VERSION ""

NS_ :

BS_:

BU_: Vector__XXX

BO_ 640 AFE_CellTemperatures: 8 Vector__XXX
SG_ AFE_CellTemperatures_Mux M : 7|8@0+ (1,0) [0|0] "" Vector__XXX
SG_ CellTemperature_000_invalidFlag m0 : 8|1@0+ (1,0) [0|1] "" Vector__XXX
SG_ CellTemperature_001_invalidFlag m0 : 9|1@0+ (1,0) [0|1] "" Vector__XXX
SG_ CellTemperature_002_invalidFlag m0 : 10|1@0+ (1,0) [0|1] "" Vector__XXX
SG_ CellTemperature_003_invalidFlag m0 : 11|1@0+ (1,0) [0|1] "" Vector__XXX
SG_ CellTemperature_004_invalidFlag m0 : 12|1@0+ (1,0) [0|1] "" Vector__XXX
SG_ CellTemperature_005_invalidFlag m0 : 13|1@0+ (1,0) [0|1] "" Vector__XXX
SG_ CellTemperature_000 m0 : 23|8@0- (1,0) [-128|127] "degC" Vector__XXX
SG_ CellTemperature_001 m0 : 31|8@0- (1,0) [-128|127] "degC" Vector__XXX
SG_ CellTemperature_002 m0 : 39|8@0- (1,0) [-128|127] "degC" Vector__XXX
SG_ CellTemperature_003 m0 : 47|8@0- (1,0) [-128|127] "degC" Vector__XXX
SG_ CellTemperature_004 m0 : 55|8@0- (1,0) [-128|127] "degC" Vector__XXX
SG_ CellTemperature_005 m0 : 63|8@0- (1,0) [-128|127] "degC" Vector__XXX
SG_ CellTemperature_006_invalidFlag m1 : 8|1@0+ (1,0) [0|1] "" Vector__XXX
SG_ CellTemperature_007_invalidFlag m1 : 9|1@0+ (1,0) [0|1] "" Vector__XXX
SG_ CellTemperature_008_invalidFlag m1 : 10|1@0+ (1,0) [0|1] "" Vector__XXX
SG_ CellTemperature_009_invalidFlag m1 : 11|1@0+ (1,0) [0|1] "" Vector__XXX
SG_ CellTemperature_010_invalidFlag m1 : 12|1@0+ (1,0) [0|1] "" Vector__XXX
SG_ CellTemperature_011_invalidFlag m1 : 13|1@0+ (1,0) [0|1] "" Vector__XXX
SG_ CellTemperature_006 m1 : 23|8@0- (1,0) [-128|127] "degC" Vector__XXX
SG_ CellTemperature_007 m1 : 31|8@0- (1,0) [-128|127] "degC" Vector__XXX
SG_ CellTemperature_008 m1 : 39|8@0- (1,0) [-128|127] "degC" Vector__XXX
SG_ CellTemperature_009 m1 : 47|8@0- (1,0) [-128|127] "degC" Vector__XXX
SG_ CellTemperature_010 m1 : 55|8@0- (1,0) [-128|127] "degC" Vector__XXX
SG_ CellTemperature_011 m1 : 63|8@0- (1,0) [-128|127] "degC" Vector__XXX
SG_ CellTemperature_012_invalidFlag m2 : 8|1@0+ (1,0) [0|1] "" Vector__XXX
SG_ CellTemperature_013_invalidFlag m2 : 9|1@0+ (1,0) [0|1] "" Vector__XXX
SG_ CellTemperature_014_invalidFlag m2 : 10|1@0+ (1,0) [0|1] "" Vector__XXX
SG_ CellTemperature_015_invalidFlag m2 : 11|1@0+ (1,0) [0|1] "" Vector__XXX
SG_ CellTemperature_016_invalidFlag m2 : 12|1@0+ (1,0) [0|1] "" Vector__XXX
SG_ CellTemperature_017_invalidFlag m2 : 13|1@0+ (1,0) [0|1] "" Vector__XXX
SG_ CellTemperature_012 m2 : 23|8@0- (1,0) [-128|127] "degC" Vector__XXX
SG_ CellTemperature_013 m2 : 31|8@0- (1,0) [-128|127] "degC" Vector__XXX
SG_ CellTemperature_014 m2 : 39|8@0- (1,0) [-128|127] "degC" Vector__XXX
SG_ CellTemperature_015 m2 : 47|8@0- (1,0) [-128|127] "degC" Vector__XXX
SG_ CellTemperature_016 m2 : 55|8@0- (1,0) [-128|127] "degC" Vector__XXX
SG_ CellTemperature_017 m2 : 63|8@0- (1,0) [-128|127] "degC" Vector__XXX
SG_ CellTemperature_018_invalidFlag m3 : 8|1@0+ (1,0) [0|1] "" Vector__XXX
SG_ CellTemperature_019_invalidFlag m3 : 9|1@0+ (1,0) [0|1] "" Vector__XXX
SG_ CellTemperature_020_invalidFlag m3 : 10|1@0+ (1,0) [0|1] "" Vector__XXX
SG_ CellTemperature_021_invalidFlag m3 : 11|1@0+ (1,0) [0|1] "" Vector__XXX
SG_ CellTemperature_022_invalidFlag m3 : 12|1@0+ (1,0) [0|1] "" Vector__XXX
SG_ CellTemperature_023_invalidFlag m3 : 13|1@0+ (1,0) [0|1] "" Vector__XXX
SG_ CellTemperature_018 m3 : 23|8@0- (1,0) [-128|127] "degC" Vector__XXX
SG_ CellTemperature_019 m3 : 31|8@0- (1,0) [-128|127] "degC" Vector__XXX
SG_ CellTemperature_020 m3 : 39|8@0- (1,0) [-128|127] "degC" Vector__XXX
SG_ CellTemperature_021 m3 : 47|8@0- (1,0) [-128|127] "degC" Vector__XXX
SG_ CellTemperature_022 m3 : 55|8@0- (1,0) [-128|127] "degC" Vector__XXX
SG_ CellTemperature_023 m3 : 63|8@0- (1,0) [-128|127] "degC" Vector__XXX
SG_ CellTemperature_024_invalidFlag m4 : 8|1@0+ (1,0) [0|1] "" Vector__XXX
SG_ CellTemperature_025_invalidFlag m4 : 9|1@0+ (1,0) [0|1] "" Vector__XXX
SG_ CellTemperature_026_invalidFlag m4 : 10|1@0+ (1,0) [0|1] "" Vector__XXX
SG_ CellTemperature_027_invalidFlag m4 : 11|1@0+ (1,0) [0|1] "" Vector__XXX
SG_ CellTemperature_028_invalidFlag m4 : 12|1@0+ (1,0) [0|1] "" Vector__XXX
SG_ CellTemperature_029_invalidFlag m4 : 13|1@0+ (1,0) [0|1] "" Vector__XXX
SG_ CellTemperature_024 m4 : 23|8@0- (1,0) [-128|127] "degC" Vector__XXX
SG_ CellTemperature_025 m4 : 31|8@0- (1,0) [-128|127] "degC" Vector__XXX
SG_ CellTemperature_026 m4 : 39|8@0- (1,0) [-128|127] "degC" Vector__XXX
SG_ CellTemperature_027 m4 : 47|8@0- (1,0) [-128|127] "degC" Vector__XXX
SG_ CellTemperature_028 m4 : 55|8@0- (1,0) [-128|127] "degC" Vector__XXX
SG_ CellTemperature_029 m4 : 63|8@0- (1,0) [-128|127] "degC" Vector__XXX
SG_ CellTemperature_030_invalidFlag m5 : 8|1@0+ (1,0) [0|1] "" Vector__XXX
SG_ CellTemperature_031_invalidFlag m5 : 9|1@0+ (1,0) [0|1] "" Vector__XXX
SG_ CellTemperature_032_invalidFlag m5 : 10|1@0+ (1,0) [0|1] "" Vector__XXX
SG_ CellTemperature_033_invalidFlag m5 : 11|1@0+ (1,0) [0|1] "" Vector__XXX
SG_ CellTemperature_034_invalidFlag m5 : 12|1@0+ (1,0) [0|1] "" Vector__XXX
SG_ CellTemperature_035_invalidFlag m5 : 13|1@0+ (1,0) [0|1] "" Vector__XXX
SG_ CellTemperature_030 m5 : 23|8@0- (1,0) [-128|127] "degC" Vector__XXX
SG_ CellTemperature_031 m5 : 31|8@0- (1,0) [-128|127] "degC" Vector__XXX
SG_ CellTemperature_032 m5 : 39|8@0- (1,0) [-128|127] "degC" Vector__XXX
SG_ CellTemperature_033 m5 : 47|8@0- (1,0) [-128|127] "degC" Vector__XXX
SG_ CellTemperature_034 m5 : 55|8@0- (1,0) [-128|127] "degC" Vector__XXX
SG_ CellTemperature_035 m5 : 63|8@0- (1,0) [-128|127] "degC" Vector__XXX
SG_ CellTemperature_036_invalidFlag m6 : 8|1@0+ (1,0) [0|1] "" Vector__XXX
SG_ CellTemperature_037_invalidFlag m6 : 9|1@0+ (1,0) [0|1] "" Vector__XXX
SG_ CellTemperature_038_invalidFlag m6 : 10|1@0+ (1,0) [0|1] "" Vector__XXX
SG_ CellTemperature_039_invalidFlag m6 : 11|1@0+ (1,0) [0|1] "" Vector__XXX
SG_ CellTemperature_040_invalidFlag m6 : 12|1@0+ (1,0) [0|1] "" Vector__XXX
SG_ CellTemperature_041_invalidFlag m6 : 13|1@0+ (1,0) [0|1] "" Vector__XXX
SG_ CellTemperature_036 m6 : 23|8@0- (1,0) [-128|127] "degC" Vector__XXX
SG_ CellTemperature_037 m6 : 31|8@0- (1,0) [-128|127] "degC" Vector__XXX
SG_ CellTemperature_038 m6 : 39|8@0- (1,0) [-128|127] "degC" Vector__XXX
SG_ CellTemperature_039 m6 : 47|8@0- (1,0) [-128|127] "degC" Vector__XXX
SG_ CellTemperature_040 m6 : 55|8@0- (1,0) [-128|127] "degC" Vector__XXX
SG_ CellTemperature_041 m6 : 63|8@0- (1,0) [-128|127] "degC" Vector__XXX
SG_ CellTemperature_042_invalidFlag m7 : 8|1@0+ (1,0) [0|1] "" Vector__XXX
SG_ CellTemperature_043_invalidFlag m7 : 9|1@0+ (1,0) [0|1] "" Vector__XXX
SG_ CellTemperature_044_invalidFlag m7 : 10|1@0+ (1,0) [0|1] "" Vector__XXX
SG_ CellTemperature_045_invalidFlag m7 : 11|1@0+ (1,0) [0|1] "" Vector__XXX
SG_ CellTemperature_046_invalidFlag m7 : 12|1@0+ (1,0) [0|1] "" Vector__XXX
SG_ CellTemperature_047_invalidFlag m7 : 13|1@0+ (1,0) [0|1] "" Vector__XXX
SG_ CellTemperature_042 m7 : 23|8@0- (1,0) [-128|127] "degC" Vector__XXX
SG_ CellTemperature_043 m7 : 31|8@0- (1,0) [-128|127] "degC" Vector__XXX
SG_ CellTemperature_044 m7 : 39|8@0- (1,0) [-128|127] "degC" Vector__XXX
SG_ CellTemperature_045 m7 : 47|8@0- (1,0) [-128|127] "degC" Vector__XXX
SG_ CellTemperature_046 m7 : 55|8@0- (1,0) [-128|127] "degC" Vector__XXX
SG_ CellTemperature_047 m7 : 63|8@0- (1,0) [-128|127] "degC" Vector__XXX
SG_ CellTemperature_048_invalidFlag m8 : 8|1@0+ (1,0) [0|1] "" Vector__XXX
SG_ CellTemperature_049_invalidFlag m8 : 9|1@0+ (1,0) [0|1] "" Vector__XXX
SG_ CellTemperature_050_invalidFlag m8 : 10|1@0+ (1,0) [0|1] "" Vector__XXX
SG_ CellTemperature_051_invalidFlag m8 : 11|1@0+ (1,0) [0|1] "" Vector__XXX
SG_ CellTemperature_052_invalidFlag m8 : 12|1@0+ (1,0) [0|1] "" Vector__XXX
SG_ CellTemperature_053_invalidFlag m8 : 13|1@0+ (1,0) [0|1] "" Vector__XXX
SG_ CellTemperature_048 m8 : 23|8@0- (1,0) [-128|127] "degC" Vector__XXX
SG_ CellTemperature_049 m8 : 31|8@0- (1,0) [-128|127] "degC" Vector__XXX
SG_ CellTemperature_050 m8 : 39|8@0- (1,0) [-128|127] "degC" Vector__XXX
SG_ CellTemperature_051 m8 : 47|8@0- (1,0) [-128|127] "degC" Vector__XXX
SG_ CellTemperature_052 m8 : 55|8@0- (1,0) [-128|127] "degC" Vector__XXX
SG_ CellTemperature_053 m8 : 63|8@0- (1,0) [-128|127] "degC" Vector__XXX
SG_ CellTemperature_054_invalidFlag m9 : 8|1@0+ (1,0) [0|1] "" Vector__XXX
SG_ CellTemperature_055_invalidFlag m9 : 9|1@0+ (1,0) [0|1] "" Vector__XXX
SG_ CellTemperature_056_invalidFlag m9 : 10|1@0+ (1,0) [0|1] "" Vector__XXX
SG_ CellTemperature_057_invalidFlag m9 : 11|1@0+ (1,0) [0|1] "" Vector__XXX
SG_ CellTemperature_058_invalidFlag m9 : 12|1@0+ (1,0) [0|1] "" Vector__XXX
SG_ CellTemperature_059_invalidFlag m9 : 13|1@0+ (1,0) [0|1] "" Vector__XXX
SG_ CellTemperature_054 m9 : 23|8@0- (1,0) [-128|127] "degC" Vector__XXX
SG_ CellTemperature_055 m9 : 31|8@0- (1,0) [-128|127] "degC" Vector__XXX
SG_ CellTemperature_056 m9 : 39|8@0- (1,0) [-128|127] "degC" Vector__XXX
SG_ CellTemperature_057 m9 : 47|8@0- (1,0) [-128|127] "degC" Vector__XXX
SG_ CellTemperature_058 m9 : 55|8@0- (1,0) [-128|127] "degC" Vector__XXX
SG_ CellTemperature_059 m9 : 63|8@0- (1,0) [-128|127] "degC" Vector__XXX
SG_ CellTemperature_060_invalidFlag m10 : 8|1@0+ (1,0) [0|1] "" Vector__XXX
SG_ CellTemperature_061_invalidFlag m10 : 9|1@0+ (1,0) [0|1] "" Vector__XXX
SG_ CellTemperature_062_invalidFlag m10 : 10|1@0+ (1,0) [0|1] "" Vector__XXX
SG_ CellTemperature_063_invalidFlag m10 : 11|1@0+ (1,0) [0|1] "" Vector__XXX
SG_ CellTemperature_064_invalidFlag m10 : 12|1@0+ (1,0) [0|1] "" Vector__XXX
SG_ CellTemperature_065_invalidFlag m10 : 13|1@0+ (1,0) [0|1] "" Vector__XXX
SG_ CellTemperature_060 m10 : 23|8@0- (1,0) [-128|127] "degC" Vector__XXX
SG_ CellTemperature_061 m10 : 31|8@0- (1,0) [-128|127] "degC" Vector__XXX
SG_ CellTemperature_062 m10 : 39|8@0- (1,0) [-128|127] "degC" Vector__XXX
SG_ CellTemperature_063 m10 : 47|8@0- (1,0) [-128|127] "degC" Vector__XXX
SG_ CellTemperature_064 m10 : 55|8@0- (1,0) [-128|127] "degC" Vector__XXX
SG_ CellTemperature_065 m10 : 63|8@0- (1,0) [-128|127] "degC" Vector__XXX
SG_ CellTemperature_066_invalidFlag m11 : 8|1@0+ (1,0) [0|1] "" Vector__XXX
SG_ CellTemperature_067_invalidFlag m11 : 9|1@0+ (1,0) [0|1] "" Vector__XXX
SG_ CellTemperature_068_invalidFlag m11 : 10|1@0+ (1,0) [0|1] "" Vector__XXX
SG_ CellTemperature_069_invalidFlag m11 : 11|1@0+ (1,0) [0|1] "" Vector__XXX
SG_ CellTemperature_070_invalidFlag m11 : 12|1@0+ (1,0) [0|1] "" Vector__XXX
SG_ CellTemperature_071_invalidFlag m11 : 13|1@0+ (1,0) [0|1] "" Vector__XXX
SG_ CellTemperature_066 m11 : 23|8@0- (1,0) [-128|127] "degC" Vector__XXX
SG_ CellTemperature_067 m11 : 31|8@0- (1,0) [-128|127] "degC" Vector__XXX
SG_ CellTemperature_068 m11 : 39|8@0- (1,0) [-128|127] "degC" Vector__XXX
SG_ CellTemperature_069 m11 : 47|8@0- (1,0) [-128|127] "degC" Vector__XXX
SG_ CellTemperature_070 m11 : 55|8@0- (1,0) [-128|127] "degC" Vector__XXX
SG_ CellTemperature_071 m11 : 63|8@0- (1,0) [-128|127] "degC" Vector__XXX
SG_ CellTemperature_072_invalidFlag m12 : 8|1@0+ (1,0) [0|1] "" Vector__XXX
SG_ CellTemperature_073_invalidFlag m12 : 9|1@0+ (1,0) [0|1] "" Vector__XXX
SG_ CellTemperature_074_invalidFlag m12 : 10|1@0+ (1,0) [0|1] "" Vector__XXX
SG_ CellTemperature_075_invalidFlag m12 : 11|1@0+ (1,0) [0|1] "" Vector__XXX
SG_ CellTemperature_076_invalidFlag m12 : 12|1@0+ (1,0) [0|1] "" Vector__XXX
SG_ CellTemperature_077_invalidFlag m12 : 13|1@0+ (1,0) [0|1] "" Vector__XXX
SG_ CellTemperature_072 m12 : 23|8@0- (1,0) [-128|127] "degC" Vector__XXX
SG_ CellTemperature_073 m12 : 31|8@0- (1,0) [-128|127] "degC" Vector__XXX
SG_ CellTemperature_074 m12 : 39|8@0- (1,0) [-128|127] "degC" Vector__XXX
SG_ CellTemperature_075 m12 : 47|8@0- (1,0) [-128|127] "degC" Vector__XXX
SG_ CellTemperature_076 m12 : 55|8@0- (1,0) [-128|127] "degC" Vector__XXX
SG_ CellTemperature_077 m12 : 63|8@0- (1,0) [-128|127] "degC" Vector__XXX
SG_ CellTemperature_078_invalidFlag m13 : 8|1@0+ (1,0) [0|1] "" Vector__XXX
SG_ CellTemperature_079_invalidFlag m13 : 9|1@0+ (1,0) [0|1] "" Vector__XXX
SG_ CellTemperature_080_invalidFlag m13 : 10|1@0+ (1,0) [0|1] "" Vector__XXX
SG_ CellTemperature_081_invalidFlag m13 : 11|1@0+ (1,0) [0|1] "" Vector__XXX
SG_ CellTemperature_082_invalidFlag m13 : 12|1@0+ (1,0) [0|1] "" Vector__XXX
SG_ CellTemperature_083_invalidFlag m13 : 13|1@0+ (1,0) [0|1] "" Vector__XXX
SG_ CellTemperature_078 m13 : 23|8@0- (1,0) [-128|127] "degC" Vector__XXX
SG_ CellTemperature_079 m13 : 31|8@0- (1,0) [-128|127] "degC" Vector__XXX
SG_ CellTemperature_080 m13 : 39|8@0- (1,0) [-128|127] "degC" Vector__XXX
SG_ CellTemperature_081 m13 : 47|8@0- (1,0) [-128|127] "degC" Vector__XXX
SG_ CellTemperature_082 m13 : 55|8@0- (1,0) [-128|127] "degC" Vector__XXX
SG_ CellTemperature_083 m13 : 63|8@0- (1,0) [-128|127] "degC" Vector__XXX
SG_ CellTemperature_084_invalidFlag m14 : 8|1@0+ (1,0) [0|1] "" Vector__XXX
SG_ CellTemperature_085_invalidFlag m14 : 9|1@0+ (1,0) [0|1] "" Vector__XXX
SG_ CellTemperature_086_invalidFlag m14 : 10|1@0+ (1,0) [0|1] "" Vector__XXX
SG_ CellTemperature_087_invalidFlag m14 : 11|1@0+ (1,0) [0|1] "" Vector__XXX
SG_ CellTemperature_088_invalidFlag m14 : 12|1@0+ (1,0) [0|1] "" Vector__XXX
SG_ CellTemperature_089_invalidFlag m14 : 13|1@0+ (1,0) [0|1] "" Vector__XXX
SG_ CellTemperature_084 m14 : 23|8@0- (1,0) [-128|127] "degC" Vector__XXX
SG_ CellTemperature_085 m14 : 31|8@0- (1,0) [-128|127] "degC" Vector__XXX
SG_ CellTemperature_086 m14 : 39|8@0- (1,0) [-128|127] "degC" Vector__XXX
SG_ CellTemperature_087 m14 : 47|8@0- (1,0) [-128|127] "degC" Vector__XXX
SG_ CellTemperature_088 m14 : 55|8@0- (1,0) [-128|127] "degC" Vector__XXX
SG_ CellTemperature_089 m14 : 63|8@0- (1,0) [-128|127] "degC" Vector__XXX
SG_ CellTemperature_090_invalidFlag m15 : 8|1@0+ (1,0) [0|1] "" Vector__XXX
SG_ CellTemperature_091_invalidFlag m15 : 9|1@0+ (1,0) [0|1] "" Vector__XXX
SG_ CellTemperature_092_invalidFlag m15 : 10|1@0+ (1,0) [0|1] "" Vector__XXX
SG_ CellTemperature_093_invalidFlag m15 : 11|1@0+ (1,0) [0|1] "" Vector__XXX
SG_ CellTemperature_094_invalidFlag m15 : 12|1@0+ (1,0) [0|1] "" Vector__XXX
SG_ CellTemperature_095_invalidFlag m15 : 13|1@0+ (1,0) [0|1] "" Vector__XXX
SG_ CellTemperature_090 m15 : 23|8@0- (1,0) [-128|127] "degC" Vector__XXX
SG_ CellTemperature_091 m15 : 31|8@0- (1,0) [-128|127] "degC" Vector__XXX
SG_ CellTemperature_092 m15 : 39|8@0- (1,0) [-128|127] "degC" Vector__XXX
SG_ CellTemperature_093 m15 : 47|8@0- (1,0) [-128|127] "degC" Vector__XXX
SG_ CellTemperature_094 m15 : 55|8@0- (1,0) [-128|127] "degC" Vector__XXX
SG_ CellTemperature_095 m15 : 63|8@0- (1,0) [-128|127] "degC" Vector__XXX
SG_ CellTemperature_096_invalidFlag m16 : 8|1@0+ (1,0) [0|1] "" Vector__XXX
SG_ CellTemperature_097_invalidFlag m16 : 9|1@0+ (1,0) [0|1] "" Vector__XXX
SG_ CellTemperature_098_invalidFlag m16 : 10|1@0+ (1,0) [0|1] "" Vector__XXX
SG_ CellTemperature_099_invalidFlag m16 : 11|1@0+ (1,0) [0|1] "" Vector__XXX
SG_ CellTemperature_100_invalidFlag m16 : 12|1@0+ (1,0) [0|1] "" Vector__XXX
SG_ CellTemperature_101_invalidFlag m16 : 13|1@0+ (1,0) [0|1] "" Vector__XXX
SG_ CellTemperature_096 m16 : 23|8@0- (1,0) [-128|127] "degC" Vector__XXX
SG_ CellTemperature_097 m16 : 31|8@0- (1,0) [-128|127] "degC" Vector__XXX
SG_ CellTemperature_098 m16 : 39|8@0- (1,0) [-128|127] "degC" Vector__XXX
SG_ CellTemperature_099 m16 : 47|8@0- (1,0) [-128|127] "degC" Vector__XXX
SG_ CellTemperature_100 m16 : 55|8@0- (1,0) [-128|127] "degC" Vector__XXX
SG_ CellTemperature_101 m16 : 63|8@0- (1,0) [-128|127] "degC" Vector__XXX
SG_ CellTemperature_102_invalidFlag m17 : 8|1@0+ (1,0) [0|1] "" Vector__XXX
SG_ CellTemperature_103_invalidFlag m17 : 9|1@0+ (1,0) [0|1] "" Vector__XXX
SG_ CellTemperature_104_invalidFlag m17 : 10|1@0+ (1,0) [0|1] "" Vector__XXX
SG_ CellTemperature_105_invalidFlag m17 : 11|1@0+ (1,0) [0|1] "" Vector__XXX
SG_ CellTemperature_106_invalidFlag m17 : 12|1@0+ (1,0) [0|1] "" Vector__XXX
SG_ CellTemperature_107_invalidFlag m17 : 13|1@0+ (1,0) [0|1] "" Vector__XXX
SG_ CellTemperature_102 m17 : 23|8@0- (1,0) [-128|127] "degC" Vector__XXX
SG_ CellTemperature_103 m17 : 31|8@0- (1,0) [-128|127] "degC" Vector__XXX
SG_ CellTemperature_104 m17 : 39|8@0- (1,0) [-128|127] "degC" Vector__XXX
SG_ CellTemperature_105 m17 : 47|8@0- (1,0) [-128|127] "degC" Vector__XXX
SG_ CellTemperature_106 m17 : 55|8@0- (1,0) [-128|127] "degC" Vector__XXX
SG_ CellTemperature_107 m17 : 63|8@0- (1,0) [-128|127] "degC" Vector__XXX
SG_ CellTemperature_108_invalidFlag m18 : 8|1@0+ (1,0) [0|1] "" Vector__XXX
SG_ CellTemperature_109_invalidFlag m18 : 9|1@0+ (1,0) [0|1] "" Vector__XXX
SG_ CellTemperature_110_invalidFlag m18 : 10|1@0+ (1,0) [0|1] "" Vector__XXX
SG_ CellTemperature_111_invalidFlag m18 : 11|1@0+ (1,0) [0|1] "" Vector__XXX
SG_ CellTemperature_112_invalidFlag m18 : 12|1@0+ (1,0) [0|1] "" Vector__XXX
SG_ CellTemperature_113_invalidFlag m18 : 13|1@0+ (1,0) [0|1] "" Vector__XXX
SG_ CellTemperature_108 m18 : 23|8@0- (1,0) [-128|127] "degC" Vector__XXX
SG_ CellTemperature_109 m18 : 31|8@0- (1,0) [-128|127] "degC" Vector__XXX
SG_ CellTemperature_110 m18 : 39|8@0- (1,0) [-128|127] "degC" Vector__XXX
SG_ CellTemperature_111 m18 : 47|8@0- (1,0) [-128|127] "degC" Vector__XXX
SG_ CellTemperature_112 m18 : 55|8@0- (1,0) [-128|127] "degC" Vector__XXX
SG_ CellTemperature_113 m18 : 63|8@0- (1,0) [-128|127] "degC" Vector__XXX
SG_ CellTemperature_114_invalidFlag m19 : 8|1@0+ (1,0) [0|1] "" Vector__XXX
SG_ CellTemperature_115_invalidFlag m19 : 9|1@0+ (1,0) [0|1] "" Vector__XXX
SG_ CellTemperature_116_invalidFlag m19 : 10|1@0+ (1,0) [0|1] "" Vector__XXX
SG_ CellTemperature_117_invalidFlag m19 : 11|1@0+ (1,0) [0|1] "" Vector__XXX
SG_ CellTemperature_118_invalidFlag m19 : 12|1@0+ (1,0) [0|1] "" Vector__XXX
SG_ CellTemperature_119_invalidFlag m19 : 13|1@0+ (1,0) [0|1] "" Vector__XXX
SG_ CellTemperature_114 m19 : 23|8@0- (1,0) [-128|127] "degC" Vector__XXX
SG_ CellTemperature_115 m19 : 31|8@0- (1,0) [-128|127] "degC" Vector__XXX
SG_ CellTemperature_116 m19 : 39|8@0- (1,0) [-128|127] "degC" Vector__XXX
SG_ CellTemperature_117 m19 : 47|8@0- (1,0) [-128|127] "degC" Vector__XXX
SG_ CellTemperature_118 m19 : 55|8@0- (1,0) [-128|127] "degC" Vector__XXX
SG_ CellTemperature_119 m19 : 63|8@0- (1,0) [-128|127] "degC" Vector__XXX
SG_ CellTemperature_120_invalidFlag m20 : 8|1@0+ (1,0) [0|1] "" Vector__XXX
SG_ CellTemperature_121_invalidFlag m20 : 9|1@0+ (1,0) [0|1] "" Vector__XXX
SG_ CellTemperature_122_invalidFlag m20 : 10|1@0+ (1,0) [0|1] "" Vector__XXX
SG_ CellTemperature_123_invalidFlag m20 : 11|1@0+ (1,0) [0|1] "" Vector__XXX
SG_ CellTemperature_124_invalidFlag m20 : 12|1@0+ (1,0) [0|1] "" Vector__XXX
SG_ CellTemperature_125_invalidFlag m20 : 13|1@0+ (1,0) [0|1] "" Vector__XXX
SG_ CellTemperature_120 m20 : 23|8@0- (1,0) [-128|127] "degC" Vector__XXX
SG_ CellTemperature_121 m20 : 31|8@0- (1,0) [-128|127] "degC" Vector__XXX
SG_ CellTemperature_122 m20 : 39|8@0- (1,0) [-128|127] "degC" Vector__XXX
SG_ CellTemperature_123 m20 : 47|8@0- (1,0) [-128|127] "degC" Vector__XXX
SG_ CellTemperature_124 m20 : 55|8@0- (1,0) [-128|127] "degC" Vector__XXX
SG_ CellTemperature_125 m20 : 63|8@0- (1,0) [-128|127] "degC" Vector__XXX
SG_ CellTemperature_126_invalidFlag m21 : 8|1@0+ (1,0) [0|1] "" Vector__XXX
SG_ CellTemperature_127_invalidFlag m21 : 9|1@0+ (1,0) [0|1] "" Vector__XXX
SG_ CellTemperature_128_invalidFlag m21 : 10|1@0+ (1,0) [0|1] "" Vector__XXX
SG_ CellTemperature_129_invalidFlag m21 : 11|1@0+ (1,0) [0|1] "" Vector__XXX
SG_ CellTemperature_130_invalidFlag m21 : 12|1@0+ (1,0) [0|1] "" Vector__XXX
SG_ CellTemperature_131_invalidFlag m21 : 13|1@0+ (1,0) [0|1] "" Vector__XXX
SG_ CellTemperature_126 m21 : 23|8@0- (1,0) [-128|127] "degC" Vector__XXX
SG_ CellTemperature_127 m21 : 31|8@0- (1,0) [-128|127] "degC" Vector__XXX
SG_ CellTemperature_128 m21 : 39|8@0- (1,0) [-128|127] "degC" Vector__XXX
SG_ CellTemperature_129 m21 : 47|8@0- (1,0) [-128|127] "degC" Vector__XXX
SG_ CellTemperature_130 m21 : 55|8@0- (1,0) [-128|127] "degC" Vector__XXX
SG_ CellTemperature_131 m21 : 63|8@0- (1,0) [-128|127] "degC" Vector__XXX
SG_ CellTemperature_132_invalidFlag m22 : 8|1@0+ (1,0) [0|1] "" Vector__XXX
SG_ CellTemperature_133_invalidFlag m22 : 9|1@0+ (1,0) [0|1] "" Vector__XXX
SG_ CellTemperature_134_invalidFlag m22 : 10|1@0+ (1,0) [0|1] "" Vector__XXX
SG_ CellTemperature_135_invalidFlag m22 : 11|1@0+ (1,0) [0|1] "" Vector__XXX
SG_ CellTemperature_136_invalidFlag m22 : 12|1@0+ (1,0) [0|1] "" Vector__XXX
SG_ CellTemperature_137_invalidFlag m22 : 13|1@0+ (1,0) [0|1] "" Vector__XXX
SG_ CellTemperature_132 m22 : 23|8@0- (1,0) [-128|127] "degC" Vector__XXX
SG_ CellTemperature_133 m22 : 31|8@0- (1,0) [-128|127] "degC" Vector__XXX
SG_ CellTemperature_134 m22 : 39|8@0- (1,0) [-128|127] "degC" Vector__XXX
SG_ CellTemperature_135 m22 : 47|8@0- (1,0) [-128|127] "degC" Vector__XXX
SG_ CellTemperature_136 m22 : 55|8@0- (1,0) [-128|127] "degC" Vector__XXX
SG_ CellTemperature_137 m22 : 63|8@0- (1,0) [-128|127] "degC" Vector__XXX
SG_ CellTemperature_138_invalidFlag m23 : 8|1@0+ (1,0) [0|1] "" Vector__XXX
SG_ CellTemperature_139_invalidFlag m23 : 9|1@0+ (1,0) [0|1] "" Vector__XXX
SG_ CellTemperature_140_invalidFlag m23 : 10|1@0+ (1,0) [0|1] "" Vector__XXX
SG_ CellTemperature_141_invalidFlag m23 : 11|1@0+ (1,0) [0|1] "" Vector__XXX
SG_ CellTemperature_142_invalidFlag m23 : 12|1@0+ (1,0) [0|1] "" Vector__XXX
SG_ CellTemperature_143_invalidFlag m23 : 13|1@0+ (1,0) [0|1] "" Vector__XXX
SG_ CellTemperature_138 m23 : 23|8@0- (1,0) [-128|127] "degC" Vector__XXX
SG_ CellTemperature_139 m23 : 31|8@0- (1,0) [-128|127] "degC" Vector__XXX
SG_ CellTemperature_140 m23 : 39|8@0- (1,0) [-128|127] "degC" Vector__XXX
SG_ CellTemperature_141 m23 : 47|8@0- (1,0) [-128|127] "degC" Vector__XXX
SG_ CellTemperature_142 m23 : 55|8@0- (1,0) [-128|127] "degC" Vector__XXX
SG_ CellTemperature_143 m23 : 63|8@0- (1,0) [-128|127] "degC" Vector__XXX
SG_ CellTemperature_144_invalidFlag m24 : 8|1@0+ (1,0) [0|1] "" Vector__XXX
SG_ CellTemperature_145_invalidFlag m24 : 9|1@0+ (1,0) [0|1] "" Vector__XXX
SG_ CellTemperature_146_invalidFlag m24 : 10|1@0+ (1,0) [0|1] "" Vector__XXX
SG_ CellTemperature_147_invalidFlag m24 : 11|1@0+ (1,0) [0|1] "" Vector__XXX
SG_ CellTemperature_148_invalidFlag m24 : 12|1@0+ (1,0) [0|1] "" Vector__XXX
SG_ CellTemperature_149_invalidFlag m24 : 13|1@0+ (1,0) [0|1] "" Vector__XXX
SG_ CellTemperature_144 m24 : 23|8@0- (1,0) [-128|127] "degC" Vector__XXX
SG_ CellTemperature_145 m24 : 31|8@0- (1,0) [-128|127] "degC" Vector__XXX
SG_ CellTemperature_146 m24 : 39|8@0- (1,0) [-128|127] "degC" Vector__XXX
SG_ CellTemperature_147 m24 : 47|8@0- (1,0) [-128|127] "degC" Vector__XXX
SG_ CellTemperature_148 m24 : 55|8@0- (1,0) [-128|127] "degC" Vector__XXX
SG_ CellTemperature_149 m24 : 63|8@0- (1,0) [-128|127] "degC" Vector__XXX
SG_ CellTemperature_150_invalidFlag m25 : 8|1@0+ (1,0) [0|1] "" Vector__XXX
SG_ CellTemperature_151_invalidFlag m25 : 9|1@0+ (1,0) [0|1] "" Vector__XXX
SG_ CellTemperature_152_invalidFlag m25 : 10|1@0+ (1,0) [0|1] "" Vector__XXX
SG_ CellTemperature_153_invalidFlag m25 : 11|1@0+ (1,0) [0|1] "" Vector__XXX
SG_ CellTemperature_154_invalidFlag m25 : 12|1@0+ (1,0) [0|1] "" Vector__XXX
SG_ CellTemperature_155_invalidFlag m25 : 13|1@0+ (1,0) [0|1] "" Vector__XXX
SG_ CellTemperature_150 m25 : 23|8@0- (1,0) [-128|127] "degC" Vector__XXX
SG_ CellTemperature_151 m25 : 31|8@0- (1,0) [-128|127] "degC" Vector__XXX
SG_ CellTemperature_152 m25 : 39|8@0- (1,0) [-128|127] "degC" Vector__XXX
SG_ CellTemperature_153 m25 : 47|8@0- (1,0) [-128|127] "degC" Vector__XXX
SG_ CellTemperature_154 m25 : 55|8@0- (1,0) [-128|127] "degC" Vector__XXX
SG_ CellTemperature_155 m25 : 63|8@0- (1,0) [-128|127] "degC" Vector__XXX
SG_ CellTemperature_156_invalidFlag m26 : 8|1@0+ (1,0) [0|1] "" Vector__XXX
SG_ CellTemperature_157_invalidFlag m26 : 9|1@0+ (1,0) [0|1] "" Vector__XXX
SG_ CellTemperature_158_invalidFlag m26 : 10|1@0+ (1,0) [0|1] "" Vector__XXX
SG_ CellTemperature_159_invalidFlag m26 : 11|1@0+ (1,0) [0|1] "" Vector__XXX
SG_ CellTemperature_160_invalidFlag m26 : 12|1@0+ (1,0) [0|1] "" Vector__XXX
SG_ CellTemperature_161_invalidFlag m26 : 13|1@0+ (1,0) [0|1] "" Vector__XXX
SG_ CellTemperature_156 m26 : 23|8@0- (1,0) [-128|127] "degC" Vector__XXX
SG_ CellTemperature_157 m26 : 31|8@0- (1,0) [-128|127] "degC" Vector__XXX
SG_ CellTemperature_158 m26 : 39|8@0- (1,0) [-128|127] "degC" Vector__XXX
SG_ CellTemperature_159 m26 : 47|8@0- (1,0) [-128|127] "degC" Vector__XXX
SG_ CellTemperature_160 m26 : 55|8@0- (1,0) [-128|127] "degC" Vector__XXX
SG_ CellTemperature_161 m26 : 63|8@0- (1,0) [-128|127] "degC" Vector__XXX
SG_ CellTemperature_162_invalidFlag m27 : 8|1@0+ (1,0) [0|1] "" Vector__XXX
SG_ CellTemperature_163_invalidFlag m27 : 9|1@0+ (1,0) [0|1] "" Vector__XXX
SG_ CellTemperature_164_invalidFlag m27 : 10|1@0+ (1,0) [0|1] "" Vector__XXX
SG_ CellTemperature_165_invalidFlag m27 : 11|1@0+ (1,0) [0|1] "" Vector__XXX
SG_ CellTemperature_166_invalidFlag m27 : 12|1@0+ (1,0) [0|1] "" Vector__XXX
SG_ CellTemperature_167_invalidFlag m27 : 13|1@0+ (1,0) [0|1] "" Vector__XXX
SG_ CellTemperature_162 m27 : 23|8@0- (1,0) [-128|127] "degC" Vector__XXX
SG_ CellTemperature_163 m27 : 31|8@0- (1,0) [-128|127] "degC" Vector__XXX
SG_ CellTemperature_164 m27 : 39|8@0- (1,0) [-128|127] "degC" Vector__XXX
SG_ CellTemperature_165 m27 : 47|8@0- (1,0) [-128|127] "degC" Vector__XXX
SG_ CellTemperature_166 m27 : 55|8@0- (1,0) [-128|127] "degC" Vector__XXX
SG_ CellTemperature_167 m27 : 63|8@0- (1,0) [-128|127] "degC" Vector__XXX
SG_ CellTemperature_168_invalidFlag m28 : 8|1@0+ (1,0) [0|1] "" Vector__XXX
SG_ CellTemperature_169_invalidFlag m28 : 9|1@0+ (1,0) [0|1] "" Vector__XXX
SG_ CellTemperature_170_invalidFlag m28 : 10|1@0+ (1,0) [0|1] "" Vector__XXX
SG_ CellTemperature_171_invalidFlag m28 : 11|1@0+ (1,0) [0|1] "" Vector__XXX
SG_ CellTemperature_172_invalidFlag m28 : 12|1@0+ (1,0) [0|1] "" Vector__XXX
SG_ CellTemperature_173_invalidFlag m28 : 13|1@0+ (1,0) [0|1] "" Vector__XXX
SG_ CellTemperature_168 m28 : 23|8@0- (1,0) [-128|127] "degC" Vector__XXX
SG_ CellTemperature_169 m28 : 31|8@0- (1,0) [-128|127] "degC" Vector__XXX
SG_ CellTemperature_170 m28 : 39|8@0- (1,0) [-128|127] "degC" Vector__XXX
SG_ CellTemperature_171 m28 : 47|8@0- (1,0) [-128|127] "degC" Vector__XXX
SG_ CellTemperature_172 m28 : 55|8@0- (1,0) [-128|127] "degC" Vector__XXX
SG_ CellTemperature_173 m28 : 63|8@0- (1,0) [-128|127] "degC" Vector__XXX
SG_ CellTemperature_174_invalidFlag m29 : 8|1@0+ (1,0) [0|1] "" Vector__XXX
SG_ CellTemperature_175_invalidFlag m29 : 9|1@0+ (1,0) [0|1] "" Vector__XXX
SG_ CellTemperature_176_invalidFlag m29 : 10|1@0+ (1,0) [0|1] "" Vector__XXX
SG_ CellTemperature_177_invalidFlag m29 : 11|1@0+ (1,0) [0|1] "" Vector__XXX
SG_ CellTemperature_178_invalidFlag m29 : 12|1@0+ (1,0) [0|1] "" Vector__XXX
SG_ CellTemperature_179_invalidFlag m29 : 13|1@0+ (1,0) [0|1] "" Vector__XXX
SG_ CellTemperature_174 m29 : 23|8@0- (1,0) [-128|127] "degC" Vector__XXX
SG_ CellTemperature_175 m29 : 31|8@0- (1,0) [-128|127] "degC" Vector__XXX
SG_ CellTemperature_176 m29 : 39|8@0- (1,0) [-128|127] "degC" Vector__XXX
SG_ CellTemperature_177 m29 : 47|8@0- (1,0) [-128|127] "degC" Vector__XXX
SG_ CellTemperature_178 m29 : 55|8@0- (1,0) [-128|127] "degC" Vector__XXX
SG_ CellTemperature_179 m29 : 63|8@0- (1,0) [-128|127] "degC" Vector__XXX

BO_ 624 AFE_CellVoltages: 8 Vector__XXX
SG_ AFE_CellVoltages_Mux M : 7|8@0+ (1,0) [0|0] "" Vector__XXX
SG_ CellVoltage_000_invalidFlag m0 : 12|1@0+ (1,0) [0|1] "" Vector__XXX
SG_ CellVoltage_001_invalidFlag m0 : 13|1@0+ (1,0) [0|1] "" Vector__XXX
SG_ CellVoltage_002_invalidFlag m0 : 14|1@0+ (1,0) [0|1] "" Vector__XXX
SG_ CellVoltage_003_invalidFlag m0 : 15|1@0+ (1,0) [0|1] "" Vector__XXX
SG_ CellVoltage_000 m0 : 11|13@0+ (1,0) [0|8191] "mV" Vector__XXX
SG_ CellVoltage_001 m0 : 30|13@0+ (1,0) [0|8191] "mV" Vector__XXX
SG_ CellVoltage_002 m0 : 33|13@0+ (1,0) [0|8191] "mV" Vector__XXX
SG_ CellVoltage_003 m0 : 52|13@0+ (1,0) [0|8191] "mV" Vector__XXX
SG_ CellVoltage_004_invalidFlag m1 : 12|1@0+ (1,0) [0|1] "" Vector__XXX
SG_ CellVoltage_005_invalidFlag m1 : 13|1@0+ (1,0) [0|1] "" Vector__XXX
SG_ CellVoltage_006_invalidFlag m1 : 14|1@0+ (1,0) [0|1] "" Vector__XXX
SG_ CellVoltage_007_invalidFlag m1 : 15|1@0+ (1,0) [0|1] "" Vector__XXX
SG_ CellVoltage_004 m1 : 11|13@0+ (1,0) [0|8191] "mV" Vector__XXX
SG_ CellVoltage_005 m1 : 30|13@0+ (1,0) [0|8191] "mV" Vector__XXX
SG_ CellVoltage_006 m1 : 33|13@0+ (1,0) [0|8191] "mV" Vector__XXX
SG_ CellVoltage_007 m1 : 52|13@0+ (1,0) [0|8191] "mV" Vector__XXX
SG_ CellVoltage_008_invalidFlag m2 : 12|1@0+ (1,0) [0|1] "" Vector__XXX
SG_ CellVoltage_009_invalidFlag m2 : 13|1@0+ (1,0) [0|1] "" Vector__XXX
SG_ CellVoltage_010_invalidFlag m2 : 14|1@0+ (1,0) [0|1] "" Vector__XXX
SG_ CellVoltage_011_invalidFlag m2 : 15|1@0+ (1,0) [0|1] "" Vector__XXX
SG_ CellVoltage_008 m2 : 11|13@0+ (1,0) [0|8191] "mV" Vector__XXX
SG_ CellVoltage_009 m2 : 30|13@0+ (1,0) [0|8191] "mV" Vector__XXX
SG_ CellVoltage_010 m2 : 33|13@0+ (1,0) [0|8191] "mV" Vector__XXX
SG_ CellVoltage_011 m2 : 52|13@0+ (1,0) [0|8191] "mV" Vector__XXX
SG_ CellVoltage_012_invalidFlag m3 : 12|1@0+ (1,0) [0|1] "" Vector__XXX
SG_ CellVoltage_013_invalidFlag m3 : 13|1@0+ (1,0) [0|1] "" Vector__XXX
SG_ CellVoltage_014_invalidFlag m3 : 14|1@0+ (1,0) [0|1] "" Vector__XXX
SG_ CellVoltage_015_invalidFlag m3 : 15|1@0+ (1,0) [0|1] "" Vector__XXX
SG_ CellVoltage_012 m3 : 11|13@0+ (1,0) [0|8191] "mV" Vector__XXX
SG_ CellVoltage_013 m3 : 30|13@0+ (1,0) [0|8191] "mV" Vector__XXX
SG_ CellVoltage_014 m3 : 33|13@0+ (1,0) [0|8191] "mV" Vector__XXX
SG_ CellVoltage_015 m3 : 52|13@0+ (1,0) [0|8191] "mV" Vector__XXX
SG_ CellVoltage_016_invalidFlag m4 : 12|1@0+ (1,0) [0|1] "" Vector__XXX
SG_ CellVoltage_017_invalidFlag m4 : 13|1@0+ (1,0) [0|1] "" Vector__XXX
SG_ CellVoltage_018_invalidFlag m4 : 14|1@0+ (1,0) [0|1] "" Vector__XXX
SG_ CellVoltage_019_invalidFlag m4 : 15|1@0+ (1,0) [0|1] "" Vector__XXX
SG_ CellVoltage_016 m4 : 11|13@0+ (1,0) [0|8191] "mV" Vector__XXX
SG_ CellVoltage_017 m4 : 30|13@0+ (1,0) [0|8191] "mV" Vector__XXX
SG_ CellVoltage_018 m4 : 33|13@0+ (1,0) [0|8191] "mV" Vector__XXX
SG_ CellVoltage_019 m4 : 52|13@0+ (1,0) [0|8191] "mV" Vector__XXX
SG_ CellVoltage_020_invalidFlag m5 : 12|1@0+ (1,0) [0|1] "" Vector__XXX
SG_ CellVoltage_021_invalidFlag m5 : 13|1@0+ (1,0) [0|1] "" Vector__XXX
SG_ CellVoltage_022_invalidFlag m5 : 14|1@0+ (1,0) [0|1] "" Vector__XXX
SG_ CellVoltage_023_invalidFlag m5 : 15|1@0+ (1,0) [0|1] "" Vector__XXX
SG_ CellVoltage_020 m5 : 11|13@0+ (1,0) [0|8191] "mV" Vector__XXX
SG_ CellVoltage_021 m5 : 30|13@0+ (1,0) [0|8191] "mV" Vector__XXX
SG_ CellVoltage_022 m5 : 33|13@0+ (1,0) [0|8191] "mV" Vector__XXX
SG_ CellVoltage_023 m5 : 52|13@0+ (1,0) [0|8191] "mV" Vector__XXX
SG_ CellVoltage_024_invalidFlag m6 : 12|1@0+ (1,0) [0|1] "" Vector__XXX
SG_ CellVoltage_025_invalidFlag m6 : 13|1@0+ (1,0) [0|1] "" Vector__XXX
SG_ CellVoltage_026_invalidFlag m6 : 14|1@0+ (1,0) [0|1] "" Vector__XXX
SG_ CellVoltage_027_invalidFlag m6 : 15|1@0+ (1,0) [0|1] "" Vector__XXX
SG_ CellVoltage_024 m6 : 11|13@0+ (1,0) [0|8191] "mV" Vector__XXX
SG_ CellVoltage_025 m6 : 30|13@0+ (1,0) [0|8191] "mV" Vector__XXX
SG_ CellVoltage_026 m6 : 33|13@0+ (1,0) [0|8191] "mV" Vector__XXX
SG_ CellVoltage_027 m6 : 52|13@0+ (1,0) [0|8191] "mV" Vector__XXX
SG_ CellVoltage_028_invalidFlag m7 : 12|1@0+ (1,0) [0|1] "" Vector__XXX
SG_ CellVoltage_029_invalidFlag m7 : 13|1@0+ (1,0) [0|1] "" Vector__XXX
SG_ CellVoltage_030_invalidFlag m7 : 14|1@0+ (1,0) [0|1] "" Vector__XXX
SG_ CellVoltage_031_invalidFlag m7 : 15|1@0+ (1,0) [0|1] "" Vector__XXX
SG_ CellVoltage_028 m7 : 11|13@0+ (1,0) [0|8191] "mV" Vector__XXX
SG_ CellVoltage_029 m7 : 30|13@0+ (1,0) [0|8191] "mV" Vector__XXX
SG_ CellVoltage_030 m7 : 33|13@0+ (1,0) [0|8191] "mV" Vector__XXX
SG_ CellVoltage_031 m7 : 52|13@0+ (1,0) [0|8191] "mV" Vector__XXX
SG_ CellVoltage_032_invalidFlag m8 : 12|1@0+ (1,0) [0|1] "" Vector__XXX
SG_ CellVoltage_033_invalidFlag m8 : 13|1@0+ (1,0) [0|1] "" Vector__XXX
SG_ CellVoltage_034_invalidFlag m8 : 14|1@0+ (1,0) [0|1] "" Vector__XXX
SG_ CellVoltage_035_invalidFlag m8 : 15|1@0+ (1,0) [0|1] "" Vector__XXX
SG_ CellVoltage_032 m8 : 11|13@0+ (1,0) [0|8191] "mV" Vector__XXX
SG_ CellVoltage_033 m8 : 30|13@0+ (1,0) [0|8191] "mV" Vector__XXX
SG_ CellVoltage_034 m8 : 33|13@0+ (1,0) [0|8191] "mV" Vector__XXX
SG_ CellVoltage_035 m8 : 52|13@0+ (1,0) [0|8191] "mV" Vector__XXX
SG_ CellVoltage_036_invalidFlag m9 : 12|1@0+ (1,0) [0|1] "" Vector__XXX
SG_ CellVoltage_037_invalidFlag m9 : 13|1@0+ (1,0) [0|1] "" Vector__XXX
SG_ CellVoltage_038_invalidFlag m9 : 14|1@0+ (1,0) [0|1] "" Vector__XXX
SG_ CellVoltage_039_invalidFlag m9 : 15|1@0+ (1,0) [0|1] "" Vector__XXX
SG_ CellVoltage_036 m9 : 11|13@0+ (1,0) [0|8191] "mV" Vector__XXX
SG_ CellVoltage_037 m9 : 30|13@0+ (1,0) [0|8191] "mV" Vector__XXX
SG_ CellVoltage_038 m9 : 33|13@0+ (1,0) [0|8191] "mV" Vector__XXX
SG_ CellVoltage_039 m9 : 52|13@0+ (1,0) [0|8191] "mV" Vector__XXX
SG_ CellVoltage_040_invalidFlag m10 : 12|1@0+ (1,0) [0|1] "" Vector__XXX
SG_ CellVoltage_041_invalidFlag m10 : 13|1@0+ (1,0) [0|1] "" Vector__XXX
SG_ CellVoltage_042_invalidFlag m10 : 14|1@0+ (1,0) [0|1] "" Vector__XXX
SG_ CellVoltage_043_invalidFlag m10 : 15|1@0+ (1,0) [0|1] "" Vector__XXX
SG_ CellVoltage_040 m10 : 11|13@0+ (1,0) [0|8191] "mV" Vector__XXX
SG_ CellVoltage_041 m10 : 30|13@0+ (1,0) [0|8191] "mV" Vector__XXX
SG_ CellVoltage_042 m10 : 33|13@0+ (1,0) [0|8191] "mV" Vector__XXX
SG_ CellVoltage_043 m10 : 52|13@0+ (1,0) [0|8191] "mV" Vector__XXX
SG_ CellVoltage_044_invalidFlag m11 : 12|1@0+ (1,0) [0|1] "" Vector__XXX
SG_ CellVoltage_045_invalidFlag m11 : 13|1@0+ (1,0) [0|1] "" Vector__XXX
SG_ CellVoltage_046_invalidFlag m11 : 14|1@0+ (1,0) [0|1] "" Vector__XXX
SG_ CellVoltage_047_invalidFlag m11 : 15|1@0+ (1,0) [0|1] "" Vector__XXX
SG_ CellVoltage_044 m11 : 11|13@0+ (1,0) [0|8191] "mV" Vector__XXX
SG_ CellVoltage_045 m11 : 30|13@0+ (1,0) [0|8191] "mV" Vector__XXX
SG_ CellVoltage_046 m11 : 33|13@0+ (1,0) [0|8191] "mV" Vector__XXX
SG_ CellVoltage_047 m11 : 52|13@0+ (1,0) [0|8191] "mV" Vector__XXX
SG_ CellVoltage_048_invalidFlag m12 : 12|1@0+ (1,0) [0|1] "" Vector__XXX
SG_ CellVoltage_049_invalidFlag m12 : 13|1@0+ (1,0) [0|1] "" Vector__XXX
SG_ CellVoltage_050_invalidFlag m12 : 14|1@0+ (1,0) [0|1] "" Vector__XXX
SG_ CellVoltage_051_invalidFlag m12 : 15|1@0+ (1,0) [0|1] "" Vector__XXX
SG_ CellVoltage_048 m12 : 11|13@0+ (1,0) [0|8191] "mV" Vector__XXX
SG_ CellVoltage_049 m12 : 30|13@0+ (1,0) [0|8191] "mV" Vector__XXX
SG_ CellVoltage_050 m12 : 33|13@0+ (1,0) [0|8191] "mV" Vector__XXX
SG_ CellVoltage_051 m12 : 52|13@0+ (1,0) [0|8191] "mV" Vector__XXX
SG_ CellVoltage_052_invalidFlag m13 : 12|1@0+ (1,0) [0|1] "" Vector__XXX
SG_ CellVoltage_053_invalidFlag m13 : 13|1@0+ (1,0) [0|1] "" Vector__XXX
SG_ CellVoltage_054_invalidFlag m13 : 14|1@0+ (1,0) [0|1] "" Vector__XXX
SG_ CellVoltage_055_invalidFlag m13 : 15|1@0+ (1,0) [0|1] "" Vector__XXX
SG_ CellVoltage_052 m13 : 11|13@0+ (1,0) [0|8191] "mV" Vector__XXX
SG_ CellVoltage_053 m13 : 30|13@0+ (1,0) [0|8191] "mV" Vector__XXX
SG_ CellVoltage_054 m13 : 33|13@0+ (1,0) [0|8191] "mV" Vector__XXX
SG_ CellVoltage_055 m13 : 52|13@0+ (1,0) [0|8191] "mV" Vector__XXX
SG_ CellVoltage_056_invalidFlag m14 : 12|1@0+ (1,0) [0|1] "" Vector__XXX
SG_ CellVoltage_057_invalidFlag m14 : 13|1@0+ (1,0) [0|1] "" Vector__XXX
SG_ CellVoltage_058_invalidFlag m14 : 14|1@0+ (1,0) [0|1] "" Vector__XXX
SG_ CellVoltage_059_invalidFlag m14 : 15|1@0+ (1,0) [0|1] "" Vector__XXX
SG_ CellVoltage_056 m14 : 11|13@0+ (1,0) [0|8191] "mV" Vector__XXX
SG_ CellVoltage_057 m14 : 30|13@0+ (1,0) [0|8191] "mV" Vector__XXX
SG_ CellVoltage_058 m14 : 33|13@0+ (1,0) [0|8191] "mV" Vector__XXX
SG_ CellVoltage_059 m14 : 52|13@0+ (1,0) [0|8191] "mV" Vector__XXX
SG_ CellVoltage_060_invalidFlag m15 : 12|1@0+ (1,0) [0|1] "" Vector__XXX
SG_ CellVoltage_061_invalidFlag m15 : 13|1@0+ (1,0) [0|1] "" Vector__XXX
SG_ CellVoltage_062_invalidFlag m15 : 14|1@0+ (1,0) [0|1] "" Vector__XXX
SG_ CellVoltage_063_invalidFlag m15 : 15|1@0+ (1,0) [0|1] "" Vector__XXX
SG_ CellVoltage_060 m15 : 11|13@0+ (1,0) [0|8191] "mV" Vector__XXX
SG_ CellVoltage_061 m15 : 30|13@0+ (1,0) [0|8191] "mV" Vector__XXX
SG_ CellVoltage_062 m15 : 33|13@0+ (1,0) [0|8191] "mV" Vector__XXX
SG_ CellVoltage_063 m15 : 52|13@0+ (1,0) [0|8191] "mV" Vector__XXX
SG_ CellVoltage_064_invalidFlag m16 : 12|1@0+ (1,0) [0|1] "" Vector__XXX
SG_ CellVoltage_065_invalidFlag m16 : 13|1@0+ (1,0) [0|1] "" Vector__XXX
SG_ CellVoltage_066_invalidFlag m16 : 14|1@0+ (1,0) [0|1] "" Vector__XXX
SG_ CellVoltage_067_invalidFlag m16 : 15|1@0+ (1,0) [0|1] "" Vector__XXX
SG_ CellVoltage_064 m16 : 11|13@0+ (1,0) [0|8191] "mV" Vector__XXX
SG_ CellVoltage_065 m16 : 30|13@0+ (1,0) [0|8191] "mV" Vector__XXX
SG_ CellVoltage_066 m16 : 33|13@0+ (1,0) [0|8191] "mV" Vector__XXX
SG_ CellVoltage_067 m16 : 52|13@0+ (1,0) [0|8191] "mV" Vector__XXX
SG_ CellVoltage_068_invalidFlag m17 : 12|1@0+ (1,0) [0|1] "" Vector__XXX
SG_ CellVoltage_069_invalidFlag m17 : 13|1@0+ (1,0) [0|1] "" Vector__XXX
SG_ CellVoltage_070_invalidFlag m17 : 14|1@0+ (1,0) [0|1] "" Vector__XXX
SG_ CellVoltage_071_invalidFlag m17 : 15|1@0+ (1,0) [0|1] "" Vector__XXX
SG_ CellVoltage_068 m17 : 11|13@0+ (1,0) [0|8191] "mV" Vector__XXX
SG_ CellVoltage_069 m17 : 30|13@0+ (1,0) [0|8191] "mV" Vector__XXX
SG_ CellVoltage_070 m17 : 33|13@0+ (1,0) [0|8191] "mV" Vector__XXX
SG_ CellVoltage_071 m17 : 52|13@0+ (1,0) [0|8191] "mV" Vector__XXX
SG_ CellVoltage_072_invalidFlag m18 : 12|1@0+ (1,0) [0|1] "" Vector__XXX
SG_ CellVoltage_073_invalidFlag m18 : 13|1@0+ (1,0) [0|1] "" Vector__XXX
SG_ CellVoltage_074_invalidFlag m18 : 14|1@0+ (1,0) [0|1] "" Vector__XXX
SG_ CellVoltage_075_invalidFlag m18 : 15|1@0+ (1,0) [0|1] "" Vector__XXX
SG_ CellVoltage_072 m18 : 11|13@0+ (1,0) [0|8191] "mV" Vector__XXX
SG_ CellVoltage_073 m18 : 30|13@0+ (1,0) [0|8191] "mV" Vector__XXX
SG_ CellVoltage_074 m18 : 33|13@0+ (1,0) [0|8191] "mV" Vector__XXX
SG_ CellVoltage_075 m18 : 52|13@0+ (1,0) [0|8191] "mV" Vector__XXX
SG_ CellVoltage_076_invalidFlag m19 : 12|1@0+ (1,0) [0|1] "" Vector__XXX
SG_ CellVoltage_077_invalidFlag m19 : 13|1@0+ (1,0) [0|1] "" Vector__XXX
SG_ CellVoltage_078_invalidFlag m19 : 14|1@0+ (1,0) [0|1] "" Vector__XXX
SG_ CellVoltage_079_invalidFlag m19 : 15|1@0+ (1,0) [0|1] "" Vector__XXX
SG_ CellVoltage_076 m19 : 11|13@0+ (1,0) [0|8191] "mV" Vector__XXX
SG_ CellVoltage_077 m19 : 30|13@0+ (1,0) [0|8191] "mV" Vector__XXX
SG_ CellVoltage_078 m19 : 33|13@0+ (1,0) [0|8191] "mV" Vector__XXX
SG_ CellVoltage_079 m19 : 52|13@0+ (1,0) [0|8191] "mV" Vector__XXX
SG_ CellVoltage_080_invalidFlag m20 : 12|1@0+ (1,0) [0|1] "" Vector__XXX
SG_ CellVoltage_081_invalidFlag m20 : 13|1@0+ (1,0) [0|1] "" Vector__XXX
SG_ CellVoltage_082_invalidFlag m20 : 14|1@0+ (1,0) [0|1] "" Vector__XXX
SG_ CellVoltage_083_invalidFlag m20 : 15|1@0+ (1,0) [0|1] "" Vector__XXX
SG_ CellVoltage_080 m20 : 11|13@0+ (1,0) [0|8191] "mV" Vector__XXX
SG_ CellVoltage_081 m20 : 30|13@0+ (1,0) [0|8191] "mV" Vector__XXX
SG_ CellVoltage_082 m20 : 33|13@0+ (1,0) [0|8191] "mV" Vector__XXX
SG_ CellVoltage_083 m20 : 52|13@0+ (1,0) [0|8191] "mV" Vector__XXX
SG_ CellVoltage_084_invalidFlag m21 : 12|1@0+ (1,0) [0|1] "" Vector__XXX
SG_ CellVoltage_085_invalidFlag m21 : 13|1@0+ (1,0) [0|1] "" Vector__XXX
SG_ CellVoltage_086_invalidFlag m21 : 14|1@0+ (1,0) [0|1] "" Vector__XXX
SG_ CellVoltage_087_invalidFlag m21 : 15|1@0+ (1,0) [0|1] "" Vector__XXX
SG_ CellVoltage_084 m21 : 11|13@0+ (1,0) [0|8191] "mV" Vector__XXX
SG_ CellVoltage_085 m21 : 30|13@0+ (1,0) [0|8191] "mV" Vector__XXX
SG_ CellVoltage_086 m21 : 33|13@0+ (1,0) [0|8191] "mV" Vector__XXX
SG_ CellVoltage_087 m21 : 52|13@0+ (1,0) [0|8191] "mV" Vector__XXX
SG_ CellVoltage_088_invalidFlag m22 : 12|1@0+ (1,0) [0|1] "" Vector__XXX
SG_ CellVoltage_089_invalidFlag m22 : 13|1@0+ (1,0) [0|1] "" Vector__XXX
SG_ CellVoltage_090_invalidFlag m22 : 14|1@0+ (1,0) [0|1] "" Vector__XXX
SG_ CellVoltage_091_invalidFlag m22 : 15|1@0+ (1,0) [0|1] "" Vector__XXX
SG_ CellVoltage_088 m22 : 11|13@0+ (1,0) [0|8191] "mV" Vector__XXX
SG_ CellVoltage_089 m22 : 30|13@0+ (1,0) [0|8191] "mV" Vector__XXX
SG_ CellVoltage_090 m22 : 33|13@0+ (1,0) [0|8191] "mV" Vector__XXX
SG_ CellVoltage_091 m22 : 52|13@0+ (1,0) [0|8191] "mV" Vector__XXX
SG_ CellVoltage_092_invalidFlag m23 : 12|1@0+ (1,0) [0|1] "" Vector__XXX
SG_ CellVoltage_093_invalidFlag m23 : 13|1@0+ (1,0) [0|1] "" Vector__XXX
SG_ CellVoltage_094_invalidFlag m23 : 14|1@0+ (1,0) [0|1] "" Vector__XXX
SG_ CellVoltage_095_invalidFlag m23 : 15|1@0+ (1,0) [0|1] "" Vector__XXX
SG_ CellVoltage_092 m23 : 11|13@0+ (1,0) [0|8191] "mV" Vector__XXX
SG_ CellVoltage_093 m23 : 30|13@0+ (1,0) [0|8191] "mV" Vector__XXX
SG_ CellVoltage_094 m23 : 33|13@0+ (1,0) [0|8191] "mV" Vector__XXX
SG_ CellVoltage_095 m23 : 52|13@0+ (1,0) [0|8191] "mV" Vector__XXX
SG_ CellVoltage_096_invalidFlag m24 : 12|1@0+ (1,0) [0|1] "" Vector__XXX
SG_ CellVoltage_097_invalidFlag m24 : 13|1@0+ (1,0) [0|1] "" Vector__XXX
SG_ CellVoltage_098_invalidFlag m24 : 14|1@0+ (1,0) [0|1] "" Vector__XXX
SG_ CellVoltage_099_invalidFlag m24 : 15|1@0+ (1,0) [0|1] "" Vector__XXX
SG_ CellVoltage_096 m24 : 11|13@0+ (1,0) [0|8191] "mV" Vector__XXX
SG_ CellVoltage_097 m24 : 30|13@0+ (1,0) [0|8191] "mV" Vector__XXX
SG_ CellVoltage_098 m24 : 33|13@0+ (1,0) [0|8191] "mV" Vector__XXX
SG_ CellVoltage_099 m24 : 52|13@0+ (1,0) [0|8191] "mV" Vector__XXX
SG_ CellVoltage_100_invalidFlag m25 : 12|1@0+ (1,0) [0|1] "" Vector__XXX
SG_ CellVoltage_101_invalidFlag m25 : 13|1@0+ (1,0) [0|1] "" Vector__XXX
SG_ CellVoltage_102_invalidFlag m25 : 14|1@0+ (1,0) [0|1] "" Vector__XXX
SG_ CellVoltage_103_invalidFlag m25 : 15|1@0+ (1,0) [0|1] "" Vector__XXX
SG_ CellVoltage_100 m25 : 11|13@0+ (1,0) [0|8191] "mV" Vector__XXX
SG_ CellVoltage_101 m25 : 30|13@0+ (1,0) [0|8191] "mV" Vector__XXX
SG_ CellVoltage_102 m25 : 33|13@0+ (1,0) [0|8191] "mV" Vector__XXX
SG_ CellVoltage_103 m25 : 52|13@0+ (1,0) [0|8191] "mV" Vector__XXX
SG_ CellVoltage_104_invalidFlag m26 : 12|1@0+ (1,0) [0|1] "" Vector__XXX
SG_ CellVoltage_105_invalidFlag m26 : 13|1@0+ (1,0) [0|1] "" Vector__XXX
SG_ CellVoltage_106_invalidFlag m26 : 14|1@0+ (1,0) [0|1] "" Vector__XXX
SG_ CellVoltage_107_invalidFlag m26 : 15|1@0+ (1,0) [0|1] "" Vector__XXX
SG_ CellVoltage_104 m26 : 11|13@0+ (1,0) [0|8191] "mV" Vector__XXX
SG_ CellVoltage_105 m26 : 30|13@0+ (1,0) [0|8191] "mV" Vector__XXX
SG_ CellVoltage_106 m26 : 33|13@0+ (1,0) [0|8191] "mV" Vector__XXX
SG_ CellVoltage_107 m26 : 52|13@0+ (1,0) [0|8191] "mV" Vector__XXX
SG_ CellVoltage_108_invalidFlag m27 : 12|1@0+ (1,0) [0|1] "" Vector__XXX
SG_ CellVoltage_109_invalidFlag m27 : 13|1@0+ (1,0) [0|1] "" Vector__XXX
SG_ CellVoltage_110_invalidFlag m27 : 14|1@0+ (1,0) [0|1] "" Vector__XXX
SG_ CellVoltage_111_invalidFlag m27 : 15|1@0+ (1,0) [0|1] "" Vector__XXX
SG_ CellVoltage_108 m27 : 11|13@0+ (1,0) [0|8191] "mV" Vector__XXX
SG_ CellVoltage_109 m27 : 30|13@0+ (1,0) [0|8191] "mV" Vector__XXX
SG_ CellVoltage_110 m27 : 33|13@0+ (1,0) [0|8191] "mV" Vector__XXX
SG_ CellVoltage_111 m27 : 52|13@0+ (1,0) [0|8191] "mV" Vector__XXX
SG_ CellVoltage_112_invalidFlag m28 : 12|1@0+ (1,0) [0|1] "" Vector__XXX
SG_ CellVoltage_113_invalidFlag m28 : 13|1@0+ (1,0) [0|1] "" Vector__XXX
SG_ CellVoltage_114_invalidFlag m28 : 14|1@0+ (1,0) [0|1] "" Vector__XXX
SG_ CellVoltage_115_invalidFlag m28 : 15|1@0+ (1,0) [0|1] "" Vector__XXX
SG_ CellVoltage_112 m28 : 11|13@0+ (1,0) [0|8191] "mV" Vector__XXX
SG_ CellVoltage_113 m28 : 30|13@0+ (1,0) [0|8191] "mV" Vector__XXX
SG_ CellVoltage_114 m28 : 33|13@0+ (1,0) [0|8191] "mV" Vector__XXX
SG_ CellVoltage_115 m28 : 52|13@0+ (1,0) [0|8191] "mV" Vector__XXX
SG_ CellVoltage_116_invalidFlag m29 : 12|1@0+ (1,0) [0|1] "" Vector__XXX
SG_ CellVoltage_117_invalidFlag m29 : 13|1@0+ (1,0) [0|1] "" Vector__XXX
SG_ CellVoltage_118_invalidFlag m29 : 14|1@0+ (1,0) [0|1] "" Vector__XXX
SG_ CellVoltage_119_invalidFlag m29 : 15|1@0+ (1,0) [0|1] "" Vector__XXX
SG_ CellVoltage_116 m29 : 11|13@0+ (1,0) [0|8191] "mV" Vector__XXX
SG_ CellVoltage_117 m29 : 30|13@0+ (1,0) [0|8191] "mV" Vector__XXX
SG_ CellVoltage_118 m29 : 33|13@0+ (1,0) [0|8191] "mV" Vector__XXX
SG_ CellVoltage_119 m29 : 52|13@0+ (1,0) [0|8191] "mV" Vector__XXX
SG_ CellVoltage_120_invalidFlag m30 : 12|1@0+ (1,0) [0|1] "" Vector__XXX
SG_ CellVoltage_121_invalidFlag m30 : 13|1@0+ (1,0) [0|1] "" Vector__XXX
SG_ CellVoltage_122_invalidFlag m30 : 14|1@0+ (1,0) [0|1] "" Vector__XXX
SG_ CellVoltage_123_invalidFlag m30 : 15|1@0+ (1,0) [0|1] "" Vector__XXX
SG_ CellVoltage_120 m30 : 11|13@0+ (1,0) [0|8191] "mV" Vector__XXX
SG_ CellVoltage_121 m30 : 30|13@0+ (1,0) [0|8191] "mV" Vector__XXX
SG_ CellVoltage_122 m30 : 33|13@0+ (1,0) [0|8191] "mV" Vector__XXX
SG_ CellVoltage_123 m30 : 52|13@0+ (1,0) [0|8191] "mV" Vector__XXX
SG_ CellVoltage_124_invalidFlag m31 : 12|1@0+ (1,0) [0|1] "" Vector__XXX
SG_ CellVoltage_125_invalidFlag m31 : 13|1@0+ (1,0) [0|1] "" Vector__XXX
SG_ CellVoltage_126_invalidFlag m31 : 14|1@0+ (1,0) [0|1] "" Vector__XXX
SG_ CellVoltage_127_invalidFlag m31 : 15|1@0+ (1,0) [0|1] "" Vector__XXX
SG_ CellVoltage_124 m31 : 11|13@0+ (1,0) [0|8191] "mV" Vector__XXX
SG_ CellVoltage_125 m31 : 30|13@0+ (1,0) [0|8191] "mV" Vector__XXX
SG_ CellVoltage_126 m31 : 33|13@0+ (1,0) [0|8191] "mV" Vector__XXX
SG_ CellVoltage_127 m31 : 52|13@0+ (1,0) [0|8191] "mV" Vector__XXX
SG_ CellVoltage_128_invalidFlag m32 : 12|1@0+ (1,0) [0|1] "" Vector__XXX
SG_ CellVoltage_129_invalidFlag m32 : 13|1@0+ (1,0) [0|1] "" Vector__XXX
SG_ CellVoltage_130_invalidFlag m32 : 14|1@0+ (1,0) [0|1] "" Vector__XXX
SG_ CellVoltage_131_invalidFlag m32 : 15|1@0+ (1,0) [0|1] "" Vector__XXX
SG_ CellVoltage_128 m32 : 11|13@0+ (1,0) [0|8191] "mV" Vector__XXX
SG_ CellVoltage_129 m32 : 30|13@0+ (1,0) [0|8191] "mV" Vector__XXX
SG_ CellVoltage_130 m32 : 33|13@0+ (1,0) [0|8191] "mV" Vector__XXX
SG_ CellVoltage_131 m32 : 52|13@0+ (1,0) [0|8191] "mV" Vector__XXX
SG_ CellVoltage_132_invalidFlag m33 : 12|1@0+ (1,0) [0|1] "" Vector__XXX
SG_ CellVoltage_133_invalidFlag m33 : 13|1@0+ (1,0) [0|1] "" Vector__XXX
SG_ CellVoltage_134_invalidFlag m33 : 14|1@0+ (1,0) [0|1] "" Vector__XXX
SG_ CellVoltage_135_invalidFlag m33 : 15|1@0+ (1,0) [0|1] "" Vector__XXX
SG_ CellVoltage_132 m33 : 11|13@0+ (1,0) [0|8191] "mV" Vector__XXX
SG_ CellVoltage_133 m33 : 30|13@0+ (1,0) [0|8191] "mV" Vector__XXX
SG_ CellVoltage_134 m33 : 33|13@0+ (1,0) [0|8191] "mV" Vector__XXX
SG_ CellVoltage_135 m33 : 52|13@0+ (1,0) [0|8191] "mV" Vector__XXX
SG_ CellVoltage_136_invalidFlag m34 : 12|1@0+ (1,0) [0|1] "" Vector__XXX
SG_ CellVoltage_137_invalidFlag m34 : 13|1@0+ (1,0) [0|1] "" Vector__XXX
SG_ CellVoltage_138_invalidFlag m34 : 14|1@0+ (1,0) [0|1] "" Vector__XXX
SG_ CellVoltage_139_invalidFlag m34 : 15|1@0+ (1,0) [0|1] "" Vector__XXX
SG_ CellVoltage_136 m34 : 11|13@0+ (1,0) [0|8191] "mV" Vector__XXX
SG_ CellVoltage_137 m34 : 30|13@0+ (1,0) [0|8191] "mV" Vector__XXX
SG_ CellVoltage_138 m34 : 33|13@0+ (1,0) [0|8191] "mV" Vector__XXX
SG_ CellVoltage_139 m34 : 52|13@0+ (1,0) [0|8191] "mV" Vector__XXX
SG_ CellVoltage_140_invalidFlag m35 : 12|1@0+ (1,0) [0|1] "" Vector__XXX
SG_ CellVoltage_141_invalidFlag m35 : 13|1@0+ (1,0) [0|1] "" Vector__XXX
SG_ CellVoltage_142_invalidFlag m35 : 14|1@0+ (1,0) [0|1] "" Vector__XXX
SG_ CellVoltage_143_invalidFlag m35 : 15|1@0+ (1,0) [0|1] "" Vector__XXX
SG_ CellVoltage_140 m35 : 11|13@0+ (1,0) [0|8191] "mV" Vector__XXX
SG_ CellVoltage_141 m35 : 30|13@0+ (1,0) [0|8191] "mV" Vector__XXX
SG_ CellVoltage_142 m35 : 33|13@0+ (1,0) [0|8191] "mV" Vector__XXX
SG_ CellVoltage_143 m35 : 52|13@0+ (1,0) [0|8191] "mV" Vector__XXX
SG_ CellVoltage_144_invalidFlag m36 : 12|1@0+ (1,0) [0|1] "" Vector__XXX
SG_ CellVoltage_145_invalidFlag m36 : 13|1@0+ (1,0) [0|1] "" Vector__XXX
SG_ CellVoltage_146_invalidFlag m36 : 14|1@0+ (1,0) [0|1] "" Vector__XXX
SG_ CellVoltage_147_invalidFlag m36 : 15|1@0+ (1,0) [0|1] "" Vector__XXX
SG_ CellVoltage_144 m36 : 11|13@0+ (1,0) [0|8191] "mV" Vector__XXX
SG_ CellVoltage_145 m36 : 30|13@0+ (1,0) [0|8191] "mV" Vector__XXX
SG_ CellVoltage_146 m36 : 33|13@0+ (1,0) [0|8191] "mV" Vector__XXX
SG_ CellVoltage_147 m36 : 52|13@0+ (1,0) [0|8191] "mV" Vector__XXX
SG_ CellVoltage_148_invalidFlag m37 : 12|1@0+ (1,0) [0|1] "" Vector__XXX
SG_ CellVoltage_149_invalidFlag m37 : 13|1@0+ (1,0) [0|1] "" Vector__XXX
SG_ CellVoltage_150_invalidFlag m37 : 14|1@0+ (1,0) [0|1] "" Vector__XXX
SG_ CellVoltage_151_invalidFlag m37 : 15|1@0+ (1,0) [0|1] "" Vector__XXX
SG_ CellVoltage_148 m37 : 11|13@0+ (1,0) [0|8191] "mV" Vector__XXX
SG_ CellVoltage_149 m37 : 30|13@0+ (1,0) [0|8191] "mV" Vector__XXX
SG_ CellVoltage_150 m37 : 33|13@0+ (1,0) [0|8191] "mV" Vector__XXX
SG_ CellVoltage_151 m37 : 52|13@0+ (1,0) [0|8191] "mV" Vector__XXX
SG_ CellVoltage_152_invalidFlag m38 : 12|1@0+ (1,0) [0|1] "" Vector__XXX
SG_ CellVoltage_153_invalidFlag m38 : 13|1@0+ (1,0) [0|1] "" Vector__XXX
SG_ CellVoltage_154_invalidFlag m38 : 14|1@0+ (1,0) [0|1] "" Vector__XXX
SG_ CellVoltage_155_invalidFlag m38 : 15|1@0+ (1,0) [0|1] "" Vector__XXX
SG_ CellVoltage_152 m38 : 11|13@0+ (1,0) [0|8191] "mV" Vector__XXX
SG_ CellVoltage_153 m38 : 30|13@0+ (1,0) [0|8191] "mV" Vector__XXX
SG_ CellVoltage_154 m38 : 33|13@0+ (1,0) [0|8191] "mV" Vector__XXX
SG_ CellVoltage_155 m38 : 52|13@0+ (1,0) [0|8191] "mV" Vector__XXX
SG_ CellVoltage_156_invalidFlag m39 : 12|1@0+ (1,0) [0|1] "" Vector__XXX
SG_ CellVoltage_157_invalidFlag m39 : 13|1@0+ (1,0) [0|1] "" Vector__XXX
SG_ CellVoltage_158_invalidFlag m39 : 14|1@0+ (1,0) [0|1] "" Vector__XXX
SG_ CellVoltage_159_invalidFlag m39 : 15|1@0+ (1,0) [0|1] "" Vector__XXX
SG_ CellVoltage_156 m39 : 11|13@0+ (1,0) [0|8191] "mV" Vector__XXX
SG_ CellVoltage_157 m39 : 30|13@0+ (1,0) [0|8191] "mV" Vector__XXX
SG_ CellVoltage_158 m39 : 33|13@0+ (1,0) [0|8191] "mV" Vector__XXX
SG_ CellVoltage_159 m39 : 52|13@0+ (1,0) [0|8191] "mV" Vector__XXX
SG_ CellVoltage_160_invalidFlag m40 : 12|1@0+ (1,0) [0|1] "" Vector__XXX
SG_ CellVoltage_161_invalidFlag m40 : 13|1@0+ (1,0) [0|1] "" Vector__XXX
SG_ CellVoltage_162_invalidFlag m40 : 14|1@0+ (1,0) [0|1] "" Vector__XXX
SG_ CellVoltage_163_invalidFlag m40 : 15|1@0+ (1,0) [0|1] "" Vector__XXX
SG_ CellVoltage_160 m40 : 11|13@0+ (1,0) [0|8191] "mV" Vector__XXX
SG_ CellVoltage_161 m40 : 30|13@0+ (1,0) [0|8191] "mV" Vector__XXX
SG_ CellVoltage_162 m40 : 33|13@0+ (1,0) [0|8191] "mV" Vector__XXX
SG_ CellVoltage_163 m40 : 52|13@0+ (1,0) [0|8191] "mV" Vector__XXX
SG_ CellVoltage_164_invalidFlag m41 : 12|1@0+ (1,0) [0|1] "" Vector__XXX
SG_ CellVoltage_165_invalidFlag m41 : 13|1@0+ (1,0) [0|1] "" Vector__XXX
SG_ CellVoltage_166_invalidFlag m41 : 14|1@0+ (1,0) [0|1] "" Vector__XXX
SG_ CellVoltage_167_invalidFlag m41 : 15|1@0+ (1,0) [0|1] "" Vector__XXX
SG_ CellVoltage_164 m41 : 11|13@0+ (1,0) [0|8191] "mV" Vector__XXX
SG_ CellVoltage_165 m41 : 30|13@0+ (1,0) [0|8191] "mV" Vector__XXX
SG_ CellVoltage_166 m41 : 33|13@0+ (1,0) [0|8191] "mV" Vector__XXX
SG_ CellVoltage_167 m41 : 52|13@0+ (1,0) [0|8191] "mV" Vector__XXX
SG_ CellVoltage_168_invalidFlag m42 : 12|1@0+ (1,0) [0|1] "" Vector__XXX
SG_ CellVoltage_169_invalidFlag m42 : 13|1@0+ (1,0) [0|1] "" Vector__XXX
SG_ CellVoltage_170_invalidFlag m42 : 14|1@0+ (1,0) [0|1] "" Vector__XXX
SG_ CellVoltage_171_invalidFlag m42 : 15|1@0+ (1,0) [0|1] "" Vector__XXX
SG_ CellVoltage_168 m42 : 11|13@0+ (1,0) [0|8191] "mV" Vector__XXX
SG_ CellVoltage_169 m42 : 30|13@0+ (1,0) [0|8191] "mV" Vector__XXX
SG_ CellVoltage_170 m42 : 33|13@0+ (1,0) [0|8191] "mV" Vector__XXX
SG_ CellVoltage_171 m42 : 52|13@0+ (1,0) [0|8191] "mV" Vector__XXX
SG_ CellVoltage_172_invalidFlag m43 : 12|1@0+ (1,0) [0|1] "" Vector__XXX
SG_ CellVoltage_173_invalidFlag m43 : 13|1@0+ (1,0) [0|1] "" Vector__XXX
SG_ CellVoltage_174_invalidFlag m43 : 14|1@0+ (1,0) [0|1] "" Vector__XXX
SG_ CellVoltage_175_invalidFlag m43 : 15|1@0+ (1,0) [0|1] "" Vector__XXX
SG_ CellVoltage_172 m43 : 11|13@0+ (1,0) [0|8191] "mV" Vector__XXX
SG_ CellVoltage_173 m43 : 30|13@0+ (1,0) [0|8191] "mV" Vector__XXX
SG_ CellVoltage_174 m43 : 33|13@0+ (1,0) [0|8191] "mV" Vector__XXX
SG_ CellVoltage_175 m43 : 52|13@0+ (1,0) [0|8191] "mV" Vector__XXX
SG_ CellVoltage_176_invalidFlag m44 : 12|1@0+ (1,0) [0|1] "" Vector__XXX
SG_ CellVoltage_177_invalidFlag m44 : 13|1@0+ (1,0) [0|1] "" Vector__XXX
SG_ CellVoltage_178_invalidFlag m44 : 14|1@0+ (1,0) [0|1] "" Vector__XXX
SG_ CellVoltage_179_invalidFlag m44 : 15|1@0+ (1,0) [0|1] "" Vector__XXX
SG_ CellVoltage_176 m44 : 11|13@0+ (1,0) [0|8191] "mV" Vector__XXX
SG_ CellVoltage_177 m44 : 30|13@0+ (1,0) [0|8191] "mV" Vector__XXX
SG_ CellVoltage_178 m44 : 33|13@0+ (1,0) [0|8191] "mV" Vector__XXX
SG_ CellVoltage_179 m44 : 52|13@0+ (1,0) [0|8191] "mV" Vector__XXX
SG_ CellVoltage_180_invalidFlag m45 : 12|1@0+ (1,0) [0|1] "" Vector__XXX
SG_ CellVoltage_181_invalidFlag m45 : 13|1@0+ (1,0) [0|1] "" Vector__XXX
SG_ CellVoltage_182_invalidFlag m45 : 14|1@0+ (1,0) [0|1] "" Vector__XXX
SG_ CellVoltage_183_invalidFlag m45 : 15|1@0+ (1,0) [0|1] "" Vector__XXX
SG_ CellVoltage_180 m45 : 11|13@0+ (1,0) [0|8191] "mV" Vector__XXX
SG_ CellVoltage_181 m45 : 30|13@0+ (1,0) [0|8191] "mV" Vector__XXX
SG_ CellVoltage_182 m45 : 33|13@0+ (1,0) [0|8191] "mV" Vector__XXX
SG_ CellVoltage_183 m45 : 52|13@0+ (1,0) [0|8191] "mV" Vector__XXX
SG_ CellVoltage_184_invalidFlag m46 : 12|1@0+ (1,0) [0|1] "" Vector__XXX
SG_ CellVoltage_185_invalidFlag m46 : 13|1@0+ (1,0) [0|1] "" Vector__XXX
SG_ CellVoltage_186_invalidFlag m46 : 14|1@0+ (1,0) [0|1] "" Vector__XXX
SG_ CellVoltage_187_invalidFlag m46 : 15|1@0+ (1,0) [0|1] "" Vector__XXX
SG_ CellVoltage_184 m46 : 11|13@0+ (1,0) [0|8191] "mV" Vector__XXX
SG_ CellVoltage_185 m46 : 30|13@0+ (1,0) [0|8191] "mV" Vector__XXX
SG_ CellVoltage_186 m46 : 33|13@0+ (1,0) [0|8191] "mV" Vector__XXX
SG_ CellVoltage_187 m46 : 52|13@0+ (1,0) [0|8191] "mV" Vector__XXX
SG_ CellVoltage_188_invalidFlag m47 : 12|1@0+ (1,0) [0|1] "" Vector__XXX
SG_ CellVoltage_189_invalidFlag m47 : 13|1@0+ (1,0) [0|1] "" Vector__XXX
SG_ CellVoltage_190_invalidFlag m47 : 14|1@0+ (1,0) [0|1] "" Vector__XXX
SG_ CellVoltage_191_invalidFlag m47 : 15|1@0+ (1,0) [0|1] "" Vector__XXX
SG_ CellVoltage_188 m47 : 11|13@0+ (1,0) [0|8191] "mV" Vector__XXX
SG_ CellVoltage_189 m47 : 30|13@0+ (1,0) [0|8191] "mV" Vector__XXX
SG_ CellVoltage_190 m47 : 33|13@0+ (1,0) [0|8191] "mV" Vector__XXX
SG_ CellVoltage_191 m47 : 52|13@0+ (1,0) [0|8191] "mV" Vector__XXX
SG_ CellVoltage_192_invalidFlag m48 : 12|1@0+ (1,0) [0|1] "" Vector__XXX
SG_ CellVoltage_193_invalidFlag m48 : 13|1@0+ (1,0) [0|1] "" Vector__XXX
SG_ CellVoltage_194_invalidFlag m48 : 14|1@0+ (1,0) [0|1] "" Vector__XXX
SG_ CellVoltage_195_invalidFlag m48 : 15|1@0+ (1,0) [0|1] "" Vector__XXX
SG_ CellVoltage_192 m48 : 11|13@0+ (1,0) [0|8191] "mV" Vector__XXX
SG_ CellVoltage_193 m48 : 30|13@0+ (1,0) [0|8191] "mV" Vector__XXX
SG_ CellVoltage_194 m48 : 33|13@0+ (1,0) [0|8191] "mV" Vector__XXX
SG_ CellVoltage_195 m48 : 52|13@0+ (1,0) [0|8191] "mV" Vector__XXX
SG_ CellVoltage_196_invalidFlag m49 : 12|1@0+ (1,0) [0|1] "" Vector__XXX
SG_ CellVoltage_197_invalidFlag m49 : 13|1@0+ (1,0) [0|1] "" Vector__XXX
SG_ CellVoltage_198_invalidFlag m49 : 14|1@0+ (1,0) [0|1] "" Vector__XXX
SG_ CellVoltage_199_invalidFlag m49 : 15|1@0+ (1,0) [0|1] "" Vector__XXX
SG_ CellVoltage_196 m49 : 11|13@0+ (1,0) [0|8191] "mV" Vector__XXX
SG_ CellVoltage_197 m49 : 30|13@0+ (1,0) [0|8191] "mV" Vector__XXX
SG_ CellVoltage_198 m49 : 33|13@0+ (1,0) [0|8191] "mV" Vector__XXX
SG_ CellVoltage_199 m49 : 52|13@0+ (1,0) [0|8191] "mV" Vector__XXX
SG_ CellVoltage_200_invalidFlag m50 : 12|1@0+ (1,0) [0|1] "" Vector__XXX
SG_ CellVoltage_201_invalidFlag m50 : 13|1@0+ (1,0) [0|1] "" Vector__XXX
SG_ CellVoltage_202_invalidFlag m50 : 14|1@0+ (1,0) [0|1] "" Vector__XXX
SG_ CellVoltage_203_invalidFlag m50 : 15|1@0+ (1,0) [0|1] "" Vector__XXX
SG_ CellVoltage_200 m50 : 11|13@0+ (1,0) [0|8191] "mV" Vector__XXX
SG_ CellVoltage_201 m50 : 30|13@0+ (1,0) [0|8191] "mV" Vector__XXX
SG_ CellVoltage_202 m50 : 33|13@0+ (1,0) [0|8191] "mV" Vector__XXX
SG_ CellVoltage_203 m50 : 52|13@0+ (1,0) [0|8191] "mV" Vector__XXX
SG_ CellVoltage_204_invalidFlag m51 : 12|1@0+ (1,0) [0|1] "" Vector__XXX
SG_ CellVoltage_205_invalidFlag m51 : 13|1@0+ (1,0) [0|1] "" Vector__XXX
SG_ CellVoltage_206_invalidFlag m51 : 14|1@0+ (1,0) [0|1] "" Vector__XXX
SG_ CellVoltage_207_invalidFlag m51 : 15|1@0+ (1,0) [0|1] "" Vector__XXX
SG_ CellVoltage_204 m51 : 11|13@0+ (1,0) [0|8191] "mV" Vector__XXX
SG_ CellVoltage_205 m51 : 30|13@0+ (1,0) [0|8191] "mV" Vector__XXX
SG_ CellVoltage_206 m51 : 33|13@0+ (1,0) [0|8191] "mV" Vector__XXX
SG_ CellVoltage_207 m51 : 52|13@0+ (1,0) [0|8191] "mV" Vector__XXX
SG_ CellVoltage_208_invalidFlag m52 : 12|1@0+ (1,0) [0|1] "" Vector__XXX
SG_ CellVoltage_209_invalidFlag m52 : 13|1@0+ (1,0) [0|1] "" Vector__XXX
SG_ CellVoltage_210_invalidFlag m52 : 14|1@0+ (1,0) [0|1] "" Vector__XXX
SG_ CellVoltage_211_invalidFlag m52 : 15|1@0+ (1,0) [0|1] "" Vector__XXX
SG_ CellVoltage_208 m52 : 11|13@0+ (1,0) [0|8191] "mV" Vector__XXX
SG_ CellVoltage_209 m52 : 30|13@0+ (1,0) [0|8191] "mV" Vector__XXX
SG_ CellVoltage_210 m52 : 33|13@0+ (1,0) [0|8191] "mV" Vector__XXX
SG_ CellVoltage_211 m52 : 52|13@0+ (1,0) [0|8191] "mV" Vector__XXX
SG_ CellVoltage_212_invalidFlag m53 : 12|1@0+ (1,0) [0|1] "" Vector__XXX
SG_ CellVoltage_213_invalidFlag m53 : 13|1@0+ (1,0) [0|1] "" Vector__XXX
SG_ CellVoltage_214_invalidFlag m53 : 14|1@0+ (1,0) [0|1] "" Vector__XXX
SG_ CellVoltage_215_invalidFlag m53 : 15|1@0+ (1,0) [0|1] "" Vector__XXX
SG_ CellVoltage_212 m53 : 11|13@0+ (1,0) [0|8191] "mV" Vector__XXX
SG_ CellVoltage_213 m53 : 30|13@0+ (1,0) [0|8191] "mV" Vector__XXX
SG_ CellVoltage_214 m53 : 33|13@0+ (1,0) [0|8191] "mV" Vector__XXX
SG_ CellVoltage_215 m53 : 52|13@0+ (1,0) [0|8191] "mV" Vector__XXX

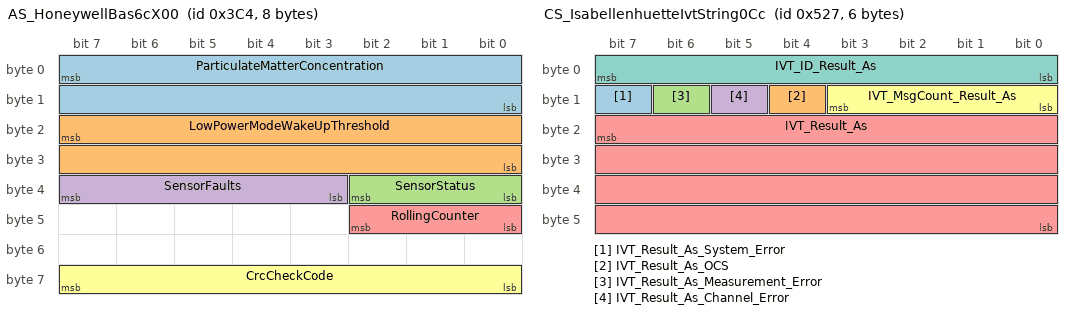
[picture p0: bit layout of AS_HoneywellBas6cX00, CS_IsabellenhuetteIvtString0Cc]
BO_ 964 AS_HoneywellBas6cX00: 8 Vector__XXX
SG_ ParticulateMatterConcentration : 7|16@0+ (1,0) [0|65535] "" Vector__XXX
SG_ LowPowerModeWakeUpThreshold : 23|16@0+ (1,0) [0|65535] "" Vector__XXX
SG_ SensorStatus : 34|3@0+ (1,0) [0|7] "" Vector__XXX
SG_ SensorFaults : 39|5@0+ (1,0) [0|31] "" Vector__XXX
SG_ RollingCounter : 42|3@0+ (1,0) [0|7] "" Vector__XXX
SG_ CrcCheckCode : 63|8@0+ (1,0) [0|255] "" Vector__XXX

BO_ 1319 CS_IsabellenhuetteIvtString0Cc: 6 Vector__XXX
SG_ IVT_Result_As_System_Error : 15|1@0+ (1,0) [0|1] "" Vector__XXX
SG_ IVT_Result_As_OCS : 12|1@0+ (1,0) [0|1] "" Vector__XXX
SG_ IVT_Result_As_Measurement_Error : 14|1@0+ (1,0) [0|1] "" Vector__XXX
SG_ IVT_Result_As_Channel_Error : 13|1@0+ (1,0) [0|1] "" Vector__XXX
SG_ IVT_Result_As : 23|32@0- (1,0) [-2147483648|2147483647] "As" Vector__XXX
SG_ IVT_MsgCount_Result_As : 11|4@0+ (1,0) [0|15] "" Vector__XXX
SG_ IVT_ID_Result_As : 7|8@0+ (1,0) [6|6] "" Vector__XXX

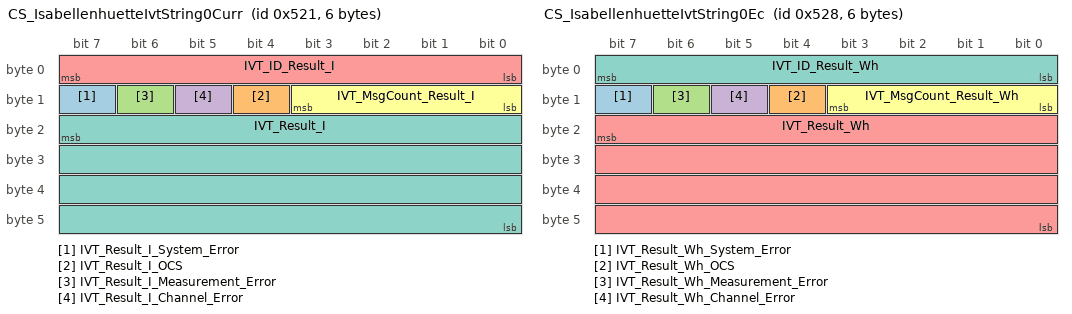
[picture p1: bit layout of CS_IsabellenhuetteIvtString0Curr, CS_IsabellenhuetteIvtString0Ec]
BO_ 1313 CS_IsabellenhuetteIvtString0Curr: 6 Vector__XXX
SG_ IVT_Result_I_System_Error : 15|1@0+ (1,0) [0|1] "" Vector__XXX
SG_ IVT_Result_I_OCS : 12|1@0+ (1,0) [0|1] "" Vector__XXX
SG_ IVT_Result_I_Measurement_Error : 14|1@0+ (1,0) [0|1] "" Vector__XXX
SG_ IVT_Result_I_Channel_Error : 13|1@0+ (1,0) [0|1] "" Vector__XXX
SG_ IVT_ID_Result_I : 7|8@0+ (1,0) [0|255] "" Vector__XXX
SG_ IVT_MsgCount_Result_I : 11|4@0+ (1,0) [0|15] "" Vector__XXX
SG_ IVT_Result_I : 23|32@0- (1,0) [-2147483648|2147483647] "mA" Vector__XXX

BO_ 1320 CS_IsabellenhuetteIvtString0Ec: 6 Vector__XXX
SG_ IVT_Result_Wh_System_Error : 15|1@0+ (1,0) [0|1] "" Vector__XXX
SG_ IVT_Result_Wh_OCS : 12|1@0+ (1,0) [0|1] "" Vector__XXX
SG_ IVT_Result_Wh_Measurement_Error : 14|1@0+ (1,0) [0|1] "" Vector__XXX
SG_ IVT_Result_Wh_Channel_Error : 13|1@0+ (1,0) [0|1] "" Vector__XXX
SG_ IVT_Result_Wh : 23|32@0- (1,0) [-2147483648|2147483647] "Wh" Vector__XXX
SG_ IVT_MsgCount_Result_Wh : 11|4@0+ (1,0) [0|15] "" Vector__XXX
SG_ IVT_ID_Result_Wh : 7|8@0+ (1,0) [7|7] "" Vector__XXX

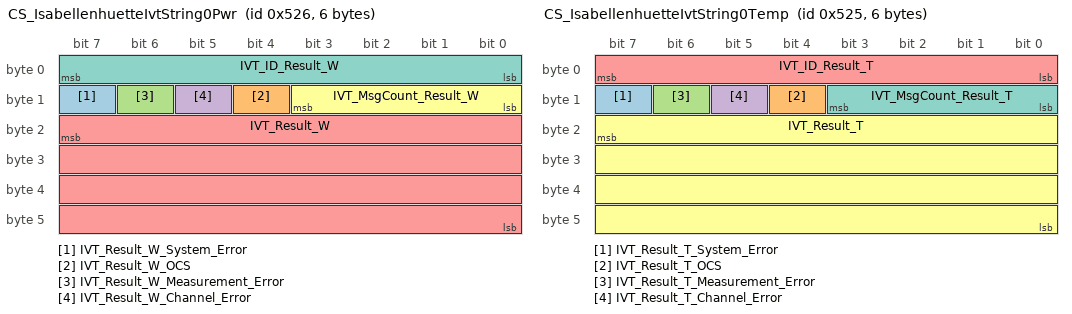
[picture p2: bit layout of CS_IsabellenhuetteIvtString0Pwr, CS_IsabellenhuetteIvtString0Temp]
BO_ 1318 CS_IsabellenhuetteIvtString0Pwr: 6 Vector__XXX
SG_ IVT_Result_W_System_Error : 15|1@0+ (1,0) [0|1] "" Vector__XXX
SG_ IVT_Result_W_OCS : 12|1@0+ (1,0) [0|1] "" Vector__XXX
SG_ IVT_Result_W_Measurement_Error : 14|1@0+ (1,0) [0|1] "" Vector__XXX
SG_ IVT_Result_W_Channel_Error : 13|1@0+ (1,0) [0|1] "" Vector__XXX
SG_ IVT_Result_W : 23|32@0- (1,0) [-2147483648|2147483647] "W" Vector__XXX
SG_ IVT_MsgCount_Result_W : 11|4@0+ (1,0) [0|15] "" Vector__XXX
SG_ IVT_ID_Result_W : 7|8@0+ (1,0) [5|5] "" Vector__XXX

BO_ 1317 CS_IsabellenhuetteIvtString0Temp: 6 Vector__XXX
SG_ IVT_Result_T_System_Error : 15|1@0+ (1,0) [0|1] "" Vector__XXX
SG_ IVT_Result_T_OCS : 12|1@0+ (1,0) [0|1] "" Vector__XXX
SG_ IVT_Result_T_Measurement_Error : 14|1@0+ (1,0) [0|1] "" Vector__XXX
SG_ IVT_Result_T_Channel_Error : 13|1@0+ (1,0) [0|1] "" Vector__XXX
SG_ IVT_ID_Result_T : 7|8@0+ (1,0) [4|4] "" Vector__XXX
SG_ IVT_Result_T : 23|32@0- (0.1,0) [-214748364.8|214748364.7] "degC" Vector__XXX
SG_ IVT_MsgCount_Result_T : 11|4@0+ (1,0) [0|15] "" Vector__XXX

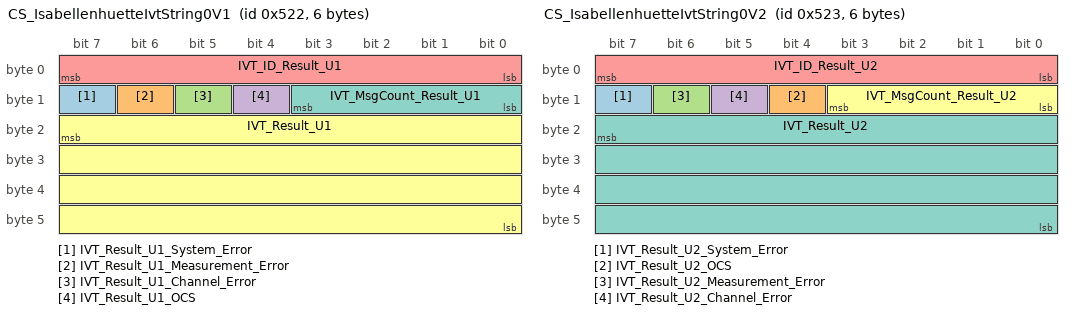
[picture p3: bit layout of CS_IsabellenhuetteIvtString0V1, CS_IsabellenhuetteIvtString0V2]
BO_ 1314 CS_IsabellenhuetteIvtString0V1: 6 Vector__XXX
SG_ IVT_Result_U1_System_Error : 15|1@0+ (1,0) [0|1] "" Vector__XXX
SG_ IVT_Result_U1_Measurement_Error : 14|1@0+ (1,0) [0|1] "" Vector__XXX
SG_ IVT_Result_U1_Channel_Error : 13|1@0+ (1,0) [0|1] "" Vector__XXX
SG_ IVT_Result_U1_OCS : 12|1@0+ (1,0) [0|1] "" Vector__XXX
SG_ IVT_ID_Result_U1 : 7|8@0+ (1,0) [1|1] "" Vector__XXX
SG_ IVT_Result_U1 : 23|32@0- (1,0) [-2147483648|2147483647] "mV" Vector__XXX
SG_ IVT_MsgCount_Result_U1 : 11|4@0+ (1,0) [0|15] "" Vector__XXX

BO_ 1315 CS_IsabellenhuetteIvtString0V2: 6 Vector__XXX
SG_ IVT_Result_U2_System_Error : 15|1@0+ (1,0) [0|1] "" Vector__XXX
SG_ IVT_Result_U2_OCS : 12|1@0+ (1,0) [0|1] "" Vector__XXX
SG_ IVT_Result_U2_Measurement_Error : 14|1@0+ (1,0) [0|1] "" Vector__XXX
SG_ IVT_Result_U2_Channel_Error : 13|1@0+ (1,0) [0|1] "" Vector__XXX
SG_ IVT_ID_Result_U2 : 7|8@0+ (1,0) [2|2] "" Vector__XXX
SG_ IVT_MsgCount_Result_U2 : 11|4@0+ (1,0) [0|15] "" Vector__XXX
SG_ IVT_Result_U2 : 23|32@0- (1,0) [-2147483648|2147483647] "mV" Vector__XXX

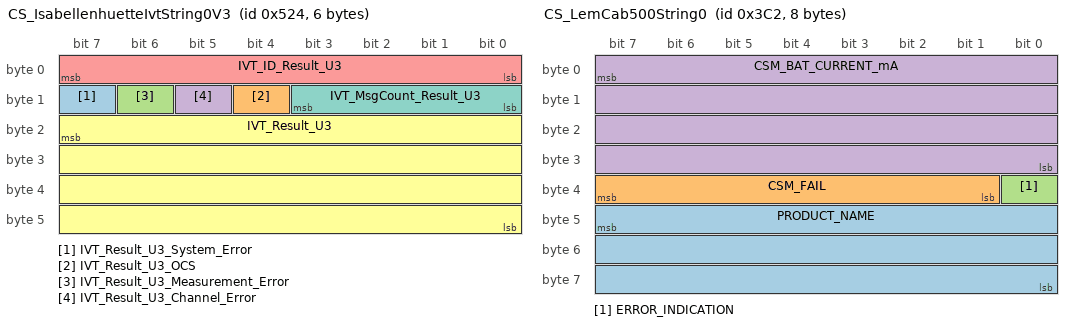
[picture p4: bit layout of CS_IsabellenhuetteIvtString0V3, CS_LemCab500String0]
BO_ 1316 CS_IsabellenhuetteIvtString0V3: 6 Vector__XXX
SG_ IVT_Result_U3_System_Error : 15|1@0+ (1,0) [0|1] "" Vector__XXX
SG_ IVT_Result_U3_OCS : 12|1@0+ (1,0) [0|1] "" Vector__XXX
SG_ IVT_Result_U3_Measurement_Error : 14|1@0+ (1,0) [0|1] "" Vector__XXX
SG_ IVT_Result_U3_Channel_Error : 13|1@0+ (1,0) [0|1] "" Vector__XXX
SG_ IVT_ID_Result_U3 : 7|8@0+ (1,0) [3|3] "" Vector__XXX
SG_ IVT_Result_U3 : 23|32@0- (1,0) [-2147483648|2147483647] "mV" Vector__XXX
SG_ IVT_MsgCount_Result_U3 : 11|4@0+ (1,0) [0|15] "" Vector__XXX

BO_ 962 CS_LemCab500String0: 8 Vector__XXX
SG_ PRODUCT_NAME : 47|24@0+ (1,0) [0|1] "" Vector__XXX
SG_ CSM_FAIL : 39|7@0+ (1,0) [0|1] "" Vector__XXX
SG_ ERROR_INDICATION : 32|1@0+ (1,0) [0|1] "" Vector__XXX
SG_ CSM_BAT_CURRENT_mA : 7|32@0+ (1,0) [0|4294967295] "" Vector__XXX

BO_ 546 f_BmsFatalError: 8 Vector__XXX
SG_ FatalErrorCode : 7|8@0+ (1,0) [0|255] "" Vector__XXX

BO_ 544 f_BmsState: 8 Vector__XXX
SG_ BmsState : 3|4@0+ (1,0) [0|15] "" Vector__XXX
SG_ NumberOfConnectedStrings : 7|4@0+ (1,0) [0|15] "" Vector__XXX
SG_ GeneralError : 10|1@0+ (1,0) [0|1] "" Vector__XXX
SG_ GeneralWarning : 9|1@0+ (1,0) [0|1] "" Vector__XXX
SG_ McuDieTemperatureError : 18|1@0+ (1,0) [0|1] "" Vector__XXX
SG_ BmsMasterPcbOvertemperatureError : 19|1@0+ (1,0) [0|1] "" Vector__XXX
SG_ BmsMasterPcbUndertemperatureErro : 20|1@0+ (1,0) [0|1] "" Vector__XXX
SG_ PrechargeVoltageError : 16|1@0+ (1,0) [0|1] "" Vector__XXX
SG_ PrechargeCurrentError : 17|1@0+ (1,0) [0|1] "" Vector__XXX
SG_ HeaterState : 14|1@0+ (1,0) [0|1] "" Vector__XXX
SG_ CoolingState : 15|1@0+ (1,0) [0|1] "" Vector__XXX
SG_ InsulationMonitoring : 13|1@0+ (1,0) [0|1] "" Vector__XXX
SG_ ChargingComplete : 8|1@0+ (1,0) [0|1] "" Vector__XXX
SG_ EmergencyShutoff : 11|1@0+ (1,0) [0|1] "" Vector__XXX
SG_ MainFuseBlown : 21|1@0+ (1,0) [0|1] "" Vector__XXX
SG_ InterlockState : 22|1@0+ (1,0) [0|1] "" Vector__XXX
SG_ NumberOfDeactivatedStrings : 51|4@0+ (1,0) [0|15] "" Vector__XXX
SG_ InsulationError : 23|1@0+ (1,0) [0|1] "" Vector__XXX
SG_ CanTimingError : 24|1@0+ (1,0) [0|1] "" Vector__XXX
SG_ PackOvercurrentChargeError : 25|1@0+ (1,0) [0|1] "" Vector__XXX
SG_ PackOvercurrentDischargeError : 26|1@0+ (1,0) [0|1] "" Vector__XXX
SG_ SystemMonitoringError : 12|1@0+ (1,0) [0|1] "" Vector__XXX
SG_ AlertFlag : 27|1@0+ (1,0) [0|1] "" Vector__XXX
SG_ NvramCrcError : 28|1@0+ (1,0) [0|1] "" Vector__XXX
SG_ InsulationResistance : 63|8@0+ (200,0) [0|51000] "kOhm" Vector__XXX
SG_ BmsSubstate : 37|6@0+ (1,0) [0|63] "" Vector__XXX
SG_ Clamp30cError : 30|1@0+ (1,0) [0|1] "" Vector__XXX
SG_ BalancingAlgorithmState : 31|1@1+ (1,0) [0|1] "" Vector__XXX
SG_ BmsChargingFlag : 29|1@1+ (1,0) [0|1] "" Vector__XXX
SG_ PhyAlive : 39|1@0+ (1,0) [0|1] "" Vector__XXX
SG_ PhyLinked : 38|1@1+ (1,0) [0|1] "" Vector__XXX

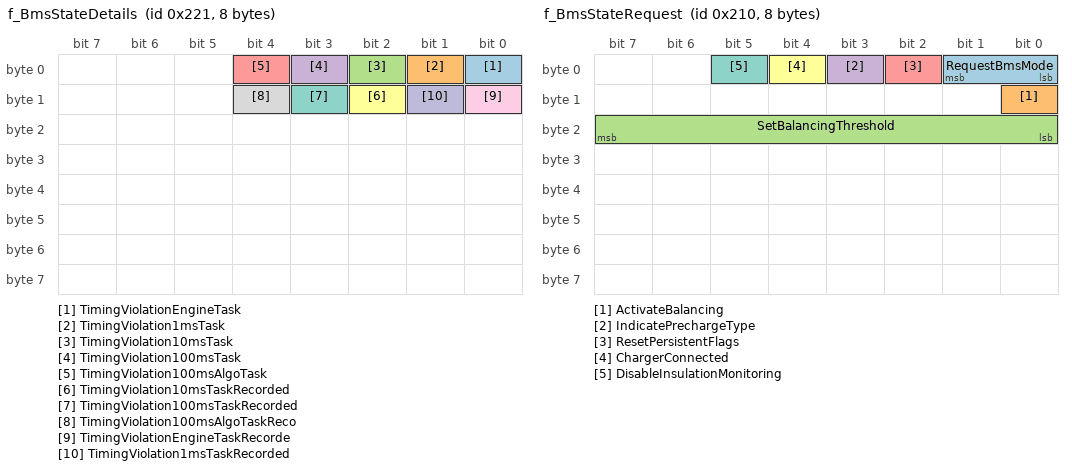
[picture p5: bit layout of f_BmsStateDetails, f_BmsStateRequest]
BO_ 545 f_BmsStateDetails: 8 Vector__XXX
SG_ TimingViolationEngineTask : 0|1@0+ (1,0) [0|1] "" Vector__XXX
SG_ TimingViolation1msTask : 1|1@0+ (1,0) [0|1] "" Vector__XXX
SG_ TimingViolation10msTask : 2|1@0+ (1,0) [0|1] "" Vector__XXX
SG_ TimingViolation100msTask : 3|1@0+ (1,0) [0|1] "" Vector__XXX
SG_ TimingViolation100msAlgoTask : 4|1@0+ (1,0) [0|1] "" Vector__XXX
SG_ TimingViolation10msTaskRecorded : 10|1@0+ (1,0) [0|1] "" Vector__XXX
SG_ TimingViolation100msTaskRecorded : 11|1@0+ (1,0) [0|1] "" Vector__XXX
SG_ TimingViolation100msAlgoTaskReco : 12|1@0+ (1,0) [0|1] "" Vector__XXX
SG_ TimingViolationEngineTaskRecorde : 8|1@0+ (1,0) [0|1] "" Vector__XXX
SG_ TimingViolation1msTaskRecorded : 9|1@0+ (1,0) [0|1] "" Vector__XXX

BO_ 528 f_BmsStateRequest: 8 Vector__XXX
SG_ RequestBmsMode : 1|2@0+ (1,0) [0|3] "" Vector__XXX
SG_ ActivateBalancing : 8|1@0+ (1,0) [0|1] "" Vector__XXX
SG_ SetBalancingThreshold : 23|8@0+ (1,0) [0|255] "mV" Vector__XXX
SG_ IndicatePrechargeType : 3|1@0+ (1,0) [0|1] "" Vector__XXX
SG_ ResetPersistentFlags : 2|1@0+ (1,0) [0|1] "" Vector__XXX
SG_ ChargerConnected : 4|1@0+ (1,0) [0|1] "" Vector__XXX
SG_ DisableInsulationMonitoring : 5|1@0+ (1,0) [0|1] "" Vector__XXX

BO_ 1040 f_BootloaderVersionInfo: 8 Vector__XXX
SG_ f_BootloaderVersionInfo_Mux M : 7|8@0+ (1,0) [0|0] "" Vector__XXX
SG_ DirtyFlag m0 : 33|1@0+ (1,0) [0|1] "" Vector__XXX
SG_ MajorVersionNumber m0 : 15|8@0+ (1,0) [0|255] "" Vector__XXX
SG_ MinorVersionNumber m0 : 23|8@0+ (1,0) [0|255] "" Vector__XXX
SG_ PatchVersionNumber m0 : 31|8@0+ (1,0) [0|255] "" Vector__XXX
SG_ ReleaseDistance m0 : 39|5@0+ (1,0) [0|31] "" Vector__XXX
SG_ ReleaseDistanceOverflow m0 : 34|1@0+ (1,0) [0|1] "" Vector__XXX
SG_ UnderVersionControl m0 : 32|1@0+ (1,0) [0|1] "" Vector__XXX
SG_ MagicBootData m15 : 15|56@0+ (1,0) [0|1] "" Vector__XXX
SG_ shortHash5 m5 : 15|56@0+ (1,0) [0|0] "" Vector__XXX
SG_ shortHash6 m6 : 15|56@0+ (1,0) [0|0] "" Vector__XXX

CM_ BO_ 640 "Cell temperature measurement data (in:can_cbs_rx_afe_cell-temperatures.c:CANRX_CellTemperatures, fv:rx, type:Cell Information)";
CM_ SG_ 640 CellTemperature_000 "Temperature of cell 0";
CM_ SG_ 640 CellTemperature_001 "Temperature of cell 1";
CM_ SG_ 640 CellTemperature_002 "Temperature of cell 2";
CM_ SG_ 640 CellTemperature_003 "Temperature of cell 3";
CM_ SG_ 640 CellTemperature_004 "Temperature of cell 4";
CM_ SG_ 640 CellTemperature_005 "Temperature of cell 5";
CM_ SG_ 640 CellTemperature_006 "Temperature of cell 6";
CM_ SG_ 640 CellTemperature_007 "Temperature of cell 7";
CM_ SG_ 640 CellTemperature_008 "Temperature of cell 8";
CM_ SG_ 640 CellTemperature_009 "Temperature of cell 9";
CM_ SG_ 640 CellTemperature_010 "Temperature of cell 10";
CM_ SG_ 640 CellTemperature_011 "Temperature of cell 11";
CM_ SG_ 640 CellTemperature_012 "Temperature of cell 12";
CM_ SG_ 640 CellTemperature_013 "Temperature of cell 13";
CM_ SG_ 640 CellTemperature_014 "Temperature of cell 14";
CM_ SG_ 640 CellTemperature_015 "Temperature of cell 15";
CM_ SG_ 640 CellTemperature_016 "Temperature of cell 16";
CM_ SG_ 640 CellTemperature_017 "Temperature of cell 17";
CM_ SG_ 640 CellTemperature_018 "Temperature of cell 18";
CM_ SG_ 640 CellTemperature_019 "Temperature of cell 19";
CM_ SG_ 640 CellTemperature_020 "Temperature of cell 20";
CM_ SG_ 640 CellTemperature_021 "Temperature of cell 21";
CM_ SG_ 640 CellTemperature_022 "Temperature of cell 22";
CM_ SG_ 640 CellTemperature_023 "Temperature of cell 23";
CM_ SG_ 640 CellTemperature_024 "Temperature of cell 24";
CM_ SG_ 640 CellTemperature_025 "Temperature of cell 25";
CM_ SG_ 640 CellTemperature_026 "Temperature of cell 26";
CM_ SG_ 640 CellTemperature_027 "Temperature of cell 27";
CM_ SG_ 640 CellTemperature_028 "Temperature of cell 28";
CM_ SG_ 640 CellTemperature_029 "Temperature of cell 29";
CM_ SG_ 640 CellTemperature_030 "Temperature of cell 30";
CM_ SG_ 640 CellTemperature_031 "Temperature of cell 31";
CM_ SG_ 640 CellTemperature_032 "Temperature of cell 32";
CM_ SG_ 640 CellTemperature_033 "Temperature of cell 33";
CM_ SG_ 640 CellTemperature_034 "Temperature of cell 34";
CM_ SG_ 640 CellTemperature_035 "Temperature of cell 35";
CM_ SG_ 640 CellTemperature_036 "Temperature of cell 36";
CM_ SG_ 640 CellTemperature_037 "Temperature of cell 37";
CM_ SG_ 640 CellTemperature_038 "Temperature of cell 38";
CM_ SG_ 640 CellTemperature_039 "Temperature of cell 39";
CM_ SG_ 640 CellTemperature_040 "Temperature of cell 40";
CM_ SG_ 640 CellTemperature_041 "Temperature of cell 41";
CM_ SG_ 640 CellTemperature_042 "Temperature of cell 42";
CM_ SG_ 640 CellTemperature_043 "Temperature of cell 43";
CM_ SG_ 640 CellTemperature_044 "Temperature of cell 44";
CM_ SG_ 640 CellTemperature_045 "Temperature of cell 45";
CM_ SG_ 640 CellTemperature_046 "Temperature of cell 46";
CM_ SG_ 640 CellTemperature_047 "Temperature of cell 47";
CM_ SG_ 640 CellTemperature_048 "Temperature of cell 48";
CM_ SG_ 640 CellTemperature_049 "Temperature of cell 49";
CM_ SG_ 640 CellTemperature_050 "Temperature of cell 50";
CM_ SG_ 640 CellTemperature_051 "Temperature of cell 51";
CM_ SG_ 640 CellTemperature_052 "Temperature of cell 52";
CM_ SG_ 640 CellTemperature_053 "Temperature of cell 53";
CM_ SG_ 640 CellTemperature_054 "Temperature of cell 54";
CM_ SG_ 640 CellTemperature_055 "Temperature of cell 55";
CM_ SG_ 640 CellTemperature_056 "Temperature of cell 56";
CM_ SG_ 640 CellTemperature_057 "Temperature of cell 57";
CM_ SG_ 640 CellTemperature_058 "Temperature of cell 58";
CM_ SG_ 640 CellTemperature_059 "Temperature of cell 59";
CM_ SG_ 640 CellTemperature_060 "Temperature of cell 60";
CM_ SG_ 640 CellTemperature_061 "Temperature of cell 61";
CM_ SG_ 640 CellTemperature_062 "Temperature of cell 62";
CM_ SG_ 640 CellTemperature_063 "Temperature of cell 63";
CM_ SG_ 640 CellTemperature_064 "Temperature of cell 64";
CM_ SG_ 640 CellTemperature_065 "Temperature of cell 65";
CM_ SG_ 640 CellTemperature_066 "Temperature of cell 66";
CM_ SG_ 640 CellTemperature_067 "Temperature of cell 67";
CM_ SG_ 640 CellTemperature_068 "Temperature of cell 68";
CM_ SG_ 640 CellTemperature_069 "Temperature of cell 69";
CM_ SG_ 640 CellTemperature_070 "Temperature of cell 70";
CM_ SG_ 640 CellTemperature_071 "Temperature of cell 71";
CM_ SG_ 640 CellTemperature_072 "Temperature of cell 72";
CM_ SG_ 640 CellTemperature_073 "Temperature of cell 73";
CM_ SG_ 640 CellTemperature_074 "Temperature of cell 74";
CM_ SG_ 640 CellTemperature_075 "Temperature of cell 75";
CM_ SG_ 640 CellTemperature_076 "Temperature of cell 76";
CM_ SG_ 640 CellTemperature_077 "Temperature of cell 77";
CM_ SG_ 640 CellTemperature_078 "Temperature of cell 78";
CM_ SG_ 640 CellTemperature_079 "Temperature of cell 79";
CM_ SG_ 640 CellTemperature_080 "Temperature of cell 80";
CM_ SG_ 640 CellTemperature_081 "Temperature of cell 81";
CM_ SG_ 640 CellTemperature_082 "Temperature of cell 82";
CM_ SG_ 640 CellTemperature_083 "Temperature of cell 83";
CM_ SG_ 640 CellTemperature_084 "Temperature of cell 84";
CM_ SG_ 640 CellTemperature_085 "Temperature of cell 85";
CM_ SG_ 640 CellTemperature_086 "Temperature of cell 86";
CM_ SG_ 640 CellTemperature_087 "Temperature of cell 87";
CM_ SG_ 640 CellTemperature_088 "Temperature of cell 88";
CM_ SG_ 640 CellTemperature_089 "Temperature of cell 89";
CM_ SG_ 640 CellTemperature_090 "Temperature of cell 90";
CM_ SG_ 640 CellTemperature_091 "Temperature of cell 91";
CM_ SG_ 640 CellTemperature_092 "Temperature of cell 92";
CM_ SG_ 640 CellTemperature_093 "Temperature of cell 93";
CM_ SG_ 640 CellTemperature_094 "Temperature of cell 94";
CM_ SG_ 640 CellTemperature_095 "Temperature of cell 95";
CM_ SG_ 640 CellTemperature_096 "Temperature of cell 96";
CM_ SG_ 640 CellTemperature_097 "Temperature of cell 97";
CM_ SG_ 640 CellTemperature_098 "Temperature of cell 98";
CM_ SG_ 640 CellTemperature_099 "Temperature of cell 99";
CM_ SG_ 640 CellTemperature_100 "Temperature of cell 100";
CM_ SG_ 640 CellTemperature_101 "Temperature of cell 101";
CM_ SG_ 640 CellTemperature_102 "Temperature of cell 102";
CM_ SG_ 640 CellTemperature_103 "Temperature of cell 103";
CM_ SG_ 640 CellTemperature_104 "Temperature of cell 104";
CM_ SG_ 640 CellTemperature_105 "Temperature of cell 105";
CM_ SG_ 640 CellTemperature_106 "Temperature of cell 106";
CM_ SG_ 640 CellTemperature_107 "Temperature of cell 107";
CM_ SG_ 640 CellTemperature_108 "Temperature of cell 108";
CM_ SG_ 640 CellTemperature_109 "Temperature of cell 109";
CM_ SG_ 640 CellTemperature_110 "Temperature of cell 110";
CM_ SG_ 640 CellTemperature_111 "Temperature of cell 111";
CM_ SG_ 640 CellTemperature_112 "Temperature of cell 112";
CM_ SG_ 640 CellTemperature_113 "Temperature of cell 113";
CM_ SG_ 640 CellTemperature_114 "Temperature of cell 114";
CM_ SG_ 640 CellTemperature_115 "Temperature of cell 115";
CM_ SG_ 640 CellTemperature_116 "Temperature of cell 116";
CM_ SG_ 640 CellTemperature_117 "Temperature of cell 117";
CM_ SG_ 640 CellTemperature_118 "Temperature of cell 118";
CM_ SG_ 640 CellTemperature_119 "Temperature of cell 119";
CM_ SG_ 640 CellTemperature_120 "Temperature of cell 120";
CM_ SG_ 640 CellTemperature_121 "Temperature of cell 121";
CM_ SG_ 640 CellTemperature_122 "Temperature of cell 122";
CM_ SG_ 640 CellTemperature_123 "Temperature of cell 123";
CM_ SG_ 640 CellTemperature_124 "Temperature of cell 124";
CM_ SG_ 640 CellTemperature_125 "Temperature of cell 125";
CM_ SG_ 640 CellTemperature_126 "Temperature of cell 126";
CM_ SG_ 640 CellTemperature_127 "Temperature of cell 127";
CM_ SG_ 640 CellTemperature_128 "Temperature of cell 128";
CM_ SG_ 640 CellTemperature_129 "Temperature of cell 129";
CM_ SG_ 640 CellTemperature_130 "Temperature of cell 130";
CM_ SG_ 640 CellTemperature_131 "Temperature of cell 131";
CM_ SG_ 640 CellTemperature_132 "Temperature of cell 132";
CM_ SG_ 640 CellTemperature_133 "Temperature of cell 133";
CM_ SG_ 640 CellTemperature_134 "Temperature of cell 134";
CM_ SG_ 640 CellTemperature_135 "Temperature of cell 135";
CM_ SG_ 640 CellTemperature_136 "Temperature of cell 136";
CM_ SG_ 640 CellTemperature_137 "Temperature of cell 137";
CM_ SG_ 640 CellTemperature_138 "Temperature of cell 138";
CM_ SG_ 640 CellTemperature_139 "Temperature of cell 139";
CM_ SG_ 640 CellTemperature_140 "Temperature of cell 140";
CM_ SG_ 640 CellTemperature_141 "Temperature of cell 141";
CM_ SG_ 640 CellTemperature_142 "Temperature of cell 142";
CM_ SG_ 640 CellTemperature_143 "Temperature of cell 143";
CM_ SG_ 640 CellTemperature_144 "Temperature of cell 144";
CM_ SG_ 640 CellTemperature_145 "Temperature of cell 145";
CM_ SG_ 640 CellTemperature_146 "Temperature of cell 146";
CM_ SG_ 640 CellTemperature_147 "Temperature of cell 147";
CM_ SG_ 640 CellTemperature_148 "Temperature of cell 148";
CM_ SG_ 640 CellTemperature_149 "Temperature of cell 149";
CM_ SG_ 640 CellTemperature_150 "Temperature of cell 150";
CM_ SG_ 640 CellTemperature_151 "Temperature of cell 151";
CM_ SG_ 640 CellTemperature_152 "Temperature of cell 152";
CM_ SG_ 640 CellTemperature_153 "Temperature of cell 153";
CM_ SG_ 640 CellTemperature_154 "Temperature of cell 154";
CM_ SG_ 640 CellTemperature_155 "Temperature of cell 155";
CM_ SG_ 640 CellTemperature_156 "Temperature of cell 156";
CM_ SG_ 640 CellTemperature_157 "Temperature of cell 157";
CM_ SG_ 640 CellTemperature_158 "Temperature of cell 158";
CM_ SG_ 640 CellTemperature_159 "Temperature of cell 159";
CM_ SG_ 640 CellTemperature_160 "Temperature of cell 160";
CM_ SG_ 640 CellTemperature_161 "Temperature of cell 161";
CM_ SG_ 640 CellTemperature_162 "Temperature of cell 162";
CM_ SG_ 640 CellTemperature_163 "Temperature of cell 163";
CM_ SG_ 640 CellTemperature_164 "Temperature of cell 164";
CM_ SG_ 640 CellTemperature_165 "Temperature of cell 165";
CM_ SG_ 640 CellTemperature_166 "Temperature of cell 166";
CM_ SG_ 640 CellTemperature_167 "Temperature of cell 167";
CM_ SG_ 640 CellTemperature_168 "Temperature of cell 168";
CM_ SG_ 640 CellTemperature_169 "Temperature of cell 169";
CM_ SG_ 640 CellTemperature_170 "Temperature of cell 170";
CM_ SG_ 640 CellTemperature_171 "Temperature of cell 171";
CM_ SG_ 640 CellTemperature_172 "Temperature of cell 172";
CM_ SG_ 640 CellTemperature_173 "Temperature of cell 173";
CM_ SG_ 640 CellTemperature_174 "Temperature of cell 174";
CM_ SG_ 640 CellTemperature_175 "Temperature of cell 175";
CM_ SG_ 640 CellTemperature_176 "Temperature of cell 176";
CM_ SG_ 640 CellTemperature_177 "Temperature of cell 177";
CM_ SG_ 640 CellTemperature_178 "Temperature of cell 178";
CM_ SG_ 640 CellTemperature_179 "Temperature of cell 179";
CM_ BO_ 624 "Cell voltage measurement data (in:can_cbs_rx_afe_cell-voltages.c:CANRX_CellVoltages, fv:rx, type:Cell Information)";
CM_ SG_ 624 CellVoltage_000 "Voltage of cell 0";
CM_ SG_ 624 CellVoltage_001 "Voltage of cell 1";
CM_ SG_ 624 CellVoltage_002 "Voltage of cell 2";
CM_ SG_ 624 CellVoltage_003 "Voltage of cell 3";
CM_ SG_ 624 CellVoltage_004 "Voltage of cell 4";
CM_ SG_ 624 CellVoltage_005 "Voltage of cell 5";
CM_ SG_ 624 CellVoltage_006 "Voltage of cell 6";
CM_ SG_ 624 CellVoltage_007 "Voltage of cell 7";
CM_ SG_ 624 CellVoltage_008 "Voltage of cell 8";
CM_ SG_ 624 CellVoltage_009 "Voltage of cell 9";
CM_ SG_ 624 CellVoltage_010 "Voltage of cell 10";
CM_ SG_ 624 CellVoltage_011 "Voltage of cell 11";
CM_ SG_ 624 CellVoltage_012 "Voltage of cell 12";
CM_ SG_ 624 CellVoltage_013 "Voltage of cell 13";
CM_ SG_ 624 CellVoltage_014 "Voltage of cell 14";
CM_ SG_ 624 CellVoltage_015 "Voltage of cell 15";
CM_ SG_ 624 CellVoltage_016 "Voltage of cell 16";
CM_ SG_ 624 CellVoltage_017 "Voltage of cell 17";
CM_ SG_ 624 CellVoltage_018 "Voltage of cell 18";
CM_ SG_ 624 CellVoltage_019 "Voltage of cell 19";
CM_ SG_ 624 CellVoltage_020 "Voltage of cell 20";
CM_ SG_ 624 CellVoltage_021 "Voltage of cell 21";
CM_ SG_ 624 CellVoltage_022 "Voltage of cell 22";
CM_ SG_ 624 CellVoltage_023 "Voltage of cell 23";
CM_ SG_ 624 CellVoltage_024 "Voltage of cell 24";
CM_ SG_ 624 CellVoltage_025 "Voltage of cell 25";
CM_ SG_ 624 CellVoltage_026 "Voltage of cell 26";
CM_ SG_ 624 CellVoltage_027 "Voltage of cell 27";
CM_ SG_ 624 CellVoltage_028 "Voltage of cell 28";
CM_ SG_ 624 CellVoltage_029 "Voltage of cell 29";
CM_ SG_ 624 CellVoltage_030 "Voltage of cell 30";
CM_ SG_ 624 CellVoltage_031 "Voltage of cell 31";
CM_ SG_ 624 CellVoltage_032 "Voltage of cell 32";
CM_ SG_ 624 CellVoltage_033 "Voltage of cell 33";
CM_ SG_ 624 CellVoltage_034 "Voltage of cell 34";
CM_ SG_ 624 CellVoltage_035 "Voltage of cell 35";
CM_ SG_ 624 CellVoltage_036 "Voltage of cell 36";
CM_ SG_ 624 CellVoltage_037 "Voltage of cell 37";
CM_ SG_ 624 CellVoltage_038 "Voltage of cell 38";
CM_ SG_ 624 CellVoltage_039 "Voltage of cell 39";
CM_ SG_ 624 CellVoltage_040 "Voltage of cell 40";
CM_ SG_ 624 CellVoltage_041 "Voltage of cell 41";
CM_ SG_ 624 CellVoltage_042 "Voltage of cell 42";
CM_ SG_ 624 CellVoltage_043 "Voltage of cell 43";
CM_ SG_ 624 CellVoltage_044 "Voltage of cell 44";
CM_ SG_ 624 CellVoltage_045 "Voltage of cell 45";
CM_ SG_ 624 CellVoltage_046 "Voltage of cell 46";
CM_ SG_ 624 CellVoltage_047 "Voltage of cell 47";
CM_ SG_ 624 CellVoltage_048 "Voltage of cell 48";
CM_ SG_ 624 CellVoltage_049 "Voltage of cell 49";
CM_ SG_ 624 CellVoltage_050 "Voltage of cell 50";
CM_ SG_ 624 CellVoltage_051 "Voltage of cell 51";
CM_ SG_ 624 CellVoltage_052 "Voltage of cell 52";
CM_ SG_ 624 CellVoltage_053 "Voltage of cell 53";
CM_ SG_ 624 CellVoltage_054 "Voltage of cell 54";
CM_ SG_ 624 CellVoltage_055 "Voltage of cell 55";
CM_ SG_ 624 CellVoltage_056 "Voltage of cell 56";
CM_ SG_ 624 CellVoltage_057 "Voltage of cell 57";
CM_ SG_ 624 CellVoltage_058 "Voltage of cell 58";
CM_ SG_ 624 CellVoltage_059 "Voltage of cell 59";
CM_ SG_ 624 CellVoltage_060 "Voltage of cell 60";
CM_ SG_ 624 CellVoltage_061 "Voltage of cell 61";
CM_ SG_ 624 CellVoltage_062 "Voltage of cell 62";
CM_ SG_ 624 CellVoltage_063 "Voltage of cell 63";
CM_ SG_ 624 CellVoltage_064 "Voltage of cell 64";
CM_ SG_ 624 CellVoltage_065 "Voltage of cell 65";
CM_ SG_ 624 CellVoltage_066 "Voltage of cell 66";
CM_ SG_ 624 CellVoltage_067 "Voltage of cell 67";
CM_ SG_ 624 CellVoltage_068 "Voltage of cell 68";
CM_ SG_ 624 CellVoltage_069 "Voltage of cell 69";
CM_ SG_ 624 CellVoltage_070 "Voltage of cell 70";
CM_ SG_ 624 CellVoltage_071 "Voltage of cell 71";
CM_ SG_ 624 CellVoltage_072 "Voltage of cell 72";
CM_ SG_ 624 CellVoltage_073 "Voltage of cell 73";
CM_ SG_ 624 CellVoltage_074 "Voltage of cell 74";
CM_ SG_ 624 CellVoltage_075 "Voltage of cell 75";
CM_ SG_ 624 CellVoltage_076 "Voltage of cell 76";
CM_ SG_ 624 CellVoltage_077 "Voltage of cell 77";
CM_ SG_ 624 CellVoltage_078 "Voltage of cell 78";
CM_ SG_ 624 CellVoltage_079 "Voltage of cell 79";
CM_ SG_ 624 CellVoltage_080 "Voltage of cell 80";
CM_ SG_ 624 CellVoltage_081 "Voltage of cell 81";
CM_ SG_ 624 CellVoltage_082 "Voltage of cell 82";
CM_ SG_ 624 CellVoltage_083 "Voltage of cell 83";
CM_ SG_ 624 CellVoltage_084 "Voltage of cell 84";
CM_ SG_ 624 CellVoltage_085 "Voltage of cell 85";
CM_ SG_ 624 CellVoltage_086 "Voltage of cell 86";
CM_ SG_ 624 CellVoltage_087 "Voltage of cell 87";
CM_ SG_ 624 CellVoltage_088 "Voltage of cell 88";
CM_ SG_ 624 CellVoltage_089 "Voltage of cell 89";
CM_ SG_ 624 CellVoltage_090 "Voltage of cell 90";
CM_ SG_ 624 CellVoltage_091 "Voltage of cell 91";
CM_ SG_ 624 CellVoltage_092 "Voltage of cell 92";
CM_ SG_ 624 CellVoltage_093 "Voltage of cell 93";
CM_ SG_ 624 CellVoltage_094 "Voltage of cell 94";
CM_ SG_ 624 CellVoltage_095 "Voltage of cell 95";
CM_ SG_ 624 CellVoltage_096 "Voltage of cell 96";
CM_ SG_ 624 CellVoltage_097 "Voltage of cell 97";
CM_ SG_ 624 CellVoltage_098 "Voltage of cell 98";
CM_ SG_ 624 CellVoltage_099 "Voltage of cell 99";
CM_ SG_ 624 CellVoltage_100 "Voltage of cell 100";
CM_ SG_ 624 CellVoltage_101 "Voltage of cell 101";
CM_ SG_ 624 CellVoltage_102 "Voltage of cell 102";
CM_ SG_ 624 CellVoltage_103 "Voltage of cell 103";
CM_ SG_ 624 CellVoltage_104 "Voltage of cell 104";
CM_ SG_ 624 CellVoltage_105 "Voltage of cell 105";
CM_ SG_ 624 CellVoltage_106 "Voltage of cell 106";
CM_ SG_ 624 CellVoltage_107 "Voltage of cell 107";
CM_ SG_ 624 CellVoltage_108 "Voltage of cell 108";
CM_ SG_ 624 CellVoltage_109 "Voltage of cell 109";
CM_ SG_ 624 CellVoltage_110 "Voltage of cell 110";
CM_ SG_ 624 CellVoltage_111 "Voltage of cell 111";
CM_ SG_ 624 CellVoltage_112 "Voltage of cell 112";
CM_ SG_ 624 CellVoltage_113 "Voltage of cell 113";
CM_ SG_ 624 CellVoltage_114 "Voltage of cell 114";
CM_ SG_ 624 CellVoltage_115 "Voltage of cell 115";
CM_ SG_ 624 CellVoltage_116 "Voltage of cell 116";
CM_ SG_ 624 CellVoltage_117 "Voltage of cell 117";
CM_ SG_ 624 CellVoltage_118 "Voltage of cell 118";
CM_ SG_ 624 CellVoltage_119 "Voltage of cell 119";
CM_ SG_ 624 CellVoltage_120 "Voltage of cell 120";
CM_ SG_ 624 CellVoltage_121 "Voltage of cell 121";
CM_ SG_ 624 CellVoltage_122 "Voltage of cell 122";
CM_ SG_ 624 CellVoltage_123 "Voltage of cell 123";
CM_ SG_ 624 CellVoltage_124 "Voltage of cell 124";
CM_ SG_ 624 CellVoltage_125 "Voltage of cell 125";
CM_ SG_ 624 CellVoltage_126 "Voltage of cell 126";
CM_ SG_ 624 CellVoltage_127 "Voltage of cell 127";
CM_ SG_ 624 CellVoltage_128 "Voltage of cell 128";
CM_ SG_ 624 CellVoltage_129 "Voltage of cell 129";
CM_ SG_ 624 CellVoltage_130 "Voltage of cell 130";
CM_ SG_ 624 CellVoltage_131 "Voltage of cell 131";
CM_ SG_ 624 CellVoltage_132 "Voltage of cell 132";
CM_ SG_ 624 CellVoltage_133 "Voltage of cell 133";
CM_ SG_ 624 CellVoltage_134 "Voltage of cell 134";
CM_ SG_ 624 CellVoltage_135 "Voltage of cell 135";
CM_ SG_ 624 CellVoltage_136 "Voltage of cell 136";
CM_ SG_ 624 CellVoltage_137 "Voltage of cell 137";
CM_ SG_ 624 CellVoltage_138 "Voltage of cell 138";
CM_ SG_ 624 CellVoltage_139 "Voltage of cell 139";
CM_ SG_ 624 CellVoltage_140 "Voltage of cell 140";
CM_ SG_ 624 CellVoltage_141 "Voltage of cell 141";
CM_ SG_ 624 CellVoltage_142 "Voltage of cell 142";
CM_ SG_ 624 CellVoltage_143 "Voltage of cell 143";
CM_ SG_ 624 CellVoltage_144 "Voltage of cell 144";
CM_ SG_ 624 CellVoltage_145 "Voltage of cell 145";
CM_ SG_ 624 CellVoltage_146 "Voltage of cell 146";
CM_ SG_ 624 CellVoltage_147 "Voltage of cell 147";
CM_ SG_ 624 CellVoltage_148 "Voltage of cell 148";
CM_ SG_ 624 CellVoltage_149 "Voltage of cell 149";
CM_ SG_ 624 CellVoltage_150 "Voltage of cell 150";
CM_ SG_ 624 CellVoltage_151 "Voltage of cell 151";
CM_ SG_ 624 CellVoltage_152 "Voltage of cell 152";
CM_ SG_ 624 CellVoltage_153 "Voltage of cell 153";
CM_ SG_ 624 CellVoltage_154 "Voltage of cell 154";
CM_ SG_ 624 CellVoltage_155 "Voltage of cell 155";
CM_ SG_ 624 CellVoltage_156 "Voltage of cell 156";
CM_ SG_ 624 CellVoltage_157 "Voltage of cell 157";
CM_ SG_ 624 CellVoltage_158 "Voltage of cell 158";
CM_ SG_ 624 CellVoltage_159 "Voltage of cell 159";
CM_ SG_ 624 CellVoltage_160 "Voltage of cell 160";
CM_ SG_ 624 CellVoltage_161 "Voltage of cell 161";
CM_ SG_ 624 CellVoltage_162 "Voltage of cell 162";
CM_ SG_ 624 CellVoltage_163 "Voltage of cell 163";
CM_ SG_ 624 CellVoltage_164 "Voltage of cell 164";
CM_ SG_ 624 CellVoltage_165 "Voltage of cell 165";
CM_ SG_ 624 CellVoltage_166 "Voltage of cell 166";
CM_ SG_ 624 CellVoltage_167 "Voltage of cell 167";
CM_ SG_ 624 CellVoltage_168 "Voltage of cell 168";
CM_ SG_ 624 CellVoltage_169 "Voltage of cell 169";
CM_ SG_ 624 CellVoltage_170 "Voltage of cell 170";
CM_ SG_ 624 CellVoltage_171 "Voltage of cell 171";
CM_ SG_ 624 CellVoltage_172 "Voltage of cell 172";
CM_ SG_ 624 CellVoltage_173 "Voltage of cell 173";
CM_ SG_ 624 CellVoltage_174 "Voltage of cell 174";
CM_ SG_ 624 CellVoltage_175 "Voltage of cell 175";
CM_ SG_ 624 CellVoltage_176 "Voltage of cell 176";
CM_ SG_ 624 CellVoltage_177 "Voltage of cell 177";
CM_ SG_ 624 CellVoltage_178 "Voltage of cell 178";
CM_ SG_ 624 CellVoltage_179 "Voltage of cell 179";
CM_ SG_ 624 CellVoltage_180 "Voltage of cell 180";
CM_ SG_ 624 CellVoltage_181 "Voltage of cell 181";
CM_ SG_ 624 CellVoltage_182 "Voltage of cell 182";
CM_ SG_ 624 CellVoltage_183 "Voltage of cell 183";
CM_ SG_ 624 CellVoltage_184 "Voltage of cell 184";
CM_ SG_ 624 CellVoltage_185 "Voltage of cell 185";
CM_ SG_ 624 CellVoltage_186 "Voltage of cell 186";
CM_ SG_ 624 CellVoltage_187 "Voltage of cell 187";
CM_ SG_ 624 CellVoltage_188 "Voltage of cell 188";
CM_ SG_ 624 CellVoltage_189 "Voltage of cell 189";
CM_ SG_ 624 CellVoltage_190 "Voltage of cell 190";
CM_ SG_ 624 CellVoltage_191 "Voltage of cell 191";
CM_ SG_ 624 CellVoltage_192 "Voltage of cell 192";
CM_ SG_ 624 CellVoltage_193 "Voltage of cell 193";
CM_ SG_ 624 CellVoltage_194 "Voltage of cell 194";
CM_ SG_ 624 CellVoltage_195 "Voltage of cell 195";
CM_ SG_ 624 CellVoltage_196 "Voltage of cell 196";
CM_ SG_ 624 CellVoltage_197 "Voltage of cell 197";
CM_ SG_ 624 CellVoltage_198 "Voltage of cell 198";
CM_ SG_ 624 CellVoltage_199 "Voltage of cell 199";
CM_ SG_ 624 CellVoltage_200 "Voltage of cell 200";
CM_ SG_ 624 CellVoltage_201 "Voltage of cell 201";
CM_ SG_ 624 CellVoltage_202 "Voltage of cell 202";
CM_ SG_ 624 CellVoltage_203 "Voltage of cell 203";
CM_ SG_ 624 CellVoltage_204 "Voltage of cell 204";
CM_ SG_ 624 CellVoltage_205 "Voltage of cell 205";
CM_ SG_ 624 CellVoltage_206 "Voltage of cell 206";
CM_ SG_ 624 CellVoltage_207 "Voltage of cell 207";
CM_ SG_ 624 CellVoltage_208 "Voltage of cell 208";
CM_ SG_ 624 CellVoltage_209 "Voltage of cell 209";
CM_ SG_ 624 CellVoltage_210 "Voltage of cell 210";
CM_ SG_ 624 CellVoltage_211 "Voltage of cell 211";
CM_ SG_ 624 CellVoltage_212 "Voltage of cell 212";
CM_ SG_ 624 CellVoltage_213 "Voltage of cell 213";
CM_ SG_ 624 CellVoltage_214 "Voltage of cell 214";
CM_ SG_ 624 CellVoltage_215 "Voltage of cell 215";
CM_ BO_ 964 "(in:can_cbs_rx_as_honeywell-bas6c-x00.c:CANRX_AsHoneywellBas6cX00, fv:rx, type:Aerosol Sensor)";
CM_ BO_ 1319 "Current sensor string 0: coulomb counting (in:can_cbs_rx_cs_isabellenhuette-ivt-s.c:CANRX_CsIsabellenhuetteIvtS, fv:rx, type:Current Sensor)";
CM_ BO_ 1313 "Current sensor string 0: current (in:can_cbs_rx_cs_isabellenhuette-ivt-s.c:CANRX_CsIsabellenhuetteIvtS, fv:rx, type:Current Sensor)";
CM_ BO_ 1320 "Current sensor string 0: energy counting (in:can_cbs_rx_cs_isabellenhuette-ivt-s.c:CANRX_CsIsabellenhuetteIvtS, fv:rx, type:Current Sensor)";
CM_ BO_ 1318 "Current sensor string 0: power (in:can_cbs_rx_cs_isabellenhuette-ivt-s.c:CANRX_CsIsabellenhuetteIvtS, fv:rx, type:Current Sensor)";
CM_ BO_ 1317 "Current sensor string 0: temperature (in:can_cbs_rx_cs_isabellenhuette-ivt-s.c:CANRX_CsIsabellenhuetteIvtS, fv:rx, type:Current Sensor)";
CM_ BO_ 1314 "Current sensor string 0: voltage 1 (in:can_cbs_rx_cs_isabellenhuette-ivt-s.c:CANRX_CsIsabellenhuetteIvtS, fv:rx, type:Current Sensor)";
CM_ BO_ 1315 "Current sensor string 0: voltage 2 (in:can_cbs_rx_cs_isabellenhuette-ivt-s.c:CANRX_CsIsabellenhuetteIvtS, fv:rx, type:Current Sensor)";
CM_ BO_ 1316 "Current sensor string 0: voltage 3 (in:can_cbs_rx_cs_isabellenhuette-ivt-s.c:CANRX_CsIsabellenhuetteIvtS, fv:rx, type:Current Sensor)";
CM_ BO_ 962 "LEM Current Sensor (in:can_cbs_rx_cs_lem-cab500.c:CANRX_CsLemCab500, fv:rx, type:Current Sensor)";
CM_ SG_ 962 PRODUCT_NAME "CAB5 Product name";
CM_ SG_ 962 CSM_FAIL "Error information";
CM_ SG_ 962 ERROR_INDICATION "Error flag to validate sent current";
CM_ SG_ 962 CSM_BAT_CURRENT_mA "Battery current field uses 0x80000000 as zero value, 0x7FFFFFFF as -1 mA and 0x80000001 as 1mA";
CM_ BO_ 546 "Message contains the fatal error code (in:can_cbs_tx_f_fatal-error.c:CANTX_SendFatalErrorId, fv:tx, type:BMS Status)";
CM_ BO_ 544 "Message contains general BMS state information (in:can_cbs_tx_f_bms-state.c:CANTX_BmsState, fv:tx, type:BMS Status)";
CM_ SG_ 544 BmsState "Shows the internal state of the BMS state machine";
CM_ SG_ 544 NumberOfConnectedStrings "Shows the number of connected strings, i.e., the strings in which the contactors are closed";
CM_ SG_ 544 GeneralError "Indicates whether any error is present on the BMS or not";
CM_ SG_ 544 GeneralWarning "Indicates whether any warning is present on the BMS or not";
CM_ SG_ 544 McuDieTemperatureError "Indicates whether there is an MCU temperature error or not";
CM_ SG_ 544 BmsMasterPcbOvertemperatureError "Indicates whether a too high PCB temperature (i.e., overtemperature) of the BMS Master has been detected or not";
CM_ SG_ 544 BmsMasterPcbUndertemperatureErro "Indicates whether a too low PCB temperature (i.e., undertemperature) of the BMS Master has been detected or not";
CM_ SG_ 544 PrechargeVoltageError "Indicates whether precharging was successful or needed to aborted because of a too high voltage difference";
CM_ SG_ 544 PrechargeCurrentError "Indicates whether precharging was successful or needed to aborted because of a current limit violation";
CM_ SG_ 544 HeaterState "Indicates whether the heater is active or not";
CM_ SG_ 544 CoolingState "Indicates whether cooling is active or not";
CM_ SG_ 544 InsulationMonitoring "Indicates whether the insulation monitoring device is active or not";
CM_ SG_ 544 ChargingComplete "Indicates whether charging is completed or not";
CM_ SG_ 544 EmergencyShutoff "Indicates that the BMS is preparing to open the contactors soon due to detected error";
CM_ SG_ 544 MainFuseBlown "Indicates whether there is the main fuse is blown or not";
CM_ SG_ 544 InterlockState "Indicates whether the is closed or not";
CM_ SG_ 544 NumberOfDeactivatedStrings "Shows the number of not connected strings, i.e., the strings in which the contactors are open";
CM_ SG_ 544 InsulationError "Indicates whether an insulation error has been detected or not";
CM_ SG_ 544 CanTimingError "Indicates whether there is CAN timing error or not";
CM_ SG_ 544 PackOvercurrentChargeError "Indicates whether a too high pack current (i.e., overcurrent) has been detected during charing or not";
CM_ SG_ 544 PackOvercurrentDischargeError "Indicates whether a too high pack current (i.e., overcurrent) has been detected during discharging or not";
CM_ SG_ 544 SystemMonitoringError "Indicates whether a task has violated its timing requirements";
CM_ SG_ 544 AlertFlag "Indicates whether any alter flag is set or not";
CM_ SG_ 544 NvramCrcError "Indicates whether a CRC error has been detected in the NVRAM or not";
CM_ SG_ 544 Clamp30cError "Indicates a possible error with Clamp 30C supply";
CM_ SG_ 544 BalancingAlgorithmState "Indicates if the selected balancing algorithm allows balancing. This indicates not if a cell is actually balanced or not. This is indicated in IsBalancingActive flag in f_StringState message";
CM_ SG_ 544 BmsChargingFlag "Indicates that the bms is charging";
CM_ SG_ 544 PhyAlive "Indicates that the phy hardware is reachable";
CM_ SG_ 544 PhyLinked "Indicates that the phy has a network connection";
CM_ BO_ 545 "Details on flags transmitted by the 'BmsState' message (in:can_cbs_tx_f_bms-state-details.c:CANTX_BmsStateDetails, fv:tx, type:BMS Status)";
CM_ SG_ 545 TimingViolationEngineTask "Indicates whether the timing of the engine task has been violated.";
CM_ SG_ 545 TimingViolation1msTask "Indicates whether the timing of the 1ms task has been violated.";
CM_ SG_ 545 TimingViolation10msTask "Indicates whether the timing of the 10ms task has been violated.";
CM_ SG_ 545 TimingViolation100msTask "Indicates whether the timing of the 100ms task has been violated.";
CM_ SG_ 545 TimingViolation100msAlgoTask "Indicates whether the timing of the 100ms algorithm task has been violated.";
CM_ SG_ 545 TimingViolation10msTaskRecorded "Indicates whether a violation of the timing of the 10ms task has been recorded.";
CM_ SG_ 545 TimingViolation100msTaskRecorded "Indicates whether a violation of the timing of the 100ms task has been recorded.";
CM_ SG_ 545 TimingViolation100msAlgoTaskReco "Indicates whether a violation of the timing of the 100ms algorithm task has been recorded.";
CM_ SG_ 545 TimingViolationEngineTaskRecorde "Indicates whether a violation of the timing of the engine task has been recorded.";
CM_ SG_ 545 TimingViolation1msTaskRecorded "Indicates whether a violation of the timing of the 1ms task has been recorded.";
CM_ BO_ 528 "Requests specific BMS behavior and gives the BMS required information from the higher-level control unit (in:can_cbs_rx_f_bms-state-request.c:CANRX_BmsStateRequest, fv:rx, type:BMS Status)";
CM_ SG_ 528 RequestBmsMode "Instructs the BMS the to try to switch to the requested mode";
CM_ SG_ 528 ActivateBalancing "Instructs the BMS to activate/deactivate balancing";
CM_ SG_ 528 SetBalancingThreshold "Sets the required voltage difference to minimum cell voltage to activate balancing";
CM_ SG_ 528 IndicatePrechargeType "Notifies the BMS whether the battery system is externally precharged or not";
CM_ SG_ 528 ResetPersistentFlags "Instructs the BMS the to reset persistent flags";
CM_ SG_ 528 ChargerConnected "Tells the BMS whether a charger is connected or not";
CM_ SG_ 528 DisableInsulationMonitoring "Instructs the BMS to check/not check the battery system insulation";
CM_ BO_ 1040 "src/bootloader/driver/can/can_bootloader-version-info.c";

BA_DEF_  "BusType" STRING ;
BA_DEF_ BO_  "GenMsgCycleTime" INT 0 65535;
BA_DEF_ SG_  "GenSigStartValue" FLOAT -3.4E+038 3.4E+038;
BA_DEF_ SG_  "SigType" ENUM "Default","Range","RangeSigned","ASCII","Discrete","Control","ReferencePGN","DTC","StringDelimiter","StringLength","StringLengthControl","MessageCounter","MessageChecksum";

BA_DEF_DEF_  "BusType" "CAN";
BA_DEF_DEF_  "GenMsgCycleTime" 0;
BA_DEF_DEF_  "GenSigStartValue" 0;
BA_DEF_DEF_  "SigType" "Default";

BA_ "GenMsgCycleTime" BO_ 640 4500;
BA_ "GenMsgCycleTime" BO_ 624 5400;
BA_ "GenMsgCycleTime" BO_ 964 1000;
BA_ "GenMsgCycleTime" BO_ 544 100;
BA_ "GenMsgCycleTime" BO_ 545 1000;

BA_ "GenSigStartValue" SG_ 1319 IVT_ID_Result_As 6;
BA_ "GenSigStartValue" SG_ 1320 IVT_ID_Result_Wh 7;
BA_ "GenSigStartValue" SG_ 1318 IVT_ID_Result_W 5;
BA_ "GenSigStartValue" SG_ 1317 IVT_ID_Result_T 4;
BA_ "GenSigStartValue" SG_ 1314 IVT_ID_Result_U1 1;
BA_ "GenSigStartValue" SG_ 1315 IVT_ID_Result_U2 2;
BA_ "GenSigStartValue" SG_ 1316 IVT_ID_Result_U3 3;

BA_ "SigType" SG_ 1040 shortHash5 3;
BA_ "SigType" SG_ 1040 shortHash6 3;

VAL_ 640 AFE_CellTemperatures_Mux 0 "CellTemperatures_000_005" 1 "CellTemperatures_006_011" 2 "CellTemperatures_012_017" 3 "CellTemperatures_018_023" 4 "CellTemperatures_024_029" 5 "CellTemperatures_030_035" 6 "CellTemperatures_036_041" 7 "CellTemperatures_042_047" 8 "CellTemperatures_048_053" 9 "CellTemperatures_054_059" 10 "CellTemperatures_060_065" 11 "CellTemperatures_066_071" 12 "CellTemperatures_072_077" 13 "CellTemperatures_078_083" 14 "CellTemperatures_084_089" 15 "CellTemperatures_090_095" 16 "CellTemperatures_096_101" 17 "CellTemperatures_102_107" 18 "CellTemperatures_108_113" 19 "CellTemperatures_114_119" 20 "CellTemperatures_120_125" 21 "CellTemperatures_126_131" 22 "CellTemperatures_132_137" 23 "CellTemperatures_138_143" 24 "CellTemperatures_144_149" 25 "CellTemperatures_150_155" 26 "CellTemperatures_156_161" 27 "CellTemperatures_162_167" 28 "CellTemperatures_168_173" 29 "CellTemperatures_174_179";
VAL_ 624 AFE_CellVoltages_Mux 0 "CellVoltages_000_003" 1 "CellVoltages_004_007" 2 "CellVoltages_008_011" 3 "CellVoltages_012_015" 4 "CellVoltages_016_019" 5 "CellVoltages_020_023" 6 "CellVoltages_024_027" 7 "CellVoltages_028_031" 8 "CellVoltages_032_035" 9 "CellVoltages_036_039" 10 "CellVoltages_040_043" 11 "CellVoltages_044_047" 12 "CellVoltages_048_051" 13 "CellVoltages_052_055" 14 "CellVoltages_056_059" 15 "CellVoltages_060_063" 16 "CellVoltages_064_067" 17 "CellVoltages_068_071" 18 "CellVoltages_072_075" 19 "CellVoltages_076_079" 20 "CellVoltages_080_083" 21 "CellVoltages_084_087" 22 "CellVoltages_088_091" 23 "CellVoltages_092_095" 24 "CellVoltages_096_099" 25 "CellVoltages_100_103" 26 "CellVoltages_104_107" 27 "CellVoltages_108_111" 28 "CellVoltages_112_115" 29 "CellVoltages_116_119" 30 "CellVoltages_120_123" 31 "CellVoltages_124_127" 32 "CellVoltages_128_131" 33 "CellVoltages_132_135" 34 "CellVoltages_136_139" 35 "CellVoltages_140_143" 36 "CellVoltages_144_147" 37 "CellVoltages_148_151" 38 "CellVoltages_152_155" 39 "CellVoltages_156_159"
40 "CellVoltages_160_163" 41 "CellVoltages_164_167" 42 "CellVoltages_168_171" 43 "CellVoltages_172_175" 44 "CellVoltages_176_179" 45 "CellVoltages_180_183" 46 "CellVoltages_184_187" 47 "CellVoltages_188_191" 48 "CellVoltages_192_195" 49 "CellVoltages_196_199" 50 "CellVoltages_200_203" 51 "CellVoltages_204_207" 52 "CellVoltages_208_211" 53 "CellVoltages_212_215";
VAL_ 1040 f_BootloaderVersionInfo_Mux 0 "BootloaderVersionInfo" 15 "BootInformation" 5 "CommitHashHigh" 6 "CommitHashLow";
VAL_ 640 CellTemperature_000_invalidFlag 0 "Invalid" 1 "Valid";
VAL_ 640 CellTemperature_001_invalidFlag 0 "Invalid" 1 "Valid";
VAL_ 640 CellTemperature_002_invalidFlag 0 "Invalid" 1 "Valid";
VAL_ 640 CellTemperature_003_invalidFlag 0 "Invalid" 1 "Valid";
VAL_ 640 CellTemperature_004_invalidFlag 0 "Invalid" 1 "Valid";
VAL_ 640 CellTemperature_005_invalidFlag 0 "Invalid" 1 "Valid";
VAL_ 640 CellTemperature_006_invalidFlag 0 "Invalid" 1 "Valid";
VAL_ 640 CellTemperature_007_invalidFlag 0 "Invalid" 1 "Valid";
VAL_ 640 CellTemperature_008_invalidFlag 0 "Invalid" 1 "Valid";
VAL_ 640 CellTemperature_009_invalidFlag 0 "Invalid" 1 "Valid";
VAL_ 640 CellTemperature_010_invalidFlag 0 "Invalid" 1 "Valid";
VAL_ 640 CellTemperature_011_invalidFlag 0 "Invalid" 1 "Valid";
VAL_ 640 CellTemperature_012_invalidFlag 0 "Invalid" 1 "Valid";
VAL_ 640 CellTemperature_013_invalidFlag 0 "Invalid" 1 "Valid";
VAL_ 640 CellTemperature_014_invalidFlag 0 "Invalid" 1 "Valid";
VAL_ 640 CellTemperature_015_invalidFlag 0 "Invalid" 1 "Valid";
VAL_ 640 CellTemperature_016_invalidFlag 0 "Invalid" 1 "Valid";
VAL_ 640 CellTemperature_017_invalidFlag 0 "Invalid" 1 "Valid";
VAL_ 640 CellTemperature_018_invalidFlag 0 "Invalid" 1 "Valid";
VAL_ 640 CellTemperature_019_invalidFlag 0 "Invalid" 1 "Valid";
VAL_ 640 CellTemperature_020_invalidFlag 0 "Invalid" 1 "Valid";
VAL_ 640 CellTemperature_021_invalidFlag 0 "Invalid" 1 "Valid";
VAL_ 640 CellTemperature_022_invalidFlag 0 "Invalid" 1 "Valid";
VAL_ 640 CellTemperature_023_invalidFlag 0 "Invalid" 1 "Valid";
VAL_ 640 CellTemperature_024_invalidFlag 0 "Invalid" 1 "Valid";
VAL_ 640 CellTemperature_025_invalidFlag 0 "Invalid" 1 "Valid";
VAL_ 640 CellTemperature_026_invalidFlag 0 "Invalid" 1 "Valid";
VAL_ 640 CellTemperature_027_invalidFlag 0 "Invalid" 1 "Valid";
VAL_ 640 CellTemperature_028_invalidFlag 0 "Invalid" 1 "Valid";
VAL_ 640 CellTemperature_029_invalidFlag 0 "Invalid" 1 "Valid";
VAL_ 640 CellTemperature_030_invalidFlag 0 "Invalid" 1 "Valid";
VAL_ 640 CellTemperature_031_invalidFlag 0 "Invalid" 1 "Valid";
VAL_ 640 CellTemperature_032_invalidFlag 0 "Invalid" 1 "Valid";
VAL_ 640 CellTemperature_033_invalidFlag 0 "Invalid" 1 "Valid";
VAL_ 640 CellTemperature_034_invalidFlag 0 "Invalid" 1 "Valid";
VAL_ 640 CellTemperature_035_invalidFlag 0 "Invalid" 1 "Valid";
VAL_ 640 CellTemperature_036_invalidFlag 0 "Invalid" 1 "Valid";
VAL_ 640 CellTemperature_037_invalidFlag 0 "Invalid" 1 "Valid";
VAL_ 640 CellTemperature_038_invalidFlag 0 "Invalid" 1 "Valid";
VAL_ 640 CellTemperature_039_invalidFlag 0 "Invalid" 1 "Valid";
VAL_ 640 CellTemperature_040_invalidFlag 0 "Invalid" 1 "Valid";
VAL_ 640 CellTemperature_041_invalidFlag 0 "Invalid" 1 "Valid";
VAL_ 640 CellTemperature_042_invalidFlag 0 "Invalid" 1 "Valid";
VAL_ 640 CellTemperature_043_invalidFlag 0 "Invalid" 1 "Valid";
VAL_ 640 CellTemperature_044_invalidFlag 0 "Invalid" 1 "Valid";
VAL_ 640 CellTemperature_045_invalidFlag 0 "Invalid" 1 "Valid";
VAL_ 640 CellTemperature_046_invalidFlag 0 "Invalid" 1 "Valid";
VAL_ 640 CellTemperature_047_invalidFlag 0 "Invalid" 1 "Valid";
VAL_ 640 CellTemperature_048_invalidFlag 0 "Invalid" 1 "Valid";
VAL_ 640 CellTemperature_049_invalidFlag 0 "Invalid" 1 "Valid";
VAL_ 640 CellTemperature_050_invalidFlag 0 "Invalid" 1 "Valid";
VAL_ 640 CellTemperature_051_invalidFlag 0 "Invalid" 1 "Valid";
VAL_ 640 CellTemperature_052_invalidFlag 0 "Invalid" 1 "Valid";
VAL_ 640 CellTemperature_053_invalidFlag 0 "Invalid" 1 "Valid";
VAL_ 640 CellTemperature_054_invalidFlag 0 "Invalid" 1 "Valid";
VAL_ 640 CellTemperature_055_invalidFlag 0 "Invalid" 1 "Valid";
VAL_ 640 CellTemperature_056_invalidFlag 0 "Invalid" 1 "Valid";
VAL_ 640 CellTemperature_057_invalidFlag 0 "Invalid" 1 "Valid";
VAL_ 640 CellTemperature_058_invalidFlag 0 "Invalid" 1 "Valid";
VAL_ 640 CellTemperature_059_invalidFlag 0 "Invalid" 1 "Valid";
VAL_ 640 CellTemperature_060_invalidFlag 0 "Invalid" 1 "Valid";
VAL_ 640 CellTemperature_061_invalidFlag 0 "Invalid" 1 "Valid";
VAL_ 640 CellTemperature_062_invalidFlag 0 "Invalid" 1 "Valid";
VAL_ 640 CellTemperature_063_invalidFlag 0 "Invalid" 1 "Valid";
VAL_ 640 CellTemperature_064_invalidFlag 0 "Invalid" 1 "Valid";
VAL_ 640 CellTemperature_065_invalidFlag 0 "Invalid" 1 "Valid";
VAL_ 640 CellTemperature_066_invalidFlag 0 "Invalid" 1 "Valid";
VAL_ 640 CellTemperature_067_invalidFlag 0 "Invalid" 1 "Valid";
VAL_ 640 CellTemperature_068_invalidFlag 0 "Invalid" 1 "Valid";
VAL_ 640 CellTemperature_069_invalidFlag 0 "Invalid" 1 "Valid";
VAL_ 640 CellTemperature_070_invalidFlag 0 "Invalid" 1 "Valid";
VAL_ 640 CellTemperature_071_invalidFlag 0 "Invalid" 1 "Valid";
VAL_ 640 CellTemperature_072_invalidFlag 0 "Invalid" 1 "Valid";
VAL_ 640 CellTemperature_073_invalidFlag 0 "Invalid" 1 "Valid";
VAL_ 640 CellTemperature_074_invalidFlag 0 "Invalid" 1 "Valid";
VAL_ 640 CellTemperature_075_invalidFlag 0 "Invalid" 1 "Valid";
VAL_ 640 CellTemperature_076_invalidFlag 0 "Invalid" 1 "Valid";
VAL_ 640 CellTemperature_077_invalidFlag 0 "Invalid" 1 "Valid";
VAL_ 640 CellTemperature_078_invalidFlag 0 "Invalid" 1 "Valid";
VAL_ 640 CellTemperature_079_invalidFlag 0 "Invalid" 1 "Valid";
VAL_ 640 CellTemperature_080_invalidFlag 0 "Invalid" 1 "Valid";
VAL_ 640 CellTemperature_081_invalidFlag 0 "Invalid" 1 "Valid";
VAL_ 640 CellTemperature_082_invalidFlag 0 "Invalid" 1 "Valid";
VAL_ 640 CellTemperature_083_invalidFlag 0 "Invalid" 1 "Valid";
VAL_ 640 CellTemperature_084_invalidFlag 0 "Invalid" 1 "Valid";
VAL_ 640 CellTemperature_085_invalidFlag 0 "Invalid" 1 "Valid";
VAL_ 640 CellTemperature_086_invalidFlag 0 "Invalid" 1 "Valid";
VAL_ 640 CellTemperature_087_invalidFlag 0 "Invalid" 1 "Valid";
VAL_ 640 CellTemperature_088_invalidFlag 0 "Invalid" 1 "Valid";
VAL_ 640 CellTemperature_089_invalidFlag 0 "Invalid" 1 "Valid";
VAL_ 640 CellTemperature_090_invalidFlag 0 "Invalid" 1 "Valid";
VAL_ 640 CellTemperature_091_invalidFlag 0 "Invalid" 1 "Valid";
VAL_ 640 CellTemperature_092_invalidFlag 0 "Invalid" 1 "Valid";
VAL_ 640 CellTemperature_093_invalidFlag 0 "Invalid" 1 "Valid";
VAL_ 640 CellTemperature_094_invalidFlag 0 "Invalid" 1 "Valid";
VAL_ 640 CellTemperature_095_invalidFlag 0 "Invalid" 1 "Valid";
VAL_ 640 CellTemperature_096_invalidFlag 0 "Invalid" 1 "Valid";
VAL_ 640 CellTemperature_097_invalidFlag 0 "Invalid" 1 "Valid";
VAL_ 640 CellTemperature_098_invalidFlag 0 "Invalid" 1 "Valid";
VAL_ 640 CellTemperature_099_invalidFlag 0 "Invalid" 1 "Valid";
VAL_ 640 CellTemperature_100_invalidFlag 0 "Invalid" 1 "Valid";
VAL_ 640 CellTemperature_101_invalidFlag 0 "Invalid" 1 "Valid";
VAL_ 640 CellTemperature_102_invalidFlag 0 "Invalid" 1 "Valid";
VAL_ 640 CellTemperature_103_invalidFlag 0 "Invalid" 1 "Valid";
VAL_ 640 CellTemperature_104_invalidFlag 0 "Invalid" 1 "Valid";
VAL_ 640 CellTemperature_105_invalidFlag 0 "Invalid" 1 "Valid";
VAL_ 640 CellTemperature_106_invalidFlag 0 "Invalid" 1 "Valid";
VAL_ 640 CellTemperature_107_invalidFlag 0 "Invalid" 1 "Valid";
VAL_ 640 CellTemperature_108_invalidFlag 0 "Invalid" 1 "Valid";
VAL_ 640 CellTemperature_109_invalidFlag 0 "Invalid" 1 "Valid";
VAL_ 640 CellTemperature_110_invalidFlag 0 "Invalid" 1 "Valid";
VAL_ 640 CellTemperature_111_invalidFlag 0 "Invalid" 1 "Valid";
VAL_ 640 CellTemperature_112_invalidFlag 0 "Invalid" 1 "Valid";
VAL_ 640 CellTemperature_113_invalidFlag 0 "Invalid" 1 "Valid";
VAL_ 640 CellTemperature_114_invalidFlag 0 "Invalid" 1 "Valid";
VAL_ 640 CellTemperature_115_invalidFlag 0 "Invalid" 1 "Valid";
VAL_ 640 CellTemperature_116_invalidFlag 0 "Invalid" 1 "Valid";
VAL_ 640 CellTemperature_117_invalidFlag 0 "Invalid" 1 "Valid";
VAL_ 640 CellTemperature_118_invalidFlag 0 "Invalid" 1 "Valid";
VAL_ 640 CellTemperature_119_invalidFlag 0 "Invalid" 1 "Valid";
VAL_ 640 CellTemperature_120_invalidFlag 0 "Invalid" 1 "Valid";
VAL_ 640 CellTemperature_121_invalidFlag 0 "Invalid" 1 "Valid";
VAL_ 640 CellTemperature_122_invalidFlag 0 "Invalid" 1 "Valid";
VAL_ 640 CellTemperature_123_invalidFlag 0 "Invalid" 1 "Valid";
VAL_ 640 CellTemperature_124_invalidFlag 0 "Invalid" 1 "Valid";
VAL_ 640 CellTemperature_125_invalidFlag 0 "Invalid" 1 "Valid";
VAL_ 640 CellTemperature_126_invalidFlag 0 "Invalid" 1 "Valid";
VAL_ 640 CellTemperature_127_invalidFlag 0 "Invalid" 1 "Valid";
VAL_ 640 CellTemperature_128_invalidFlag 0 "Invalid" 1 "Valid";
VAL_ 640 CellTemperature_129_invalidFlag 0 "Invalid" 1 "Valid";
VAL_ 640 CellTemperature_130_invalidFlag 0 "Invalid" 1 "Valid";
VAL_ 640 CellTemperature_131_invalidFlag 0 "Invalid" 1 "Valid";
VAL_ 640 CellTemperature_132_invalidFlag 0 "Invalid" 1 "Valid";
VAL_ 640 CellTemperature_133_invalidFlag 0 "Invalid" 1 "Valid";
VAL_ 640 CellTemperature_134_invalidFlag 0 "Invalid" 1 "Valid";
VAL_ 640 CellTemperature_135_invalidFlag 0 "Invalid" 1 "Valid";
VAL_ 640 CellTemperature_136_invalidFlag 0 "Invalid" 1 "Valid";
VAL_ 640 CellTemperature_137_invalidFlag 0 "Invalid" 1 "Valid";
VAL_ 640 CellTemperature_138_invalidFlag 0 "Invalid" 1 "Valid";
VAL_ 640 CellTemperature_139_invalidFlag 0 "Invalid" 1 "Valid";
VAL_ 640 CellTemperature_140_invalidFlag 0 "Invalid" 1 "Valid";
VAL_ 640 CellTemperature_141_invalidFlag 0 "Invalid" 1 "Valid";
VAL_ 640 CellTemperature_142_invalidFlag 0 "Invalid" 1 "Valid";
VAL_ 640 CellTemperature_143_invalidFlag 0 "Invalid" 1 "Valid";
VAL_ 640 CellTemperature_144_invalidFlag 0 "Invalid" 1 "Valid";
VAL_ 640 CellTemperature_145_invalidFlag 0 "Invalid" 1 "Valid";
VAL_ 640 CellTemperature_146_invalidFlag 0 "Invalid" 1 "Valid";
VAL_ 640 CellTemperature_147_invalidFlag 0 "Invalid" 1 "Valid";
VAL_ 640 CellTemperature_148_invalidFlag 0 "Invalid" 1 "Valid";
VAL_ 640 CellTemperature_149_invalidFlag 0 "Invalid" 1 "Valid";
VAL_ 640 CellTemperature_150_invalidFlag 0 "Invalid" 1 "Valid";
VAL_ 640 CellTemperature_151_invalidFlag 0 "Invalid" 1 "Valid";
VAL_ 640 CellTemperature_152_invalidFlag 0 "Invalid" 1 "Valid";
VAL_ 640 CellTemperature_153_invalidFlag 0 "Invalid" 1 "Valid";
VAL_ 640 CellTemperature_154_invalidFlag 0 "Invalid" 1 "Valid";
VAL_ 640 CellTemperature_155_invalidFlag 0 "Invalid" 1 "Valid";
VAL_ 640 CellTemperature_156_invalidFlag 0 "Invalid" 1 "Valid";
VAL_ 640 CellTemperature_157_invalidFlag 0 "Invalid" 1 "Valid";
VAL_ 640 CellTemperature_158_invalidFlag 0 "Invalid" 1 "Valid";
VAL_ 640 CellTemperature_159_invalidFlag 0 "Invalid" 1 "Valid";
VAL_ 640 CellTemperature_160_invalidFlag 0 "Invalid" 1 "Valid";
VAL_ 640 CellTemperature_161_invalidFlag 0 "Invalid" 1 "Valid";
VAL_ 640 CellTemperature_162_invalidFlag 0 "Invalid" 1 "Valid";
VAL_ 640 CellTemperature_163_invalidFlag 0 "Invalid" 1 "Valid";
VAL_ 640 CellTemperature_164_invalidFlag 0 "Invalid" 1 "Valid";
VAL_ 640 CellTemperature_165_invalidFlag 0 "Invalid" 1 "Valid";
VAL_ 640 CellTemperature_166_invalidFlag 0 "Invalid" 1 "Valid";
VAL_ 640 CellTemperature_167_invalidFlag 0 "Invalid" 1 "Valid";
VAL_ 640 CellTemperature_168_invalidFlag 0 "Invalid" 1 "Valid";
VAL_ 640 CellTemperature_169_invalidFlag 0 "Invalid" 1 "Valid";
VAL_ 640 CellTemperature_170_invalidFlag 0 "Invalid" 1 "Valid";
VAL_ 640 CellTemperature_171_invalidFlag 0 "Invalid" 1 "Valid";
VAL_ 640 CellTemperature_172_invalidFlag 0 "Invalid" 1 "Valid";
VAL_ 640 CellTemperature_173_invalidFlag 0 "Invalid" 1 "Valid";
VAL_ 640 CellTemperature_174_invalidFlag 0 "Invalid" 1 "Valid";
VAL_ 640 CellTemperature_175_invalidFlag 0 "Invalid" 1 "Valid";
VAL_ 640 CellTemperature_176_invalidFlag 0 "Invalid" 1 "Valid";
VAL_ 640 CellTemperature_177_invalidFlag 0 "Invalid" 1 "Valid";
VAL_ 640 CellTemperature_178_invalidFlag 0 "Invalid" 1 "Valid";
VAL_ 640 CellTemperature_179_invalidFlag 0 "Invalid" 1 "Valid";
VAL_ 624 CellVoltage_000_invalidFlag 0 "Invalid" 1 "Valid";
VAL_ 624 CellVoltage_001_invalidFlag 0 "Invalid" 1 "Valid";
VAL_ 624 CellVoltage_002_invalidFlag 0 "Invalid" 1 "Valid";
VAL_ 624 CellVoltage_003_invalidFlag 0 "Invalid" 1 "Valid";
VAL_ 624 CellVoltage_004_invalidFlag 0 "Invalid" 1 "Valid";
VAL_ 624 CellVoltage_005_invalidFlag 0 "Invalid" 1 "Valid";
VAL_ 624 CellVoltage_006_invalidFlag 0 "Invalid" 1 "Valid";
VAL_ 624 CellVoltage_007_invalidFlag 0 "Invalid" 1 "Valid";
VAL_ 624 CellVoltage_008_invalidFlag 0 "Invalid" 1 "Valid";
VAL_ 624 CellVoltage_009_invalidFlag 0 "Invalid" 1 "Valid";
VAL_ 624 CellVoltage_010_invalidFlag 0 "Invalid" 1 "Valid";
VAL_ 624 CellVoltage_011_invalidFlag 0 "Invalid" 1 "Valid";
VAL_ 624 CellVoltage_012_invalidFlag 0 "Invalid" 1 "Valid";
VAL_ 624 CellVoltage_013_invalidFlag 0 "Invalid" 1 "Valid";
VAL_ 624 CellVoltage_014_invalidFlag 0 "Invalid" 1 "Valid";
VAL_ 624 CellVoltage_015_invalidFlag 0 "Invalid" 1 "Valid";
VAL_ 624 CellVoltage_016_invalidFlag 0 "Invalid" 1 "Valid";
VAL_ 624 CellVoltage_017_invalidFlag 0 "Invalid" 1 "Valid";
VAL_ 624 CellVoltage_018_invalidFlag 0 "Invalid" 1 "Valid";
VAL_ 624 CellVoltage_019_invalidFlag 0 "Invalid" 1 "Valid";
VAL_ 624 CellVoltage_020_invalidFlag 0 "Invalid" 1 "Valid";
VAL_ 624 CellVoltage_021_invalidFlag 0 "Invalid" 1 "Valid";
VAL_ 624 CellVoltage_022_invalidFlag 0 "Invalid" 1 "Valid";
VAL_ 624 CellVoltage_023_invalidFlag 0 "Invalid" 1 "Valid";
VAL_ 624 CellVoltage_024_invalidFlag 0 "Invalid" 1 "Valid";
VAL_ 624 CellVoltage_025_invalidFlag 0 "Invalid" 1 "Valid";
VAL_ 624 CellVoltage_026_invalidFlag 0 "Invalid" 1 "Valid";
VAL_ 624 CellVoltage_027_invalidFlag 0 "Invalid" 1 "Valid";
VAL_ 624 CellVoltage_028_invalidFlag 0 "Invalid" 1 "Valid";
VAL_ 624 CellVoltage_029_invalidFlag 0 "Invalid" 1 "Valid";
VAL_ 624 CellVoltage_030_invalidFlag 0 "Invalid" 1 "Valid";
VAL_ 624 CellVoltage_031_invalidFlag 0 "Invalid" 1 "Valid";
VAL_ 624 CellVoltage_032_invalidFlag 0 "Invalid" 1 "Valid";
VAL_ 624 CellVoltage_033_invalidFlag 0 "Invalid" 1 "Valid";
VAL_ 624 CellVoltage_034_invalidFlag 0 "Invalid" 1 "Valid";
VAL_ 624 CellVoltage_035_invalidFlag 0 "Invalid" 1 "Valid";
VAL_ 624 CellVoltage_036_invalidFlag 0 "Invalid" 1 "Valid";
VAL_ 624 CellVoltage_037_invalidFlag 0 "Invalid" 1 "Valid";
VAL_ 624 CellVoltage_038_invalidFlag 0 "Invalid" 1 "Valid";
VAL_ 624 CellVoltage_039_invalidFlag 0 "Invalid" 1 "Valid";
VAL_ 624 CellVoltage_040_invalidFlag 0 "Invalid" 1 "Valid";
VAL_ 624 CellVoltage_041_invalidFlag 0 "Invalid" 1 "Valid";
VAL_ 624 CellVoltage_042_invalidFlag 0 "Invalid" 1 "Valid";
VAL_ 624 CellVoltage_043_invalidFlag 0 "Invalid" 1 "Valid";
VAL_ 624 CellVoltage_044_invalidFlag 0 "Invalid" 1 "Valid";
VAL_ 624 CellVoltage_045_invalidFlag 0 "Invalid" 1 "Valid";
VAL_ 624 CellVoltage_046_invalidFlag 0 "Invalid" 1 "Valid";
VAL_ 624 CellVoltage_047_invalidFlag 0 "Invalid" 1 "Valid";
VAL_ 624 CellVoltage_048_invalidFlag 0 "Invalid" 1 "Valid";
VAL_ 624 CellVoltage_049_invalidFlag 0 "Invalid" 1 "Valid";
VAL_ 624 CellVoltage_050_invalidFlag 0 "Invalid" 1 "Valid";
VAL_ 624 CellVoltage_051_invalidFlag 0 "Invalid" 1 "Valid";
VAL_ 624 CellVoltage_052_invalidFlag 0 "Invalid" 1 "Valid";
VAL_ 624 CellVoltage_053_invalidFlag 0 "Invalid" 1 "Valid";
VAL_ 624 CellVoltage_054_invalidFlag 0 "Invalid" 1 "Valid";
VAL_ 624 CellVoltage_055_invalidFlag 0 "Invalid" 1 "Valid";
VAL_ 624 CellVoltage_056_invalidFlag 0 "Invalid" 1 "Valid";
VAL_ 624 CellVoltage_057_invalidFlag 0 "Invalid" 1 "Valid";
VAL_ 624 CellVoltage_058_invalidFlag 0 "Invalid" 1 "Valid";
VAL_ 624 CellVoltage_059_invalidFlag 0 "Invalid" 1 "Valid";
VAL_ 624 CellVoltage_060_invalidFlag 0 "Invalid" 1 "Valid";
VAL_ 624 CellVoltage_061_invalidFlag 0 "Invalid" 1 "Valid";
VAL_ 624 CellVoltage_062_invalidFlag 0 "Invalid" 1 "Valid";
VAL_ 624 CellVoltage_063_invalidFlag 0 "Invalid" 1 "Valid";
VAL_ 624 CellVoltage_064_invalidFlag 0 "Invalid" 1 "Valid";
VAL_ 624 CellVoltage_065_invalidFlag 0 "Invalid" 1 "Valid";
VAL_ 624 CellVoltage_066_invalidFlag 0 "Invalid" 1 "Valid";
VAL_ 624 CellVoltage_067_invalidFlag 0 "Invalid" 1 "Valid";
VAL_ 624 CellVoltage_068_invalidFlag 0 "Invalid" 1 "Valid";
VAL_ 624 CellVoltage_069_invalidFlag 0 "Invalid" 1 "Valid";
VAL_ 624 CellVoltage_070_invalidFlag 0 "Invalid" 1 "Valid";
VAL_ 624 CellVoltage_071_invalidFlag 0 "Invalid" 1 "Valid";
VAL_ 624 CellVoltage_072_invalidFlag 0 "Invalid" 1 "Valid";
VAL_ 624 CellVoltage_073_invalidFlag 0 "Invalid" 1 "Valid";
VAL_ 624 CellVoltage_074_invalidFlag 0 "Invalid" 1 "Valid";
VAL_ 624 CellVoltage_075_invalidFlag 0 "Invalid" 1 "Valid";
VAL_ 624 CellVoltage_076_invalidFlag 0 "Invalid" 1 "Valid";
VAL_ 624 CellVoltage_077_invalidFlag 0 "Invalid" 1 "Valid";
VAL_ 624 CellVoltage_078_invalidFlag 0 "Invalid" 1 "Valid";
VAL_ 624 CellVoltage_079_invalidFlag 0 "Invalid" 1 "Valid";
VAL_ 624 CellVoltage_080_invalidFlag 0 "Invalid" 1 "Valid";
VAL_ 624 CellVoltage_081_invalidFlag 0 "Invalid" 1 "Valid";
VAL_ 624 CellVoltage_082_invalidFlag 0 "Invalid" 1 "Valid";
VAL_ 624 CellVoltage_083_invalidFlag 0 "Invalid" 1 "Valid";
VAL_ 624 CellVoltage_084_invalidFlag 0 "Invalid" 1 "Valid";
VAL_ 624 CellVoltage_085_invalidFlag 0 "Invalid" 1 "Valid";
VAL_ 624 CellVoltage_086_invalidFlag 0 "Invalid" 1 "Valid";
VAL_ 624 CellVoltage_087_invalidFlag 0 "Invalid" 1 "Valid";
VAL_ 624 CellVoltage_088_invalidFlag 0 "Invalid" 1 "Valid";
VAL_ 624 CellVoltage_089_invalidFlag 0 "Invalid" 1 "Valid";
VAL_ 624 CellVoltage_090_invalidFlag 0 "Invalid" 1 "Valid";
VAL_ 624 CellVoltage_091_invalidFlag 0 "Invalid" 1 "Valid";
VAL_ 624 CellVoltage_092_invalidFlag 0 "Invalid" 1 "Valid";
VAL_ 624 CellVoltage_093_invalidFlag 0 "Invalid" 1 "Valid";
VAL_ 624 CellVoltage_094_invalidFlag 0 "Invalid" 1 "Valid";
VAL_ 624 CellVoltage_095_invalidFlag 0 "Invalid" 1 "Valid";
VAL_ 624 CellVoltage_096_invalidFlag 0 "Invalid" 1 "Valid";
VAL_ 624 CellVoltage_097_invalidFlag 0 "Invalid" 1 "Valid";
VAL_ 624 CellVoltage_098_invalidFlag 0 "Invalid" 1 "Valid";
VAL_ 624 CellVoltage_099_invalidFlag 0 "Invalid" 1 "Valid";
VAL_ 624 CellVoltage_100_invalidFlag 0 "Invalid" 1 "Valid";
VAL_ 624 CellVoltage_101_invalidFlag 0 "Invalid" 1 "Valid";
VAL_ 624 CellVoltage_102_invalidFlag 0 "Invalid" 1 "Valid";
VAL_ 624 CellVoltage_103_invalidFlag 0 "Invalid" 1 "Valid";
VAL_ 624 CellVoltage_104_invalidFlag 0 "Invalid" 1 "Valid";
VAL_ 624 CellVoltage_105_invalidFlag 0 "Invalid" 1 "Valid";
VAL_ 624 CellVoltage_106_invalidFlag 0 "Invalid" 1 "Valid";
VAL_ 624 CellVoltage_107_invalidFlag 0 "Invalid" 1 "Valid";
VAL_ 624 CellVoltage_108_invalidFlag 0 "Invalid" 1 "Valid";
VAL_ 624 CellVoltage_109_invalidFlag 0 "Invalid" 1 "Valid";
VAL_ 624 CellVoltage_110_invalidFlag 0 "Invalid" 1 "Valid";
VAL_ 624 CellVoltage_111_invalidFlag 0 "Invalid" 1 "Valid";
VAL_ 624 CellVoltage_112_invalidFlag 0 "Invalid" 1 "Valid";
VAL_ 624 CellVoltage_113_invalidFlag 0 "Invalid" 1 "Valid";
VAL_ 624 CellVoltage_114_invalidFlag 0 "Invalid" 1 "Valid";
VAL_ 624 CellVoltage_115_invalidFlag 0 "Invalid" 1 "Valid";
VAL_ 624 CellVoltage_116_invalidFlag 0 "Invalid" 1 "Valid";
VAL_ 624 CellVoltage_117_invalidFlag 0 "Invalid" 1 "Valid";
VAL_ 624 CellVoltage_118_invalidFlag 0 "Invalid" 1 "Valid";
VAL_ 624 CellVoltage_119_invalidFlag 0 "Invalid" 1 "Valid";
VAL_ 624 CellVoltage_120_invalidFlag 0 "Invalid" 1 "Valid";
VAL_ 624 CellVoltage_121_invalidFlag 0 "Invalid" 1 "Valid";
VAL_ 624 CellVoltage_122_invalidFlag 0 "Invalid" 1 "Valid";
VAL_ 624 CellVoltage_123_invalidFlag 0 "Invalid" 1 "Valid";
VAL_ 624 CellVoltage_124_invalidFlag 0 "Invalid" 1 "Valid";
VAL_ 624 CellVoltage_125_invalidFlag 0 "Invalid" 1 "Valid";
VAL_ 624 CellVoltage_126_invalidFlag 0 "Invalid" 1 "Valid";
VAL_ 624 CellVoltage_127_invalidFlag 0 "Invalid" 1 "Valid";
VAL_ 624 CellVoltage_128_invalidFlag 0 "Invalid" 1 "Valid";
VAL_ 624 CellVoltage_129_invalidFlag 0 "Invalid" 1 "Valid";
VAL_ 624 CellVoltage_130_invalidFlag 0 "Invalid" 1 "Valid";
VAL_ 624 CellVoltage_131_invalidFlag 0 "Invalid" 1 "Valid";
VAL_ 624 CellVoltage_132_invalidFlag 0 "Invalid" 1 "Valid";
VAL_ 624 CellVoltage_133_invalidFlag 0 "Invalid" 1 "Valid";
VAL_ 624 CellVoltage_134_invalidFlag 0 "Invalid" 1 "Valid";
VAL_ 624 CellVoltage_135_invalidFlag 0 "Invalid" 1 "Valid";
VAL_ 624 CellVoltage_136_invalidFlag 0 "Invalid" 1 "Valid";
VAL_ 624 CellVoltage_137_invalidFlag 0 "Invalid" 1 "Valid";
VAL_ 624 CellVoltage_138_invalidFlag 0 "Invalid" 1 "Valid";
VAL_ 624 CellVoltage_139_invalidFlag 0 "Invalid" 1 "Valid";
VAL_ 624 CellVoltage_140_invalidFlag 0 "Invalid" 1 "Valid";
VAL_ 624 CellVoltage_141_invalidFlag 0 "Invalid" 1 "Valid";
VAL_ 624 CellVoltage_142_invalidFlag 0 "Invalid" 1 "Valid";
VAL_ 624 CellVoltage_143_invalidFlag 0 "Invalid" 1 "Valid";
VAL_ 624 CellVoltage_144_invalidFlag 0 "Invalid" 1 "Valid";
VAL_ 624 CellVoltage_145_invalidFlag 0 "Invalid" 1 "Valid";
VAL_ 624 CellVoltage_146_invalidFlag 0 "Invalid" 1 "Valid";
VAL_ 624 CellVoltage_147_invalidFlag 0 "Invalid" 1 "Valid";
VAL_ 624 CellVoltage_148_invalidFlag 0 "Invalid" 1 "Valid";
VAL_ 624 CellVoltage_149_invalidFlag 0 "Invalid" 1 "Valid";
VAL_ 624 CellVoltage_150_invalidFlag 0 "Invalid" 1 "Valid";
VAL_ 624 CellVoltage_151_invalidFlag 0 "Invalid" 1 "Valid";
VAL_ 624 CellVoltage_152_invalidFlag 0 "Invalid" 1 "Valid";
VAL_ 624 CellVoltage_153_invalidFlag 0 "Invalid" 1 "Valid";
VAL_ 624 CellVoltage_154_invalidFlag 0 "Invalid" 1 "Valid";
VAL_ 624 CellVoltage_155_invalidFlag 0 "Invalid" 1 "Valid";
VAL_ 624 CellVoltage_156_invalidFlag 0 "Invalid" 1 "Valid";
VAL_ 624 CellVoltage_157_invalidFlag 0 "Invalid" 1 "Valid";
VAL_ 624 CellVoltage_158_invalidFlag 0 "Invalid" 1 "Valid";
VAL_ 624 CellVoltage_159_invalidFlag 0 "Invalid" 1 "Valid";
VAL_ 624 CellVoltage_160_invalidFlag 0 "Invalid" 1 "Valid";
VAL_ 624 CellVoltage_161_invalidFlag 0 "Invalid" 1 "Valid";
VAL_ 624 CellVoltage_162_invalidFlag 0 "Invalid" 1 "Valid";
VAL_ 624 CellVoltage_163_invalidFlag 0 "Invalid" 1 "Valid";
VAL_ 624 CellVoltage_164_invalidFlag 0 "Invalid" 1 "Valid";
VAL_ 624 CellVoltage_165_invalidFlag 0 "Invalid" 1 "Valid";
VAL_ 624 CellVoltage_166_invalidFlag 0 "Invalid" 1 "Valid";
VAL_ 624 CellVoltage_167_invalidFlag 0 "Invalid" 1 "Valid";
VAL_ 624 CellVoltage_168_invalidFlag 0 "Invalid" 1 "Valid";
VAL_ 624 CellVoltage_169_invalidFlag 0 "Invalid" 1 "Valid";
VAL_ 624 CellVoltage_170_invalidFlag 0 "Invalid" 1 "Valid";
VAL_ 624 CellVoltage_171_invalidFlag 0 "Invalid" 1 "Valid";
VAL_ 624 CellVoltage_172_invalidFlag 0 "Invalid" 1 "Valid";
VAL_ 624 CellVoltage_173_invalidFlag 0 "Invalid" 1 "Valid";
VAL_ 624 CellVoltage_174_invalidFlag 0 "Invalid" 1 "Valid";
VAL_ 624 CellVoltage_175_invalidFlag 0 "Invalid" 1 "Valid";
VAL_ 624 CellVoltage_176_invalidFlag 0 "Invalid" 1 "Valid";
VAL_ 624 CellVoltage_177_invalidFlag 0 "Invalid" 1 "Valid";
VAL_ 624 CellVoltage_178_invalidFlag 0 "Invalid" 1 "Valid";
VAL_ 624 CellVoltage_179_invalidFlag 0 "Invalid" 1 "Valid";
VAL_ 624 CellVoltage_180_invalidFlag 0 "Invalid" 1 "Valid";
VAL_ 624 CellVoltage_181_invalidFlag 0 "Invalid" 1 "Valid";
VAL_ 624 CellVoltage_182_invalidFlag 0 "Invalid" 1 "Valid";
VAL_ 624 CellVoltage_183_invalidFlag 0 "Invalid" 1 "Valid";
VAL_ 624 CellVoltage_184_invalidFlag 0 "Invalid" 1 "Valid";
VAL_ 624 CellVoltage_185_invalidFlag 0 "Invalid" 1 "Valid";
VAL_ 624 CellVoltage_186_invalidFlag 0 "Invalid" 1 "Valid";
VAL_ 624 CellVoltage_187_invalidFlag 0 "Invalid" 1 "Valid";
VAL_ 624 CellVoltage_188_invalidFlag 0 "Invalid" 1 "Valid";
VAL_ 624 CellVoltage_189_invalidFlag 0 "Invalid" 1 "Valid";
VAL_ 624 CellVoltage_190_invalidFlag 0 "Invalid" 1 "Valid";
VAL_ 624 CellVoltage_191_invalidFlag 0 "Invalid" 1 "Valid";
VAL_ 624 CellVoltage_192_invalidFlag 0 "Invalid" 1 "Valid";
VAL_ 624 CellVoltage_193_invalidFlag 0 "Invalid" 1 "Valid";
VAL_ 624 CellVoltage_194_invalidFlag 0 "Invalid" 1 "Valid";
VAL_ 624 CellVoltage_195_invalidFlag 0 "Invalid" 1 "Valid";
VAL_ 624 CellVoltage_196_invalidFlag 0 "Invalid" 1 "Valid";
VAL_ 624 CellVoltage_197_invalidFlag 0 "Invalid" 1 "Valid";
VAL_ 624 CellVoltage_198_invalidFlag 0 "Invalid" 1 "Valid";
VAL_ 624 CellVoltage_199_invalidFlag 0 "Invalid" 1 "Valid";
VAL_ 624 CellVoltage_200_invalidFlag 0 "Invalid" 1 "Valid";
VAL_ 624 CellVoltage_201_invalidFlag 0 "Invalid" 1 "Valid";
VAL_ 624 CellVoltage_202_invalidFlag 0 "Invalid" 1 "Valid";
VAL_ 624 CellVoltage_203_invalidFlag 0 "Invalid" 1 "Valid";
VAL_ 624 CellVoltage_204_invalidFlag 0 "Invalid" 1 "Valid";
VAL_ 624 CellVoltage_205_invalidFlag 0 "Invalid" 1 "Valid";
VAL_ 624 CellVoltage_206_invalidFlag 0 "Invalid" 1 "Valid";
VAL_ 624 CellVoltage_207_invalidFlag 0 "Invalid" 1 "Valid";
VAL_ 624 CellVoltage_208_invalidFlag 0 "Invalid" 1 "Valid";
VAL_ 624 CellVoltage_209_invalidFlag 0 "Invalid" 1 "Valid";
VAL_ 624 CellVoltage_210_invalidFlag 0 "Invalid" 1 "Valid";
VAL_ 624 CellVoltage_211_invalidFlag 0 "Invalid" 1 "Valid";
VAL_ 624 CellVoltage_212_invalidFlag 0 "Invalid" 1 "Valid";
VAL_ 624 CellVoltage_213_invalidFlag 0 "Invalid" 1 "Valid";
VAL_ 624 CellVoltage_214_invalidFlag 0 "Invalid" 1 "Valid";
VAL_ 624 CellVoltage_215_invalidFlag 0 "Invalid" 1 "Valid";
VAL_ 1319 IVT_ID_Result_As 6 "Vt_Result_As";
VAL_ 1313 IVT_ID_Result_I 0 "Vt_Result_I";
VAL_ 1320 IVT_ID_Result_Wh 7 "Vt_Result_Wh";
VAL_ 1318 IVT_ID_Result_W 5 "Vt_Result_W";
VAL_ 1317 IVT_ID_Result_T 4 "Vt_Result_T";
VAL_ 1314 IVT_ID_Result_U1 1 "Vt_Result_U1";
VAL_ 1315 IVT_ID_Result_U2 2 "Vt_Result_U2";
VAL_ 1316 IVT_ID_Result_U3 3 "Vt_Result_U3";
VAL_ 546 FatalErrorCode 0 "DIAG_ID_SYSTEM_MONITORING" 1 "DIAG_ID_AFE_SPI" 2 "DIAG_ID_AFE_COMMUNICATION_INTEGRITY" 3 "DIAG_ID_AFE_MUX" 4 "DIAG_ID_AFE_CONFIG" 5 "DIAG_ID_CAN_TIMING" 6 "DIAG_ID_CAN_RX_QUEUE_FULL" 7 "DIAG_ID_CAN_TX_QUEUE_FULL" 8 "DIAG_ID_CURRENT_SENSOR_CC_RESPONDING" 9 "DIAG_ID_CURRENT_SENSOR_EC_RESPONDING" 10 "DIAG_ID_CURRENT_SENSOR_RESPONDING" 11 "DIAG_ID_REDUNDANCY_CELL_VOLTAGE" 12 "DIAG_ID_AFE_CELL_VOLTAGE_MEAS_ERROR" 13 "DIAG_ID_AFE_CELL_TEMPERATURE_MEAS_ERROR" 14 "DIAG_ID_REDUNDANCY_CELL_TEMPERATURE" 15 "DIAG_ID_BMS_VALUES_CELL_VOLTAGE_SPREAD" 16 "DIAG_ID_BMS_VALUES_CELL_TEMPERATURE_SPREAD" 17 "DIAG_ID_CELL_VOLTAGE_OVERVOLTAGE_MSL" 18 "DIAG_ID_CELL_VOLTAGE_OVERVOLTAGE_RSL" 19 "DIAG_ID_CELL_VOLTAGE_OVERVOLTAGE_MOL" 20 "DIAG_ID_CELL_VOLTAGE_UNDERVOLTAGE_MSL" 21 "DIAG_ID_CELL_VOLTAGE_UNDERVOLTAGE_RSL" 22 "DIAG_ID_CELL_VOLTAGE_UNDERVOLTAGE_MOL" 23 "DIAG_ID_TEMP_OVERTEMPERATURE_CHARGE_MSL" 24 "DIAG_ID_TEMP_OVERTEMPERATURE_CHARGE_RSL" 25 "DIAG_ID_TEMP_OVERTEMPERATURE_CHARGE_MOL" 26 "DIAG_ID_TEMP_OVERTEMPERATURE_DISCHARGE_MSL"
27 "DIAG_ID_TEMP_OVERTEMPERATURE_DISCHARGE_RSL" 28 "DIAG_ID_TEMP_OVERTEMPERATURE_DISCHARGE_MOL" 29 "DIAG_ID_TEMP_UNDERTEMPERATURE_CHARGE_MSL" 30 "DIAG_ID_TEMP_UNDERTEMPERATURE_CHARGE_RSL" 31 "DIAG_ID_TEMP_UNDERTEMPERATURE_CHARGE_MOL" 32 "DIAG_ID_TEMP_UNDERTEMPERATURE_DISCHARGE_MSL" 33 "DIAG_ID_TEMP_UNDERTEMPERATURE_DISCHARGE_RSL" 34 "DIAG_ID_TEMP_UNDERTEMPERATURE_DISCHARGE_MOL" 35 "DIAG_ID_OVERCURRENT_CHARGE_CELL_MSL" 36 "DIAG_ID_OVERCURRENT_CHARGE_CELL_RSL" 37 "DIAG_ID_OVERCURRENT_CHARGE_CELL_MOL" 38 "DIAG_ID_OVERCURRENT_DISCHARGE_CELL_MSL" 39 "DIAG_ID_OVERCURRENT_DISCHARGE_CELL_RSL" 40 "DIAG_ID_OVERCURRENT_DISCHARGE_CELL_MOL" 41 "DIAG_ID_STRING_OVERCURRENT_CHARGE_MSL" 42 "DIAG_ID_STRING_OVERCURRENT_CHARGE_RSL" 43 "DIAG_ID_STRING_OVERCURRENT_CHARGE_MOL" 44 "DIAG_ID_STRING_OVERCURRENT_DISCHARGE_MSL" 45 "DIAG_ID_STRING_OVERCURRENT_DISCHARGE_RSL" 46 "DIAG_ID_STRING_OVERCURRENT_DISCHARGE_MOL" 47 "DIAG_ID_PACK_OVERCURRENT_CHARGE_MSL" 48 "DIAG_ID_PACK_OVERCURRENT_DISCHARGE_MSL" 49 "DIAG_ID_CURRENT_ON_OPEN_STRING"
50 "DIAG_ID_DEEP_DISCHARGE_DETECTED" 51 "DIAG_ID_AFE_OPEN_WIRE" 52 "DIAG_ID_BMS_VALUES_PACK_VOLTAGE" 53 "DIAG_ID_INTERLOCK_FEEDBACK" 54 "DIAG_ID_STRING_MINUS_CONTACTOR_FEEDBACK" 55 "DIAG_ID_STRING_PLUS_CONTACTOR_FEEDBACK" 56 "DIAG_ID_PRECHARGE_CONTACTOR_FEEDBACK" 57 "DIAG_ID_SBC_FIN_ERROR" 58 "DIAG_ID_SBC_RSTB_ERROR" 59 "DIAG_ID_BASE_CELL_VOLTAGE_MEASUREMENT_TIMEOUT" 60 "DIAG_ID_REDUNDANCY0_CELL_VOLTAGE_MEASUREMENT_TIMEOUT" 61 "DIAG_ID_BASE_CELL_TEMPERATURE_MEASUREMENT_TIMEOUT" 62 "DIAG_ID_REDUNDANCY0_CELL_TEMPERATURE_MEASUREMENT_TIMEOUT" 63 "DIAG_ID_PRECHARGE_ABORT_REASON_VOLTAGE" 64 "DIAG_ID_PRECHARGE_ABORT_REASON_CURRENT" 65 "DIAG_ID_CURRENT_MEASUREMENT_TIMEOUT" 66 "DIAG_ID_CURRENT_MEASUREMENT_ERROR" 67 "DIAG_ID_CURRENT_SENSOR_V1_MEASUREMENT_TIMEOUT" 68 "DIAG_ID_CURRENT_SENSOR_V2_MEASUREMENT_TIMEOUT" 69 "DIAG_ID_CURRENT_SENSOR_V3_MEASUREMENT_TIMEOUT" 70 "DIAG_ID_CURRENT_SENSOR_POWER_MEASUREMENT_TIMEOUT" 71 "DIAG_ID_POWER_MEASUREMENT_ERROR" 72 "DIAG_ID_INSULATION_MEASUREMENT_VALID" 73 "DIAG_ID_LOW_INSULATION_RESISTANCE_ERROR"
74 "DIAG_ID_LOW_INSULATION_RESISTANCE_WARNING" 75 "DIAG_ID_INSULATION_GROUND_ERROR" 76 "DIAG_ID_I2C_PEX_ERROR" 77 "DIAG_ID_I2C_RTC_ERROR" 78 "DIAG_ID_RTC_CLOCK_INTEGRITY_ERROR" 79 "DIAG_ID_RTC_BATTERY_LOW_ERROR" 80 "DIAG_ID_FRAM_READ_CRC_ERROR" 81 "DIAG_ID_ALERT_MODE" 82 "DIAG_ID_AEROSOL_ALERT" 83 "DIAG_ID_SUPPLY_VOLTAGE_CLAMP_30C_LOST" 84 "DIAG_ID_AFE_ALARM";
VAL_ 544 BmsState 0 "UNINITIALIZED" 1 "INITIALIZATION" 2 "INITIALIZED" 3 "IDLE" 4 "OPEN_CONTACTORS" 5 "STANDBY" 6 "PRECHARGE" 7 "NORMAL" 8 "DISCHARGE" 9 "CHARGE" 10 "ERROR" 11 "UNDEFINED";
VAL_ 544 GeneralError 0 "No Error" 1 "Error";
VAL_ 544 GeneralWarning 0 "No Warning" 1 "Warning";
VAL_ 544 McuDieTemperatureError 0 "No Error" 1 "Error";
VAL_ 544 BmsMasterPcbOvertemperatureError 0 "No Error" 1 "Error";
VAL_ 544 BmsMasterPcbUndertemperatureErro 0 "No Error" 1 "Error";
VAL_ 544 PrechargeVoltageError 0 "No Error" 1 "Error";
VAL_ 544 PrechargeCurrentError 0 "No Error" 1 "Error";
VAL_ 544 HeaterState 0 "Inactive" 1 "Active";
VAL_ 544 CoolingState 0 "Inactive" 1 "Active";
VAL_ 544 InsulationMonitoring 0 "Inactive" 1 "Active";
VAL_ 544 ChargingComplete 0 "Incomplete" 1 "Complete";
VAL_ 544 EmergencyShutoff 0 "Inactive" 1 "Active";
VAL_ 544 MainFuseBlown 0 "Fuse okay" 1 "Fuse blown";
VAL_ 544 InterlockState 0 "Closed" 1 "Open";
VAL_ 544 InsulationError 0 "No Error" 1 "Error";
VAL_ 544 CanTimingError 0 "No Error" 1 "Error";
VAL_ 544 PackOvercurrentChargeError 0 "No Error" 1 "Error";
VAL_ 544 PackOvercurrentDischargeError 0 "No Error" 1 "Error";
VAL_ 544 SystemMonitoringError 0 "No Error" 1 "Error";
VAL_ 544 AlertFlag 0 "No Alert" 1 "Alert";
VAL_ 544 NvramCrcError 0 "No Error" 1 "Error";
VAL_ 544 BmsSubstate 0 "ENTRY" 1 "CHECK_ERROR_FLAGS_INTERLOCK" 2 "INTERLOCK_CHECKED" 3 "CHECK_STATE_REQUESTS" 4 "CHECK_BALANCING_REQUESTS" 5 "CHECK_ERROR_FLAGS" 6 "CHECK_CONTACTOR_NORMAL_STATE" 7 "CHECK_CONTACTOR_CHARGE_STATE" 8 "PRECHARGE_CLOSE_MINUS" 9 "PRECHARGE_CLOSE_PRECHARGE" 10 "PRECHARGE_CHECK_VOLTAGES" 11 "PRECHARGE_OPEN_PRECHARGE" 12 "PRECHARGE_CHECK_OPEN_PRECHARGE" 13 "OPEN_FIRST_CONTACTOR" 14 "OPEN_SECOND_CONTACTOR_MINUS" 15 "OPEN_SECOND_CONTACTOR_PLUS" 16 "CHECK_CLOSE_SECOND_STRING_CONTACOTR_PRECHARGE_STATE" 17 "CHECK_ERROR_FLAGS_PRECHARGE" 18 "CHECK_ERROR_FLAGS_PRECHARGE_FIRST_STRING" 19 "PRECHARGE_CLOSE_NEXT_STRING" 20 "CLOSE_SECOND_CONTACOR_PLUS" 21 "CHECK_STRING_CLOSED" 22 "CHECK_ERROR_FLAGS_PRECHARGE_CLOSING_STRINGS" 23 "CHECK_ERROR_FLAGS_CLOSING_PRECHARGE" 24 "NORMAL_CLOSE_NEXT_STRING" 25 "NORMAL_CLOSE_SECOND_STRING_CONTACTOR" 26 "OPEN_ALL_PRECHARGE_CONTACTORS" 27 "CHECK_ALL_PRECHARGE_CONTACTORS_OPEN" 28 "OPEN_STRINGS_ENTRY" 29 "OPEN_FIRST_STRING_CONTACTOR" 30 "OPEN_SECOND_STRING_CONTACTOR" 31 "CHECK_SECOND_STRING_CONTACTOR"
32 "OPEN_STRINGS_EXIT";
VAL_ 544 Clamp30cError 0 "No Error" 1 "Error";
VAL_ 544 BalancingAlgorithmState 0 "BALANCING_NOT_ALLOWED" 1 "BALANCING_ALLOWED";
VAL_ 544 BmsChargingFlag 0 "No" 1 "Yes";
VAL_ 545 TimingViolationEngineTask 0 "No Error" 1 "Error";
VAL_ 545 TimingViolation1msTask 0 "No Error" 1 "Error";
VAL_ 545 TimingViolation10msTask 0 "No Error" 1 "Error";
VAL_ 545 TimingViolation100msTask 0 "No Error" 1 "Error";
VAL_ 545 TimingViolation100msAlgoTask 0 "No Error" 1 "Error";
VAL_ 545 TimingViolation10msTaskRecorded 0 "No Error" 1 "Error";
VAL_ 545 TimingViolation100msTaskRecorded 0 "No Error" 1 "Error";
VAL_ 545 TimingViolation100msAlgoTaskReco 0 "No Error" 1 "Error";
VAL_ 545 TimingViolationEngineTaskRecorde 0 "No Error" 1 "Error";
VAL_ 545 TimingViolation1msTaskRecorded 0 "No Error" 1 "Error";
VAL_ 528 RequestBmsMode 0 "Standby" 1 "Discharge" 2 "Charge";
VAL_ 528 IndicatePrechargeType 0 "INTERNAL" 1 "EXTERNAL";
VAL_ 528 ChargerConnected 0 "No" 1 "Yes";
VAL_ 1040 DirtyFlag 0 "No" 1 "Yes";
VAL_ 1040 ReleaseDistanceOverflow 0 "No" 1 "Yes";
VAL_ 1040 UnderVersionControl 0 "No" 1 "Yes";
